VERSION "dbc-export 1 2026.26.6.5"

NS_ :

BS_:

BU_: ADSP APB APP APS APSB BB BMS CC CMP CMPD CP DAS DI DIF DIR DPB EPAS3P EPAS3S EPASTP EPASTS EPBL EPBR ESP EVSE FC GTW HCML HCMR HVP IBST ICR IDB LS OCS1P PARK PCS PCS2 PM PMF PMR PNCD PTC RADC RCM RCM2 RCM3 RCU SCCM SCM SCS SDCR TAS TCU TCU2 TPMS TRCM UI UIS UMC USM V2G VC VCBATT VCBATT0 VCBATT1 VCBATT2 VCCC VCFRONT VCFRONT1 VCFRONT2 VCLEFT VCRIGHT VCSEAT2L VCSEAT2R VCSEC VEH

BO_ 845 APSB_warningMatrix0: 8 APSB
 SG_ APSB_w001_DEPRECATED : 0|1@1+ (1,0) [0|1] "" Vector__XXX
 SG_ APSB_w002_ldwDisabled : 1|1@1+ (1,0) [0|1] "" Vector__XXX
 SG_ APSB_w003_isaDisabled : 2|1@1+ (1,0) [0|1] "" Vector__XXX
 SG_ APSB_w004_accDisabled : 3|1@1+ (1,0) [0|1] "" Vector__XXX
 SG_ APSB_w005_fcwCancelled : 4|1@1+ (1,0) [0|1] "" Vector__XXX
 SG_ APSB_w006_aebCancelled : 5|1@1+ (1,0) [0|1] "" Vector__XXX
 SG_ APSB_w007_ahlbDisabled : 6|1@1+ (1,0) [0|1] "" Vector__XXX
 SG_ APSB_w008_parkDisabled : 7|1@1+ (1,0) [0|1] "" Vector__XXX
 SG_ APSB_w009_aebFault : 8|1@1+ (1,0) [0|1] "" Vector__XXX
 SG_ APSB_w010_radcCalibIssue : 9|1@1+ (1,0) [0|1] "" Vector__XXX
 SG_ APSB_w011_scaEvent : 10|1@1+ (1,0) [0|1] "" Vector__XXX
 SG_ APSB_w012_Cam_BootFailure : 11|1@1+ (1,0) [0|1] "" Vector__XXX
 SG_ APSB_w013_Cam_Watchdog : 12|1@1+ (1,0) [0|1] "" Vector__XXX
 SG_ APSB_w014_swAssert : 13|1@1+ (1,0) [0|1] "" Vector__XXX
 SG_ APSB_w015_Camera_Failsafes : 14|1@1+ (1,0) [0|1] "" Vector__XXX
 SG_ APSB_w016_aeb_e_event : 15|1@1+ (1,0) [0|1] "" Vector__XXX
 SG_ APSB_w017_Cam_Msg_MIA : 16|1@1+ (1,0) [0|1] "" Vector__XXX
 SG_ APSB_w018_ECU_Power_Issue : 17|1@1+ (1,0) [0|1] "" Vector__XXX
 SG_ APSB_w019_ECU_Stack_Overflow : 18|1@1+ (1,0) [0|1] "" Vector__XXX
 SG_ APSB_w020_ECU_checkstopError : 19|1@1+ (1,0) [0|1] "" Vector__XXX
 SG_ APSB_w021_ECU_Temperature_Issue : 20|1@1+ (1,0) [0|1] "" Vector__XXX
 SG_ APSB_w022_ECU_EEPROM_Failure : 21|1@1+ (1,0) [0|1] "" Vector__XXX
 SG_ APSB_w023_ECU_Cam_Statemismatc : 22|1@1+ (1,0) [0|1] "" Vector__XXX
 SG_ APSB_w024_ECU_Watchdog_Reset : 23|1@1+ (1,0) [0|1] "" Vector__XXX
 SG_ APSB_w025_LC_Steering_Override : 24|1@1+ (1,0) [0|1] "" Vector__XXX
 SG_ APSB_w026_ECU_timingIssue : 25|1@1+ (1,0) [0|1] "" Vector__XXX
 SG_ APSB_w027_ECU_Reset_Fault : 26|1@1+ (1,0) [0|1] "" Vector__XXX
 SG_ APSB_w028_spi_rx_error : 27|1@1+ (1,0) [0|1] "" Vector__XXX
 SG_ APSB_w029_spi_tx_error : 28|1@1+ (1,0) [0|1] "" Vector__XXX
 SG_ APSB_w030_Heater_Issue : 29|1@1+ (1,0) [0|1] "" Vector__XXX
 SG_ APSB_w031_canRxError : 30|1@1+ (1,0) [0|1] "" Vector__XXX
 SG_ APSB_w032_canTxError : 31|1@1+ (1,0) [0|1] "" Vector__XXX
 SG_ APSB_w033_gtwMia : 32|1@1+ (1,0) [0|1] "" Vector__XXX
 SG_ APSB_w034_sccmMia : 33|1@1+ (1,0) [0|1] "" Vector__XXX
 SG_ APSB_w035_espMia : 34|1@1+ (1,0) [0|1] "" Vector__XXX
 SG_ APSB_w036_bdyMia : 35|1@1+ (1,0) [0|1] "" Vector__XXX
 SG_ APSB_w037_camTacIssue : 36|1@1+ (1,0) [0|1] "" Vector__XXX
 SG_ APSB_w038_camFailure : 37|1@1+ (1,0) [0|1] "" Vector__XXX
 SG_ APSB_w039_sdm_rcm_Mia : 38|1@1+ (1,0) [0|1] "" Vector__XXX
 SG_ APSB_w040_autopilotAngleSaturate : 39|1@1+ (1,0) [0|1] "" Vector__XXX
 SG_ APSB_w041_autopilotRateSaturated : 40|1@1+ (1,0) [0|1] "" Vector__XXX
 SG_ APSB_w042_autopilotAborting : 41|1@1+ (1,0) [0|1] "" Vector__XXX
 SG_ APSB_w043_camLongRunTime : 42|1@1+ (1,0) [0|1] "" Vector__XXX
 SG_ APSB_w044_appMobileyeFailure : 43|1@1+ (1,0) [0|1] "" Vector__XXX
 SG_ APSB_w045_radMia : 44|1@1+ (1,0) [0|1] "" Vector__XXX
 SG_ APSB_w046_eepromRecordAbsent : 45|1@1+ (1,0) [0|1] "" Vector__XXX
 SG_ APSB_w047_edrEvent : 46|1@1+ (1,0) [0|1] "" Vector__XXX
 SG_ APSB_w048_DAS_Features_Disabled : 47|1@1+ (1,0) [0|1] "" Vector__XXX
 SG_ APSB_w049_eyeqVersionMismatch : 48|1@1+ (1,0) [0|1] "" Vector__XXX
 SG_ APSB_w050_aeb_event : 49|1@1+ (1,0) [0|1] "" Vector__XXX
 SG_ APSB_w051_radcEcuIssue : 50|1@1+ (1,0) [0|1] "" Vector__XXX
 SG_ APSB_w052_radcSensorIssue : 51|1@1+ (1,0) [0|1] "" Vector__XXX
 SG_ APSB_w053_radcCommIssue : 52|1@1+ (1,0) [0|1] "" Vector__XXX
 SG_ APSB_w054_camAutofix : 53|1@1+ (1,0) [0|1] "" Vector__XXX
 SG_ APSB_w055_radcVersionMismatch : 54|1@1+ (1,0) [0|1] "" Vector__XXX
 SG_ APSB_w056_diMia : 55|1@1+ (1,0) [0|1] "" Vector__XXX
 SG_ APSB_w057_mcuMia : 56|1@1+ (1,0) [0|1] "" Vector__XXX
 SG_ APSB_w058_epbMia : 57|1@1+ (1,0) [0|1] "" Vector__XXX
 SG_ APSB_w059_parkMia : 58|1@1+ (1,0) [0|1] "" Vector__XXX
 SG_ APSB_w060_fcw_event : 59|1@1+ (1,0) [0|1] "" Vector__XXX
 SG_ APSB_w061_tasMia : 60|1@1+ (1,0) [0|1] "" Vector__XXX
 SG_ APSB_w062_radcAlignment : 61|1@1+ (1,0) [0|1] "" Vector__XXX
 SG_ APSB_w063_parkVersionMismatch : 62|1@1+ (1,0) [0|1] "" Vector__XXX
 SG_ APSB_w064_epasMia : 63|1@1+ (1,0) [0|1] "" Vector__XXX

BO_ 1143 APSB_warningMatrix1: 8 APSB
 SG_ APSB_w065_deserializerOvercurren : 0|1@1+ (1,0) [0|1] "" Vector__XXX
 SG_ APSB_w066_deserializerLockLost : 1|1@1+ (1,0) [0|1] "" Vector__XXX
 SG_ APSB_w067_steeringAlignment : 2|1@1+ (1,0) [0|1] "" Vector__XXX
 SG_ APSB_w068_vlInconsistency : 3|1@1+ (1,0) [0|1] "" Vector__XXX
 SG_ APSB_w069_apcSpaceMasked : 4|1@1+ (1,0) [0|1] "" Vector__XXX
 SG_ APSB_w070_apcIncompleteCal : 5|1@1+ (1,0) [0|1] "" Vector__XXX
 SG_ APSB_w071_selfparkStarted : 6|1@1+ (1,0) [0|1] "" Vector__XXX
 SG_ APSB_w072_selfparkComplete : 7|1@1+ (1,0) [0|1] "" Vector__XXX
 SG_ APSB_w073_issueEscalatedLDW : 8|1@1+ (1,0) [0|1] "" Vector__XXX
 SG_ APSB_w074_inPathStationaryObst : 9|1@1+ (1,0) [0|1] "" Vector__XXX
 SG_ APSB_w075_scMia : 10|1@1+ (1,0) [0|1] "" Vector__XXX
 SG_ APSB_w076_mobilEyeSetC : 11|1@1+ (1,0) [0|1] "" Vector__XXX
 SG_ APSB_w077_pmmActive : 12|1@1+ (1,0) [0|1] "" Vector__XXX
 SG_ APSB_w078_pmmActive2 : 13|1@1+ (1,0) [0|1] "" Vector__XXX
 SG_ APSB_w079_edrAvailable : 14|1@1+ (1,0) [0|1] "" Vector__XXX
 SG_ APSB_w080_accFailedActivation : 15|1@1+ (1,0) [0|1] "" Vector__XXX
 SG_ APSB_w081_pmmActiveBraking : 16|1@1+ (1,0) [0|1] "" Vector__XXX
 SG_ APSB_w082_inPathFSviolation : 17|1@1+ (1,0) [0|1] "" Vector__XXX
 SG_ APSB_w083_inPathRADObject : 18|1@1+ (1,0) [0|1] "" Vector__XXX
 SG_ APSB_w084_pmmIPSO : 19|1@1+ (1,0) [0|1] "" Vector__XXX
 SG_ APSB_w085_pmmSteering : 20|1@1+ (1,0) [0|1] "" Vector__XXX
 SG_ APSB_w086_robCollision : 21|1@1+ (1,0) [0|1] "" Vector__XXX
 SG_ APSB_w087_DEPRECATED : 22|1@1+ (1,0) [0|1] "" Vector__XXX
 SG_ APSB_w088_DEPRECATED : 23|1@1+ (1,0) [0|1] "" Vector__XXX
 SG_ APSB_w089_DEPRECATED : 24|1@1+ (1,0) [0|1] "" Vector__XXX
 SG_ APSB_w090_DEPRECATED : 25|1@1+ (1,0) [0|1] "" Vector__XXX
 SG_ APSB_w091_DEPRECATED : 26|1@1+ (1,0) [0|1] "" Vector__XXX
 SG_ APSB_w092_DEPRECATED : 27|1@1+ (1,0) [0|1] "" Vector__XXX
 SG_ APSB_w093_DEPRECATED : 28|1@1+ (1,0) [0|1] "" Vector__XXX
 SG_ APSB_w094_DEPRECATED : 29|1@1+ (1,0) [0|1] "" Vector__XXX
 SG_ APSB_w095_DEPRECATED : 30|1@1+ (1,0) [0|1] "" Vector__XXX
 SG_ APSB_w096_DEPRECATED : 31|1@1+ (1,0) [0|1] "" Vector__XXX
 SG_ APSB_w097_DEPRECATED : 32|1@1+ (1,0) [0|1] "" Vector__XXX
 SG_ APSB_w098_DEPRECATED : 33|1@1+ (1,0) [0|1] "" Vector__XXX
 SG_ APSB_w099_DEPRECATED : 34|1@1+ (1,0) [0|1] "" Vector__XXX
 SG_ APSB_w100_DEPRECATED : 35|1@1+ (1,0) [0|1] "" Vector__XXX
 SG_ APSB_w101_DEPRECATED : 36|1@1+ (1,0) [0|1] "" Vector__XXX
 SG_ APSB_w102_DEPRECATED : 37|1@1+ (1,0) [0|1] "" Vector__XXX
 SG_ APSB_w103_robExperimentalAEB : 38|1@1+ (1,0) [0|1] "" Vector__XXX
 SG_ APSB_w104_DEPRECATED : 39|1@1+ (1,0) [0|1] "" Vector__XXX
 SG_ APSB_w105_DEPRECATED : 40|1@1+ (1,0) [0|1] "" Vector__XXX
 SG_ APSB_w106_torsionBarOffset : 41|1@1+ (1,0) [0|1] "" Vector__XXX

BO_ 942 APSB_warningMatrix2: 8 APSB
 SG_ APSB_w129_ECU_Power_Issue : 0|1@1+ (1,0) [0|1] "" Vector__XXX
 SG_ APSB_w130_ECU_Thermal_Issue : 1|1@1+ (1,0) [0|1] "" Vector__XXX
 SG_ APSB_w131_trap_exception : 2|1@1+ (1,0) [0|1] "" Vector__XXX
 SG_ APSB_w132_appVersionMismatch : 3|1@1+ (1,0) [0|1] "" Vector__XXX
 SG_ APSB_w133_ETHSwitchError : 4|1@1+ (1,0) [0|1] "" Vector__XXX
 SG_ APSB_w134_appMia : 5|1@1+ (1,0) [0|1] "" Vector__XXX
 SG_ APSB_w135_appCritical : 6|1@1+ (1,0) [0|1] "" Vector__XXX
 SG_ APSB_w136_gpsDisabled : 7|1@1+ (1,0) [0|1] "" Vector__XXX
 SG_ APSB_w137_gpsFaultReset : 8|1@1+ (1,0) [0|1] "" Vector__XXX
 SG_ APSB_w138_gpsComIssue : 9|1@1+ (1,0) [0|1] "" Vector__XXX
 SG_ APSB_w139_udpBufferOverflow : 10|1@1+ (1,0) [0|1] "" Vector__XXX
 SG_ APSB_w140_vcfrontMiaVehicleBus : 11|1@1+ (1,0) [0|1] "" Vector__XXX
 SG_ APSB_w141_rcmMiaPartyBus : 12|1@1+ (1,0) [0|1] "" Vector__XXX
 SG_ APSB_w142_diMiaPartyBus : 13|1@1+ (1,0) [0|1] "" Vector__XXX
 SG_ APSB_w143_espMiaPartyBus : 14|1@1+ (1,0) [0|1] "" Vector__XXX
 SG_ APSB_w144_vcleftMiaPartyBus : 15|1@1+ (1,0) [0|1] "" Vector__XXX
 SG_ APSB_w145_vcrightMiaPartyBus : 16|1@1+ (1,0) [0|1] "" Vector__XXX
 SG_ APSB_w146_epas3pMiaPartyBus : 17|1@1+ (1,0) [0|1] "" Vector__XXX
 SG_ APSB_w147_vcleftMiaVehBus : 18|1@1+ (1,0) [0|1] "" Vector__XXX
 SG_ APSB_w148_vcrightMiaVehBus : 19|1@1+ (1,0) [0|1] "" Vector__XXX
 SG_ APSB_w149_epblMiaVehBus : 20|1@1+ (1,0) [0|1] "" Vector__XXX
 SG_ APSB_w150_sccmMiaVehBus : 21|1@1+ (1,0) [0|1] "" Vector__XXX
 SG_ APSB_w151_apRecovered : 22|1@1+ (1,0) [0|1] "" Vector__XXX
 SG_ APSB_w152_gpsFusionStatus : 23|1@1+ (1,0) [0|1] "" Vector__XXX
 SG_ APSB_w153_eacInhibit : 24|1@1+ (1,0) [0|1] "" Vector__XXX
 SG_ APSB_w155_ethLwipError : 26|1@1+ (1,0) [0|1] "" Vector__XXX
 SG_ APSB_w156_lwipAssert : 27|1@1+ (1,0) [0|1] "" Vector__XXX
 SG_ APSB_w157_autopilotReboot : 28|1@1+ (1,0) [0|1] "" Vector__XXX
 SG_ APSB_w158_apbMia : 29|1@1+ (1,0) [0|1] "" Vector__XXX
 SG_ APSB_w159_apbCritical : 30|1@1+ (1,0) [0|1] "" Vector__XXX
 SG_ APSB_w160_apbVersionMismatch : 31|1@1+ (1,0) [0|1] "" Vector__XXX
 SG_ APSB_w161_gpsAntennaDisconnected : 32|1@1+ (1,0) [0|1] "" Vector__XXX
 SG_ APSB_w162_TurboA_DisRegPgoodErr : 33|1@1+ (1,0) [0|1] "" Vector__XXX
 SG_ APSB_w163_TurboA_DisRegNFault : 34|1@1+ (1,0) [0|1] "" Vector__XXX
 SG_ APSB_w164_TurboA_12VFuseFault : 35|1@1+ (1,0) [0|1] "" Vector__XXX
 SG_ APSB_w165_TurboA_Temp_NOS : 36|1@1+ (1,0) [0|1] "" Vector__XXX
 SG_ APSB_w166_TurboA_SMSLockStepErr : 37|1@1+ (1,0) [0|1] "" Vector__XXX
 SG_ APSB_w167_TurboA_TMU_Throttle : 38|1@1+ (1,0) [0|1] "" Vector__XXX
 SG_ APSB_w168_TurboA_SMS_WDOG : 39|1@1+ (1,0) [0|1] "" Vector__XXX
 SG_ APSB_w169_TurboA_SCS_LKUP : 40|1@1+ (1,0) [0|1] "" Vector__XXX
 SG_ APSB_w170_TurboA_A72_watchdog : 41|1@1+ (1,0) [0|1] "" Vector__XXX
 SG_ APSB_w171_TurboA_SMS_taskUtilErr : 42|1@1+ (1,0) [0|1] "" Vector__XXX
 SG_ APSB_w172_apFeaturesUnavailable : 43|1@1+ (1,0) [0|1] "" Vector__XXX
 SG_ APSB_w178_TurboB_DisRegPgoodErr : 49|1@1+ (1,0) [0|1] "" Vector__XXX
 SG_ APSB_w179_TurboB_DisRegNFault : 50|1@1+ (1,0) [0|1] "" Vector__XXX
 SG_ APSB_w180_TurboB_12VFuseFault : 51|1@1+ (1,0) [0|1] "" Vector__XXX
 SG_ APSB_w181_TurboB_Temp_NOS : 52|1@1+ (1,0) [0|1] "" Vector__XXX
 SG_ APSB_w182_TurboB_SMSLockStepErr : 53|1@1+ (1,0) [0|1] "" Vector__XXX
 SG_ APSB_w183_TurboB_TMU_Throttle : 54|1@1+ (1,0) [0|1] "" Vector__XXX
 SG_ APSB_w184_TurboB_SMS_WDOG : 55|1@1+ (1,0) [0|1] "" Vector__XXX
 SG_ APSB_w185_TurboB_SCS_LKUP : 56|1@1+ (1,0) [0|1] "" Vector__XXX
 SG_ APSB_w186_TurboB_A72_watchdog : 57|1@1+ (1,0) [0|1] "" Vector__XXX
 SG_ APSB_w187_TurboB_SMS_taskUtilErr : 58|1@1+ (1,0) [0|1] "" Vector__XXX
 SG_ APSB_w188_otherTurboUartMIA : 59|1@1+ (1,0) [0|1] "" Vector__XXX
 SG_ APSB_w189_vcfrontMiaPartyBus : 60|1@1+ (1,0) [0|1] "" Vector__XXX
 SG_ APSB_w190_iboosterMia : 61|1@1+ (1,0) [0|1] "" Vector__XXX
 SG_ APSB_w191_timesyncError : 62|1@1+ (1,0) [0|1] "" Vector__XXX
 SG_ APSB_w192_CANFault : 63|1@1+ (1,0) [0|1] "" Vector__XXX

BO_ 976 APSB_warningMatrix3: 8 APSB
 SG_ APSB_w193_camWindshieldUnclean : 0|1@1+ (1,0) [0|1] "" Vector__XXX
 SG_ APSB_w194_accDriverResumeRqrd : 1|1@1+ (1,0) [0|1] "" Vector__XXX
 SG_ APSB_w195_scwUnavailable : 2|1@1+ (1,0) [0|1] "" Vector__XXX
 SG_ APSB_w196_stopSignWarning : 3|1@1+ (1,0) [0|1] "" Vector__XXX
 SG_ APSB_w197_redLightWarning : 4|1@1+ (1,0) [0|1] "" Vector__XXX
 SG_ APSB_w198_tsrUnavailable : 5|1@1+ (1,0) [0|1] "" Vector__XXX
 SG_ APSB_w199_apcAbort : 6|1@1+ (1,0) [0|1] "" Vector__XXX
 SG_ APSB_w200_lcSlowdown : 7|1@1+ (1,0) [0|1] "" Vector__XXX
 SG_ APSB_w201_lcAborting : 8|1@1+ (1,0) [0|1] "" Vector__XXX
 SG_ APSB_w202_scwNoisyEnvironment : 9|1@1+ (1,0) [0|1] "" Vector__XXX
 SG_ APSB_w203_apcActivation : 10|1@1+ (1,0) [0|1] "" Vector__XXX
 SG_ APSB_w204_apcFinalFront : 11|1@1+ (1,0) [0|1] "" Vector__XXX
 SG_ APSB_w205_apcFinalRear : 12|1@1+ (1,0) [0|1] "" Vector__XXX
 SG_ APSB_w206_autosteerNotEnabled : 13|1@1+ (1,0) [0|1] "" Vector__XXX
 SG_ APSB_w207_autosteerUnavailable : 14|1@1+ (1,0) [0|1] "" Vector__XXX
 SG_ APSB_w208_rackDetected : 15|1@1+ (1,0) [0|1] "" Vector__XXX
 SG_ APSB_w209_autoSummonRequest : 16|1@1+ (1,0) [0|1] "" Vector__XXX
 SG_ APSB_w210_camObstrcted : 17|1@1+ (1,0) [0|1] "" Vector__XXX
 SG_ APSB_w211_accNoSeatBelt : 18|1@1+ (1,0) [0|1] "" Vector__XXX
 SG_ APSB_w212_lcUnavailableStrikeOut : 19|1@1+ (1,0) [0|1] "" Vector__XXX
 SG_ APSB_w213_autosteerStruckOut : 20|1@1+ (1,0) [0|1] "" Vector__XXX
 SG_ APSB_w214_driverNotIntracting : 21|1@1+ (1,0) [0|1] "" Vector__XXX
 SG_ APSB_w215_contDriverNotIntractin : 22|1@1+ (1,0) [0|1] "" Vector__XXX
 SG_ APSB_w216_driverOverriding : 23|1@1+ (1,0) [0|1] "" Vector__XXX
 SG_ APSB_w217_lcUnavailableSpeeding : 24|1@1+ (1,0) [0|1] "" Vector__XXX
 SG_ APSB_w218_lcSpeedExceededLimit : 25|1@1+ (1,0) [0|1] "" Vector__XXX
 SG_ APSB_w219_lcTempUnavailableSpeed : 26|1@1+ (1,0) [0|1] "" Vector__XXX
 SG_ APSB_w220_lcTempUnavailableRoad : 27|1@1+ (1,0) [0|1] "" Vector__XXX
 SG_ APSB_w221_accRadarBlind : 28|1@1+ (1,0) [0|1] "" Vector__XXX
 SG_ APSB_w222_accCameraBlind : 29|1@1+ (1,0) [0|1] "" Vector__XXX
 SG_ APSB_w223_accObjectInPath : 30|1@1+ (1,0) [0|1] "" Vector__XXX
 SG_ APSB_w224_accCameraCalibration : 31|1@1+ (1,0) [0|1] "" Vector__XXX
 SG_ APSB_w225_lcDegradedVisSpeedLmt : 32|1@1+ (1,0) [0|1] "" Vector__XXX
 SG_ APSB_w226_lcCamCalNeededSpeedLmt : 33|1@1+ (1,0) [0|1] "" Vector__XXX
 SG_ APSB_w227_virtualWallBlocked : 34|1@1+ (1,0) [0|1] "" Vector__XXX
 SG_ APSB_w228_DEPRECATED : 35|1@1+ (1,0) [0|1] "" Vector__XXX
 SG_ APSB_w229_alcUltrasoundDamaged : 36|1@1+ (1,0) [0|1] "" Vector__XXX
 SG_ APSB_w230_alcUltrasoundBlocked : 37|1@1+ (1,0) [0|1] "" Vector__XXX
 SG_ APSB_w231_idfEvent : 38|1@1+ (1,0) [0|1] "" Vector__XXX
 SG_ APSB_w232_laneChangeRequested : 39|1@1+ (1,0) [0|1] "" Vector__XXX
 SG_ APSB_w235_a72LoopDetected : 42|1@1+ (1,0) [0|1] "" Vector__XXX
 SG_ APSB_w236_canSharedMemError : 43|1@1+ (1,0) [0|1] "" Vector__XXX
 SG_ APSB_w237_faultMgrEventDetected : 44|1@1+ (1,0) [0|1] "" Vector__XXX
 SG_ APSB_w238_resetReason : 45|1@1+ (1,0) [0|1] "" Vector__XXX
 SG_ APSB_w241_ddrInitFailures : 48|1@1+ (1,0) [0|1] "" Vector__XXX
 SG_ APSB_w242_tripMBISTFailure : 49|1@1+ (1,0) [0|1] "" Vector__XXX
 SG_ APSB_w243_tripHWErrorStatus : 50|1@1+ (1,0) [0|1] "" Vector__XXX
 SG_ APSB_w244_gpuHWFaultStatus : 51|1@1+ (1,0) [0|1] "" Vector__XXX
 SG_ APSB_w245_eloopRxFromUnexpectedS : 52|1@1+ (1,0) [0|1] "" Vector__XXX
 SG_ APSB_w246_ethloopSwitchPortLinkD : 53|1@1+ (1,0) [0|1] "" Vector__XXX
 SG_ APSB_w247_ethernetFrameError : 54|1@1+ (1,0) [0|1] "" Vector__XXX
 SG_ APSB_w248_ethloopSwitchPoorSqi : 55|1@1+ (1,0) [0|1] "" Vector__XXX
 SG_ APSB_w249_ufsFailures : 56|1@1+ (1,0) [0|1] "" Vector__XXX
 SG_ APSB_w250_ethloopSwitchMemUsageT : 57|1@1+ (1,0) [0|1] "" Vector__XXX
 SG_ APSB_w251_ethloopSwitchMemUsageT : 58|1@1+ (1,0) [0|1] "" Vector__XXX
 SG_ APSB_w252_ethSwitchPortLinkDown : 59|1@1+ (1,0) [0|1] "" Vector__XXX
 SG_ APSB_w253_powerStateTimeout : 60|1@1+ (1,0) [0|1] "" Vector__XXX
 SG_ APSB_w254_sleepStateTimeout : 61|1@1+ (1,0) [0|1] "" Vector__XXX
 SG_ APSB_w255_bootHealth : 62|1@1+ (1,0) [0|1] "" Vector__XXX

BO_ 1003 APSB_warningMatrix4: 8 APSB
 SG_ APSB_w257_assertFailure : 0|1@1+ (1,0) [0|1] "" Vector__XXX
 SG_ APSB_w258_qspiFlashSectorChecksu : 1|1@1+ (1,0) [0|1] "" Vector__XXX
 SG_ APSB_w259_qspiFailure : 2|1@1+ (1,0) [0|1] "" Vector__XXX
 SG_ APSB_w260_pgoodFailure : 3|1@1+ (1,0) [0|1] "" Vector__XXX
 SG_ APSB_w261_vrmFaultGrpA : 4|1@1+ (1,0) [0|1] "" Vector__XXX
 SG_ APSB_w262_vrmFaultGrpB : 5|1@1+ (1,0) [0|1] "" Vector__XXX
 SG_ APSB_w263_vrmFaultGrpC : 6|1@1+ (1,0) [0|1] "" Vector__XXX
 SG_ APSB_w264_ddrPhy0Failures : 7|1@1+ (1,0) [0|1] "" Vector__XXX
 SG_ APSB_w265_ddrPhy1Failures : 8|1@1+ (1,0) [0|1] "" Vector__XXX
 SG_ APSB_w266_ddrPhy2Failures : 9|1@1+ (1,0) [0|1] "" Vector__XXX
 SG_ APSB_w267_ddrPhy3Failures : 10|1@1+ (1,0) [0|1] "" Vector__XXX
 SG_ APSB_w268_ddrControllerFailures : 11|1@1+ (1,0) [0|1] "" Vector__XXX
 SG_ APSB_w269_ethSwitchRxPageCountTo : 12|1@1+ (1,0) [0|1] "" Vector__XXX
 SG_ APSB_w270_ethSwitchRxPageCountTo : 13|1@1+ (1,0) [0|1] "" Vector__XXX
 SG_ APSB_w271_ddrScheduler0EccErrors : 14|1@1+ (1,0) [0|1] "" Vector__XXX
 SG_ APSB_w272_ddrScheduler1EccErrors : 15|1@1+ (1,0) [0|1] "" Vector__XXX
 SG_ APSB_w273_ddrScheduler2EccErrors : 16|1@1+ (1,0) [0|1] "" Vector__XXX
 SG_ APSB_w274_ddrScheduler3EccErrors : 17|1@1+ (1,0) [0|1] "" Vector__XXX
 SG_ APSB_w275_ddrScheduler4EccErrors : 18|1@1+ (1,0) [0|1] "" Vector__XXX
 SG_ APSB_w276_ddrScheduler5EccErrors : 19|1@1+ (1,0) [0|1] "" Vector__XXX
 SG_ APSB_w277_ddrScheduler6EccErrors : 20|1@1+ (1,0) [0|1] "" Vector__XXX
 SG_ APSB_w278_ddrScheduler7EccErrors : 21|1@1+ (1,0) [0|1] "" Vector__XXX
 SG_ APSB_w279_ufsPartitionError : 22|1@1+ (1,0) [0|1] "" Vector__XXX
 SG_ APSB_w280_pepsMia : 23|1@1+ (1,0) [0|1] "" Vector__XXX
 SG_ APSB_w281_rsaMia : 24|1@1+ (1,0) [0|1] "" Vector__XXX
 SG_ APSB_w282_smmuError : 25|1@1+ (1,0) [0|1] "" Vector__XXX
 SG_ APSB_w283_psfaMia : 26|1@1+ (1,0) [0|1] "" Vector__XXX
 SG_ APSB_w284_cam12VBuckBoostAPwrIss : 27|1@1+ (1,0) [0|1] "" Vector__XXX
 SG_ APSB_w285_cam12VBuckBoostBPwrIss : 28|1@1+ (1,0) [0|1] "" Vector__XXX
 SG_ APSB_w286_cam12VEFuseAPrimaryIss : 29|1@1+ (1,0) [0|1] "" Vector__XXX
 SG_ APSB_w287_cam12VEFuseASecondaryI : 30|1@1+ (1,0) [0|1] "" Vector__XXX
 SG_ APSB_w288_brakeboosterMia : 31|1@1+ (1,0) [0|1] "" Vector__XXX
 SG_ APSB_w289_turboTemperatureWarnin : 32|1@1+ (1,0) [0|1] "" Vector__XXX
 SG_ APSB_w290_cam12VBuckBoostBPwrRin : 33|1@1+ (1,0) [0|1] "" Vector__XXX
 SG_ APSB_w291_eplannerError : 34|1@1+ (1,0) [0|1] "" Vector__XXX
 SG_ APSB_w292_CH_busOff : 35|1@1+ (1,0) [0|1] "" Vector__XXX
 SG_ APSB_w293_PARTY_busOff : 36|1@1+ (1,0) [0|1] "" Vector__XXX
 SG_ APSB_w294_VEH_busOff : 37|1@1+ (1,0) [0|1] "" Vector__XXX
 SG_ APSB_w295_PT_busOff : 38|1@1+ (1,0) [0|1] "" Vector__XXX
 SG_ APSB_w296_wdogMonTaskDeadlineMis : 39|1@1+ (1,0) [0|1] "" Vector__XXX
 SG_ APSB_w297_earlyWDogAlert : 40|1@1+ (1,0) [0|1] "" Vector__XXX
 SG_ APSB_w298_cpuToApCanSharedMemErr : 41|1@1+ (1,0) [0|1] "" Vector__XXX
 SG_ APSB_w299_apToCpuCanSharedMemErr : 42|1@1+ (1,0) [0|1] "" Vector__XXX
 SG_ APSB_w300_sharedMemoryAccessErro : 43|1@1+ (1,0) [0|1] "" Vector__XXX
 SG_ APSB_w301_nocTimeoutDetected : 44|1@1+ (1,0) [0|1] "" Vector__XXX
 SG_ APSB_w302_canAPShmFifoFull : 45|1@1+ (1,0) [0|1] "" Vector__XXX
 SG_ APSB_w303_canAPShmFifoEmpty : 46|1@1+ (1,0) [0|1] "" Vector__XXX
 SG_ APSB_w304_dataAbort : 47|1@1+ (1,0) [0|1] "" Vector__XXX
 SG_ APSB_w305_gpsPgoodFailure : 48|1@1+ (1,0) [0|1] "" Vector__XXX
 SG_ APSB_w306_ethPgoodFailure : 49|1@1+ (1,0) [0|1] "" Vector__XXX
 SG_ APSB_w307_eccEventDetected : 50|1@1+ (1,0) [0|1] "" Vector__XXX
 SG_ APSB_w308_pmicErrorDetected : 51|1@1+ (1,0) [0|1] "" Vector__XXX
 SG_ APSB_w309_ethBridgeDown : 52|1@1+ (1,0) [0|1] "" Vector__XXX
 SG_ APSB_w310_wakeBootMetrics : 53|1@1+ (1,0) [0|1] "" Vector__XXX
 SG_ APSB_w311_apbdgDasMia : 54|1@1+ (1,0) [0|1] "" Vector__XXX
 SG_ APSB_w312_apbdgApMia : 55|1@1+ (1,0) [0|1] "" Vector__XXX
 SG_ APSB_w313_BDY_busOff : 56|1@1+ (1,0) [0|1] "" Vector__XXX
 SG_ APSB_w315_epas3pMiaBdyBus : 58|1@1+ (1,0) [0|1] "" Vector__XXX
 SG_ APSB_w316_apBootHealth : 59|1@1+ (1,0) [0|1] "" Vector__XXX
 SG_ APSB_w317_uiMia : 60|1@1+ (1,0) [0|1] "" Vector__XXX
 SG_ APSB_w318_ethernetNetworkBufferH : 61|1@1+ (1,0) [0|1] "" Vector__XXX
 SG_ APSB_w319_vehDasImposterDetected : 62|1@1+ (1,0) [0|1] "" Vector__XXX
 SG_ APSB_w320_eplannerPreconditionsM : 63|1@1+ (1,0) [0|1] "" Vector__XXX

BO_ 1481 APS_alertLog: 8 APS
 SG_ APS_alertID M : 0|14@1+ (1,0) [0|16383] "" Vector__XXX
 SG_ APS_alertSource : 14|1@1+ (1,0) [0|1] "" Vector__XXX
 SG_ APS_alertState : 15|1@1+ (1,0) [0|1] "" Vector__XXX
 SG_ APS_sw010_a04calibNotDone m10 : 16|1@1+ (1,0) [0|1] "" Vector__XXX
 SG_ APS_sw010_a05calibReqd m10 : 17|1@1+ (1,0) [0|1] "" Vector__XXX
 SG_ APS_sw010_a06calibNotOK m10 : 18|1@1+ (1,0) [0|1] "" Vector__XXX
 SG_ APS_sw010_a08PlantMode m10 : 19|1@1+ (1,0) [0|1] "" Vector__XXX
 SG_ APS_sw010_HorizontalMisalignment m10 : 20|16@1+ (0.00137332,-45) [-45|45.0005262] "" Vector__XXX
 SG_ APS_sw010_VerticalMisalignment m10 : 36|10@1+ (0.087977,-45) [-45|45.000471] "" Vector__XXX
 SG_ APS_sw010_unusedBits m10 : 46|2@1+ (1,0) [0|3] "" Vector__XXX
 SG_ APS_sw010_VmaPlausibility m10 : 48|16@1+ (1.52587890625e-05,0) [0|0.999984741211] "" Vector__XXX
 SG_ APS_sw019_taskId m19 : 16|8@1+ (1,0) [0|255] "" Vector__XXX
 SG_ APS_sw019_numFreeBytes m19 : 24|8@1+ (1,-191) [-191|64] "" Vector__XXX
 SG_ APS_sw019_timeStamp m19 : 32|32@1+ (1,0) [0|4294967295] "" Vector__XXX
 SG_ APS_sw020_unusedW0 m20 : 16|16@1+ (1,0) [0|65535] "" Vector__XXX
 SG_ APS_sw020_unusedW1 m20 : 32|16@1+ (1,0) [0|65535] "" Vector__XXX
 SG_ APS_sw020_unusedW2 m20 : 48|16@1+ (1,0) [0|65535] "" Vector__XXX
 SG_ APS_sw021_tempSensorId m21 : 16|8@1+ (1,0) [0|255] "" Vector__XXX
 SG_ APS_sw021_minThreshold m21 : 24|8@1- (1,0) [-128|127] "" Vector__XXX
 SG_ APS_sw021_maxThreshold m21 : 32|8@1- (1,0) [-128|127] "" Vector__XXX
 SG_ APS_sw021_currentTemperature m21 : 40|8@1- (1,0) [-128|127] "" Vector__XXX
 SG_ APS_sw021_unusedWord m21 : 48|16@1+ (1,0) [0|65535] "" Vector__XXX
 SG_ APS_sw024_Task_ID m24 : 16|4@1+ (1,0) [0|15] "" Vector__XXX
 SG_ APS_sw024_numVirtualLaneVeh m24 : 20|4@1+ (1,0) [0|15] "" Vector__XXX
 SG_ APS_sw024_currentVehicleApp m24 : 24|8@1+ (1,0) [0|255] "" Vector__XXX
 SG_ APS_sw024_taskProgramCounter m24 : 32|32@1+ (1,0) [0|4294967295] "" Vector__XXX
 SG_ APS_sw027_JTAG_Reset m27 : 16|1@1+ (1,0) [0|1] "" Vector__XXX
 SG_ APS_sw027_Core_Reset m27 : 17|1@1+ (1,0) [0|1] "" Vector__XXX
 SG_ APS_sw027_Unused_Bit_0 m27 : 18|1@1+ (1,0) [0|1] "" Vector__XXX
 SG_ APS_sw027_CPU_Checkstop_Error m27 : 19|1@1+ (1,0) [0|1] "" Vector__XXX
 SG_ APS_sw027_PLL_0_Failure m27 : 20|1@1+ (1,0) [0|1] "" Vector__XXX
 SG_ APS_sw027_Clock_Monitor_0_Low m27 : 21|1@1+ (1,0) [0|1] "" Vector__XXX
 SG_ APS_sw027_Clock_Monitor_0_Off m27 : 22|1@1+ (1,0) [0|1] "" Vector__XXX
 SG_ APS_sw027_LVD_4v5 m27 : 23|1@1+ (1,0) [0|1] "" Vector__XXX
 SG_ APS_sw027_Flash_Fatal_Error m27 : 24|1@1+ (1,0) [0|1] "" Vector__XXX
 SG_ APS_sw027_PLL_1_Failure m27 : 25|1@1+ (1,0) [0|1] "" Vector__XXX
 SG_ APS_sw027_Unused_Bit_1 m27 : 26|1@1+ (1,0) [0|1] "" Vector__XXX
 SG_ APS_sw027_f_PLL_1_Off m27 : 27|1@1+ (1,0) [0|1] "" Vector__XXX
 SG_ APS_sw027_Unused_Nibble m27 : 28|4@1+ (1,0) [0|15] "" Vector__XXX
 SG_ APS_sw027_LVD_1v2 m27 : 32|1@1+ (1,0) [0|1] "" Vector__XXX
 SG_ APS_sw027_Unused_Bit_2 m27 : 33|1@1+ (1,0) [0|1] "" Vector__XXX
 SG_ APS_sw027_Watchdog m27 : 34|1@1+ (1,0) [0|1] "" Vector__XXX
 SG_ APS_sw027_Unused_Bit_3 m27 : 35|1@1+ (1,0) [0|1] "" Vector__XXX
 SG_ APS_sw027_LVD_2v7_VREG m27 : 36|1@1+ (1,0) [0|1] "" Vector__XXX
 SG_ APS_sw027_LVD_2v7_Flash m27 : 37|1@1+ (1,0) [0|1] "" Vector__XXX
 SG_ APS_sw027_LVD_2v7_IO m27 : 38|1@1+ (1,0) [0|1] "" Vector__XXX
 SG_ APS_sw027_Unused_Bit_4 m27 : 39|1@1+ (1,0) [0|1] "" Vector__XXX
 SG_ APS_sw027_Unused_Byte m27 : 40|8@1+ (1,0) [0|255] "" Vector__XXX
 SG_ APS_sw027_ESR0 m27 : 48|1@1+ (1,0) [0|1] "" Vector__XXX
 SG_ APS_sw027_ESR1 m27 : 49|1@1+ (1,0) [0|1] "" Vector__XXX
 SG_ APS_sw027_SW m27 : 50|1@1+ (1,0) [0|1] "" Vector__XXX
 SG_ APS_sw027_STM0 m27 : 51|1@1+ (1,0) [0|1] "" Vector__XXX
 SG_ APS_sw027_STM1 m27 : 52|1@1+ (1,0) [0|1] "" Vector__XXX
 SG_ APS_sw027_STM2 m27 : 53|1@1+ (1,0) [0|1] "" Vector__XXX
 SG_ APS_sw027_CBS_SYSTEM m27 : 54|1@1+ (1,0) [0|1] "" Vector__XXX
 SG_ APS_sw027_CBS_DEBUG m27 : 55|1@1+ (1,0) [0|1] "" Vector__XXX
 SG_ APS_sw027_CBS_APP m27 : 56|1@1+ (1,0) [0|1] "" Vector__XXX
 SG_ APS_sw027_EVR13 m27 : 57|1@1+ (1,0) [0|1] "" Vector__XXX
 SG_ APS_sw027_EVR33 m27 : 58|1@1+ (1,0) [0|1] "" Vector__XXX
 SG_ APS_sw027_SWD m27 : 59|1@1+ (1,0) [0|1] "" Vector__XXX
 SG_ APS_sw027_STDBY_WDG m27 : 60|1@1+ (1,0) [0|1] "" Vector__XXX
 SG_ APS_sw027_PORST m27 : 61|1@1+ (1,0) [0|1] "" Vector__XXX
 SG_ APS_sw027_Unused_word m27 : 62|2@1+ (1,0) [0|3] "" Vector__XXX
 SG_ APS_sw030_heaterState m30 : 16|8@1+ (1,0) [0|255] "" Vector__XXX
 SG_ APS_sw030_unusedByte m30 : 24|8@1+ (1,0) [0|255] "" Vector__XXX
 SG_ APS_sw030_unusedW0 m30 : 32|16@1+ (1,0) [0|65535] "" Vector__XXX
 SG_ APS_sw030_unusedW1 m30 : 48|16@1+ (1,0) [0|65535] "" Vector__XXX
 SG_ APS_sw033_carConfig m33 : 16|1@1+ (1,0) [0|1] "" Vector__XXX
 SG_ APS_sw033_chNm m33 : 17|1@1+ (1,0) [0|1] "" Vector__XXX
 SG_ APS_sw033_vin m33 : 18|1@1+ (1,0) [0|1] "" Vector__XXX
 SG_ APS_sw033_carState m33 : 19|1@1+ (1,0) [0|1] "" Vector__XXX
 SG_ APS_sw034_sccmMia m34 : 16|8@1+ (1,0) [0|255] "" Vector__XXX
 SG_ APS_sw034_unusedByte m34 : 24|8@1+ (1,0) [0|255] "" Vector__XXX
 SG_ APS_sw034_unusedW0 m34 : 32|16@1+ (1,0) [0|65535] "" Vector__XXX
 SG_ APS_sw034_unusedW1 m34 : 48|16@1+ (1,0) [0|65535] "" Vector__XXX
 SG_ APS_sw035_wheelSpeeds m35 : 16|1@1+ (1,0) [0|1] "" Vector__XXX
 SG_ APS_sw035_status m35 : 17|1@1+ (1,0) [0|1] "" Vector__XXX
 SG_ APS_sw035_wheelRotation m35 : 18|1@1+ (1,0) [0|1] "" Vector__XXX
 SG_ APS_sw035_redundantBrakingStatus m35 : 19|1@1+ (1,0) [0|1] "" Vector__XXX
 SG_ APS_sw036_bdyMia m36 : 16|8@1+ (1,0) [0|255] "" Vector__XXX
 SG_ APS_sw036_unusedByte m36 : 24|8@1+ (1,0) [0|255] "" Vector__XXX
 SG_ APS_sw036_unusedW0 m36 : 32|16@1+ (1,0) [0|65535] "" Vector__XXX
 SG_ APS_sw036_unusedW1 m36 : 48|16@1+ (1,0) [0|65535] "" Vector__XXX
 SG_ APS_sw039_sdm_rcm_Mia m39 : 16|8@1+ (1,0) [0|255] "" Vector__XXX
 SG_ APS_sw039_unusedByte m39 : 24|8@1+ (1,0) [0|255] "" Vector__XXX
 SG_ APS_sw039_unusedW0 m39 : 32|16@1+ (1,0) [0|65535] "" Vector__XXX
 SG_ APS_sw039_unusedW1 m39 : 48|16@1+ (1,0) [0|65535] "" Vector__XXX
 SG_ APS_sw045_radMia m45 : 16|8@1+ (1,0) [0|255] "" Vector__XXX
 SG_ APS_sw045_unusedByte m45 : 24|8@1+ (1,0) [0|255] "" Vector__XXX
 SG_ APS_sw045_unusedW0 m45 : 32|16@1+ (1,0) [0|65535] "" Vector__XXX
 SG_ APS_sw045_unusedW1 m45 : 48|16@1+ (1,0) [0|65535] "" Vector__XXX
 SG_ APS_sw048_swAssert m48 : 16|1@1+ (1,0) [0|1] "" Vector__XXX
 SG_ APS_sw048_thermalIssue m48 : 17|1@1+ (1,0) [0|1] "" Vector__XXX
 SG_ APS_sw048_powerIssue m48 : 18|1@1+ (1,0) [0|1] "" Vector__XXX
 SG_ APS_sw048_stackOverflow m48 : 19|1@1+ (1,0) [0|1] "" Vector__XXX
 SG_ APS_sw048_checkStop m48 : 20|1@1+ (1,0) [0|1] "" Vector__XXX
 SG_ APS_sw048_ecuWatchdog m48 : 21|1@1+ (1,0) [0|1] "" Vector__XXX
 SG_ APS_sw048_ecuReset m48 : 22|1@1+ (1,0) [0|1] "" Vector__XXX
 SG_ APS_sw048_radcVersionMismatch m48 : 23|1@1+ (1,0) [0|1] "" Vector__XXX
 SG_ APS_sw048_radcCalibration m48 : 24|1@1+ (1,0) [0|1] "" Vector__XXX
 SG_ APS_sw048_radcMia m48 : 25|1@1+ (1,0) [0|1] "" Vector__XXX
 SG_ APS_sw048_eyeQVersionMismatch m48 : 26|1@1+ (1,0) [0|1] "" Vector__XXX
 SG_ APS_sw048_camIssue m48 : 27|1@1+ (1,0) [0|1] "" Vector__XXX
 SG_ APS_sw048_parkerIssue m48 : 28|1@1+ (1,0) [0|1] "" Vector__XXX
 SG_ APS_sw048_prolongedUiMia m48 : 29|1@1+ (1,0) [0|1] "" Vector__XXX
 SG_ APS_sw048_uiMiaAtBootup m48 : 30|1@1+ (1,0) [0|1] "" Vector__XXX
 SG_ APS_sw051_a01ecuInternalPerf m51 : 16|1@1+ (1,0) [0|1] "" Vector__XXX
 SG_ APS_sw051_a02flashPerformance m51 : 17|1@1+ (1,0) [0|1] "" Vector__XXX
 SG_ APS_sw051_a03vBatHigh m51 : 18|1@1+ (1,0) [0|1] "" Vector__XXX
 SG_ APS_sw051_a09configMismatch m51 : 19|1@1+ (1,0) [0|1] "" Vector__XXX
 SG_ APS_sw051_a52radomeHtrInop m51 : 20|1@1+ (1,0) [0|1] "" Vector__XXX
 SG_ APS_sw051_unused m51 : 21|3@1+ (1,0) [0|7] "" Vector__XXX
 SG_ APS_sw051_SCUTemperature m51 : 24|8@1- (1,0) [-128|127] "" Vector__XXX
 SG_ APS_sw051_HWFail m51 : 32|1@1+ (1,0) [0|1] "" Vector__XXX
 SG_ APS_sw051_SGUFail m51 : 33|1@1+ (1,0) [0|1] "" Vector__XXX
 SG_ APS_sw051_unusedBits m51 : 34|6@1+ (1,0) [0|63] "" Vector__XXX
 SG_ APS_sw051_unusedB0 m51 : 40|8@1+ (1,0) [0|255] "" Vector__XXX
 SG_ APS_sw051_unusedW1 m51 : 48|16@1+ (1,0) [0|65535] "" Vector__XXX
 SG_ APS_sw052_a07sensorBlinded m52 : 16|1@1+ (1,0) [0|1] "" Vector__XXX
 SG_ APS_sw052_sensorDirty m52 : 17|1@1+ (1,0) [0|1] "" Vector__XXX
 SG_ APS_sw052_HWFail m52 : 18|1@1+ (1,0) [0|1] "" Vector__XXX
 SG_ APS_sw052_overTemperature m52 : 19|1@1+ (1,0) [0|1] "" Vector__XXX
 SG_ APS_sw052_underTemperature m52 : 20|1@1+ (1,0) [0|1] "" Vector__XXX
 SG_ APS_sw052_chirpError m52 : 21|1@1+ (1,0) [0|1] "" Vector__XXX
 SG_ APS_sw052_rspError m52 : 22|1@1+ (1,0) [0|1] "" Vector__XXX
 SG_ APS_sw052_sensorBlocked m52 : 23|1@1+ (1,0) [0|1] "" Vector__XXX
 SG_ APS_sw053_a10canBusOff m53 : 16|1@1+ (1,0) [0|1] "" Vector__XXX
 SG_ APS_sw053_a11bdyMIA m53 : 17|1@1+ (1,0) [0|1] "" Vector__XXX
 SG_ APS_sw053_a12espMIA m53 : 18|1@1+ (1,0) [0|1] "" Vector__XXX
 SG_ APS_sw053_a13gtwMIA m53 : 19|1@1+ (1,0) [0|1] "" Vector__XXX
 SG_ APS_sw053_a14sccmMIA m53 : 20|1@1+ (1,0) [0|1] "" Vector__XXX
 SG_ APS_sw053_a15adasMIA m53 : 21|1@1+ (1,0) [0|1] "" Vector__XXX
 SG_ APS_sw053_a16bdyInvalidCount m53 : 22|1@1+ (1,0) [0|1] "" Vector__XXX
 SG_ APS_sw053_a17adasInvalidCount m53 : 23|1@1+ (1,0) [0|1] "" Vector__XXX
 SG_ APS_sw053_a18espInvalidCount m53 : 24|1@1+ (1,0) [0|1] "" Vector__XXX
 SG_ APS_sw053_a19sccmInvalidCount m53 : 25|1@1+ (1,0) [0|1] "" Vector__XXX
 SG_ APS_sw053_a20bdyInvalidChkSm m53 : 26|1@1+ (1,0) [0|1] "" Vector__XXX
 SG_ APS_sw053_a21espInvalidChkSm m53 : 27|1@1+ (1,0) [0|1] "" Vector__XXX
 SG_ APS_sw053_a22sccmInvalidChkSm m53 : 28|1@1+ (1,0) [0|1] "" Vector__XXX
 SG_ APS_sw053_a23sccmInvalidChkSm m53 : 29|1@1+ (1,0) [0|1] "" Vector__XXX
 SG_ APS_sw053_a24absValidity m53 : 30|1@1+ (1,0) [0|1] "" Vector__XXX
 SG_ APS_sw053_a25ambTValidity m53 : 31|1@1+ (1,0) [0|1] "" Vector__XXX
 SG_ APS_sw053_a26brakeValidity m53 : 32|1@1+ (1,0) [0|1] "" Vector__XXX
 SG_ APS_sw053_a27CntryCdValidity m53 : 33|1@1+ (1,0) [0|1] "" Vector__XXX
 SG_ APS_sw053_a28espValidity m53 : 34|1@1+ (1,0) [0|1] "" Vector__XXX
 SG_ APS_sw053_a29longAccOffValidity m53 : 35|1@1+ (1,0) [0|1] "" Vector__XXX
 SG_ APS_sw053_a30longAccValidity m53 : 36|1@1+ (1,0) [0|1] "" Vector__XXX
 SG_ APS_sw053_a31odoValidity m53 : 37|1@1+ (1,0) [0|1] "" Vector__XXX
 SG_ APS_sw053_a32gearValidity m53 : 38|1@1+ (1,0) [0|1] "" Vector__XXX
 SG_ APS_sw053_a33steerAngValidity m53 : 39|1@1+ (1,0) [0|1] "" Vector__XXX
 SG_ APS_sw053_a34steerAngSpdValidity m53 : 40|1@1+ (1,0) [0|1] "" Vector__XXX
 SG_ APS_sw053_a35indctrValidity m53 : 41|1@1+ (1,0) [0|1] "" Vector__XXX
 SG_ APS_sw053_a36vehStndStllValidty m53 : 42|1@1+ (1,0) [0|1] "" Vector__XXX
 SG_ APS_sw053_a37vinValidity m53 : 43|1@1+ (1,0) [0|1] "" Vector__XXX
 SG_ APS_sw053_a38whlRotValidity m53 : 44|1@1+ (1,0) [0|1] "" Vector__XXX
 SG_ APS_sw053_a39whlSpdValidity m53 : 45|1@1+ (1,0) [0|1] "" Vector__XXX
 SG_ APS_sw053_a40whlStndStllValidty m53 : 46|1@1+ (1,0) [0|1] "" Vector__XXX
 SG_ APS_sw053_a41wiperValidity m53 : 47|1@1+ (1,0) [0|1] "" Vector__XXX
 SG_ APS_sw053_a42xwdValidity m53 : 48|1@1+ (1,0) [0|1] "" Vector__XXX
 SG_ APS_sw053_a43yawOffValidity m53 : 49|1@1+ (1,0) [0|1] "" Vector__XXX
 SG_ APS_sw053_a44yawValidity m53 : 50|1@1+ (1,0) [0|1] "" Vector__XXX
 SG_ APS_sw053_a48steerAngOffSanity m53 : 51|1@1+ (1,0) [0|1] "" Vector__XXX
 SG_ APS_sw053_a49tireSizeSanity m53 : 52|1@1+ (1,0) [0|1] "" Vector__XXX
 SG_ APS_sw053_a50velocitySanity m53 : 53|1@1+ (1,0) [0|1] "" Vector__XXX
 SG_ APS_sw053_a51yawSanity m53 : 54|1@1+ (1,0) [0|1] "" Vector__XXX
 SG_ APS_sw053_a53espmodValidity m53 : 55|1@1+ (1,0) [0|1] "" Vector__XXX
 SG_ APS_sw053_a54gtwmodValidity m53 : 56|1@1+ (1,0) [0|1] "" Vector__XXX
 SG_ APS_sw053_a55stwmodValidity m53 : 57|1@1+ (1,0) [0|1] "" Vector__XXX
 SG_ APS_sw053_a56bcmodValidity m53 : 58|1@1+ (1,0) [0|1] "" Vector__XXX
 SG_ APS_sw053_a57dimodValidity m53 : 59|1@1+ (1,0) [0|1] "" Vector__XXX
 SG_ APS_sw053_a59drmiInvalidChkSm m53 : 60|1@1+ (1,0) [0|1] "" Vector__XXX
 SG_ APS_sw053_a60drmiInvalidCount m53 : 61|1@1+ (1,0) [0|1] "" Vector__XXX
 SG_ APS_sw053_a61radPositionMismatch m53 : 62|1@1+ (1,0) [0|1] "" Vector__XXX
 SG_ APS_sw053_a62strRackMismatch m53 : 63|1@1+ (1,0) [0|1] "" Vector__XXX
 SG_ APS_sw055_detectedRadcVersion m55 : 16|32@1+ (1,0) [0|4294967295] "" Vector__XXX
 SG_ APS_sw055_expectedCrcLsw m55 : 48|16@1+ (1,0) [0|65535] "" Vector__XXX
 SG_ APS_sw056_diMia m56 : 16|8@1+ (1,0) [0|255] "" Vector__XXX
 SG_ APS_sw056_unusedByte m56 : 24|8@1+ (1,0) [0|255] "" Vector__XXX
 SG_ APS_sw056_unusedW0 m56 : 32|16@1+ (1,0) [0|65535] "" Vector__XXX
 SG_ APS_sw056_unusedW1 m56 : 48|16@1+ (1,0) [0|65535] "" Vector__XXX
 SG_ APS_sw058_epbMia m58 : 16|8@1+ (1,0) [0|255] "" Vector__XXX
 SG_ APS_sw058_unusedByte m58 : 24|8@1+ (1,0) [0|255] "" Vector__XXX
 SG_ APS_sw058_unusedW0 m58 : 32|16@1+ (1,0) [0|65535] "" Vector__XXX
 SG_ APS_sw058_unusedW1 m58 : 48|16@1+ (1,0) [0|65535] "" Vector__XXX
 SG_ APS_sw059_sdiFront m59 : 16|1@1+ (1,0) [0|1] "" Vector__XXX
 SG_ APS_sw059_sdiRear m59 : 17|1@1+ (1,0) [0|1] "" Vector__XXX
 SG_ APS_sw059_status m59 : 18|1@1+ (1,0) [0|1] "" Vector__XXX
 SG_ APS_sw059_sensorStatusFront m59 : 19|1@1+ (1,0) [0|1] "" Vector__XXX
 SG_ APS_sw059_pasFrontMiddle m59 : 20|1@1+ (1,0) [0|1] "" Vector__XXX
 SG_ APS_sw059_sensorStatusRear m59 : 21|1@1+ (1,0) [0|1] "" Vector__XXX
 SG_ APS_sw059_pasRearMiddle m59 : 22|1@1+ (1,0) [0|1] "" Vector__XXX
 SG_ APS_sw059_pscStatus m59 : 23|1@1+ (1,0) [0|1] "" Vector__XXX
 SG_ APS_sw059_pscVehSlot m59 : 24|1@1+ (1,0) [0|1] "" Vector__XXX
 SG_ APS_sw059_status2 m59 : 25|1@1+ (1,0) [0|1] "" Vector__XXX
 SG_ APS_sw059_oloDict m59 : 26|1@1+ (1,0) [0|1] "" Vector__XXX
 SG_ APS_sw059_oocStatus m59 : 27|1@1+ (1,0) [0|1] "" Vector__XXX
 SG_ APS_sw061_states m61 : 16|1@1+ (1,0) [0|1] "" Vector__XXX
 SG_ APS_sw063_expectedMajorVer m63 : 16|8@1+ (1,0) [0|255] "" Vector__XXX
 SG_ APS_sw063_detectedMajorVer m63 : 24|8@1+ (1,0) [0|255] "" Vector__XXX
 SG_ APS_sw063_expectedMinorVer m63 : 32|8@1+ (1,0) [0|255] "" Vector__XXX
 SG_ APS_sw063_detectedMinorVer m63 : 40|8@1+ (1,0) [0|255] "" Vector__XXX
 SG_ APS_sw063_expectedSubMinorVer m63 : 48|8@1+ (1,0) [0|255] "" Vector__XXX
 SG_ APS_sw063_detectedSubMinorVer m63 : 56|8@1+ (1,0) [0|255] "" Vector__XXX
 SG_ APS_sw064_sysStatus m64 : 16|1@1+ (1,0) [0|1] "" Vector__XXX
 SG_ APS_sw064_status m64 : 17|1@1+ (1,0) [0|1] "" Vector__XXX
 SG_ APS_sw070_currTireFitment m70 : 16|3@1+ (1,0) [0|7] "" Vector__XXX
 SG_ APS_sw070_lastTireFitment m70 : 19|3@1+ (1,0) [0|7] "" Vector__XXX
 SG_ APS_sw070_diGear m70 : 24|3@1+ (1,0) [0|7] "" Vector__XXX
 SG_ APS_sw070_driveRail m70 : 27|1@1+ (1,0) [0|1] "" Vector__XXX
 SG_ APS_sw070_accRail m70 : 28|1@1+ (1,0) [0|1] "" Vector__XXX
 SG_ APS_sw070_temperature m70 : 32|8@1+ (0.5,-40) [-40|87.5] "" Vector__XXX
 SG_ APS_sw070_currentSpeed m70 : 40|12@1+ (0.1,-204.7) [-204.7|204.8] "" Vector__XXX
 SG_ APS_sw071_selfParkType m71 : 16|4@1+ (1,0) [0|15] "" Vector__XXX
 SG_ APS_sw071_endPosX m71 : 20|10@1+ (0.05,-25.6) [-25.6|25.55] "" Vector__XXX
 SG_ APS_sw071_endPosY m71 : 30|10@1+ (0.05,-25.6) [-25.6|25.55] "" Vector__XXX
 SG_ APS_sw071_roadClass m71 : 40|3@1+ (1,0) [0|7] "" Vector__XXX
 SG_ APS_sw071_driverPresent m71 : 43|1@1+ (1,0) [0|1] "" Vector__XXX
 SG_ APS_sw071_airSuspension m71 : 44|3@1+ (1,0) [0|7] "" Vector__XXX
 SG_ APS_sw071_temperature m71 : 48|8@1+ (0.5,-40) [-40|87.5] "" Vector__XXX
 SG_ APS_sw071_activationType m71 : 56|2@1+ (1,0) [0|3] "" Vector__XXX
 SG_ APS_sw072_vehicleX m72 : 16|10@1+ (0.05,-25.6) [-25.6|25.55] "" Vector__XXX
 SG_ APS_sw072_vehicleY m72 : 26|10@1+ (0.05,-25.6) [-25.6|25.55] "" Vector__XXX
 SG_ APS_sw072_vehicleHeading m72 : 36|10@1+ (0.005,-2.56) [-2.56|2.555] "" Vector__XXX
 SG_ APS_sw072_endDistance m72 : 48|8@1+ (1,0) [0|255] "" Vector__XXX
 SG_ APS_sw072_guidanceComplete m72 : 56|1@1+ (1,0) [0|1] "" Vector__XXX
 SG_ APS_sw072_guidanceRunaway m72 : 57|1@1+ (1,0) [0|1] "" Vector__XXX
 SG_ APS_sw072_guidanceTimer m72 : 58|1@1+ (1,0) [0|1] "" Vector__XXX
 SG_ APS_sw072_handlePress m72 : 59|1@1+ (1,0) [0|1] "" Vector__XXX
 SG_ APS_sw072_keyfobPress m72 : 60|1@1+ (1,0) [0|1] "" Vector__XXX
 SG_ APS_sw072_garageOpened m72 : 61|1@1+ (1,0) [0|1] "" Vector__XXX
 SG_ APS_sw072_userTimeout m72 : 62|1@1+ (1,0) [0|1] "" Vector__XXX
 SG_ APS_sw075_scMia m75 : 16|8@1+ (1,0) [0|255] "" Vector__XXX
 SG_ APS_sw075_unusedByte m75 : 24|8@1+ (1,0) [0|255] "" Vector__XXX
 SG_ APS_sw075_unusedW0 m75 : 32|16@1+ (1,0) [0|65535] "" Vector__XXX
 SG_ APS_sw075_unusedW1 m75 : 48|16@1+ (1,0) [0|65535] "" Vector__XXX
 SG_ APS_sw077_oocDistance m77 : 16|9@1+ (1,0) [0|511] "" Vector__XXX
 SG_ APS_sw077_oocConfidence m77 : 25|7@1+ (1,0) [0|127] "" Vector__XXX
 SG_ APS_sw077_oocCollisionSide m77 : 32|3@1+ (1,0) [0|7] "" Vector__XXX
 SG_ APS_sw077_oocHeight m77 : 35|2@1+ (1,0) [0|3] "" Vector__XXX
 SG_ APS_sw077_vehicleSpeed m77 : 37|10@1+ (0.05,-25) [-25|26.15] "" Vector__XXX
 SG_ APS_sw077_oocUntrackedTime m77 : 48|6@1+ (0.1,0) [0|6.3] "" Vector__XXX
 SG_ APS_sw077_oocOffCourseDist_cm m77 : 54|10@1- (1,0) [-512|511] "" Vector__XXX
 SG_ APS_sw081_radarDistance m81 : 16|8@1+ (0.0625,0) [0|15.9375] "" Vector__XXX
 SG_ APS_sw081_radarTTC m81 : 24|8@1+ (0.02,0) [0|5.1] "" Vector__XXX
 SG_ APS_sw081_cameraDistance m81 : 32|8@1+ (0.0625,0) [0|15.9375] "" Vector__XXX
 SG_ APS_sw081_cameraTTC m81 : 40|8@1+ (0.02,0) [0|5.1] "" Vector__XXX
 SG_ APS_sw081_pedalPosition m81 : 48|7@1+ (1,0) [0|127] "" Vector__XXX
 SG_ APS_sw129_currentVoltage m129 : 16|14@1+ (1,0) [0|16383] "" Vector__XXX
 SG_ APS_sw129_maxThreshold m129 : 30|13@1+ (1,50) [50|8241] "" Vector__XXX
 SG_ APS_sw129_minThreshold m129 : 43|13@1+ (1,0) [0|8191] "" Vector__XXX
 SG_ APS_sw129_powerSequnceError m129 : 56|1@1+ (1,0) [0|1] "" Vector__XXX
 SG_ APS_sw129_railControl m129 : 57|1@1+ (1,0) [0|1] "" Vector__XXX
 SG_ APS_sw129_railID m129 : 58|6@1+ (1,0) [0|63] "" Vector__XXX
 SG_ APS_sw130_currentTemperature m130 : 16|8@1- (1,0) [-128|127] "" Vector__XXX
 SG_ APS_sw130_maxThreshold m130 : 24|8@1- (1,0) [-128|127] "" Vector__XXX
 SG_ APS_sw130_minThreshold m130 : 32|8@1- (1,0) [-128|127] "" Vector__XXX
 SG_ APS_sw130_tempSensorId m130 : 40|6@1+ (1,0) [0|63] "" Vector__XXX
 SG_ APS_sw130_shouldForceApPowerOn m130 : 46|1@1+ (1,0) [0|1] "" Vector__XXX
 SG_ APS_sw130_shouldBlockOkToPowerAp m130 : 47|1@1+ (1,0) [0|1] "" Vector__XXX
 SG_ APS_sw132_mismatchType m132 : 16|1@1+ (1,0) [0|1] "" Vector__XXX
 SG_ APS_sw132_actualHash m132 : 24|24@1+ (1,0) [0|16777215] "" Vector__XXX
 SG_ APS_sw132_expectedHash m132 : 48|16@1+ (1,0) [0|65535] "" Vector__XXX
 SG_ APS_sw133_failedInitStep m133 : 16|8@1+ (1,0) [0|255] "" Vector__XXX
 SG_ APS_sw133_switchInReset m133 : 24|1@1+ (1,0) [0|1] "" Vector__XXX
 SG_ APS_sw133_phyIsNotRMIIMode m133 : 25|1@1+ (1,0) [0|1] "" Vector__XXX
 SG_ APS_sw133_phyInterruptStorm m133 : 26|1@1+ (1,0) [0|1] "" Vector__XXX
 SG_ APS_sw133_switchEthernetInterLin m133 : 27|1@1+ (1,0) [0|1] "" Vector__XXX
 SG_ APS_sw133_ethSwitchReadFwVerFail m133 : 28|1@1+ (1,0) [0|1] "" Vector__XXX
 SG_ APS_sw133_ethSwitchFailedToBoot m133 : 29|1@1+ (1,0) [0|1] "" Vector__XXX
 SG_ APS_sw133_ethSwitchTimedoutUpdat m133 : 30|1@1+ (1,0) [0|1] "" Vector__XXX
 SG_ APS_sw133_ethSwitchMcuLinkFailov m133 : 31|1@1+ (1,0) [0|1] "" Vector__XXX
 SG_ APS_sw133_ethSwitchMcuLinkDuplic m133 : 32|1@1+ (1,0) [0|1] "" Vector__XXX
 SG_ APS_sw133_ethSwitchMcuLinkDiscon m133 : 33|1@1+ (1,0) [0|1] "" Vector__XXX
 SG_ APS_sw133_unused m133 : 34|30@1+ (1,0) [0|1073741823] "" Vector__XXX
 SG_ APS_sw134_appCamCalibStatus m134 : 16|1@1+ (1,0) [0|1] "" Vector__XXX
 SG_ APS_sw134_appCameraLux m134 : 17|1@1+ (1,0) [0|1] "" Vector__XXX
 SG_ APS_sw134_appInfo m134 : 18|1@1+ (1,0) [0|1] "" Vector__XXX
 SG_ APS_sw134_appStatus m134 : 19|1@1+ (1,0) [0|1] "" Vector__XXX
 SG_ APS_sw134_dasAutonomyControlPart m134 : 20|1@1+ (1,0) [0|1] "" Vector__XXX
 SG_ APS_sw134_dasAutonomyControlVeh m134 : 21|1@1+ (1,0) [0|1] "" Vector__XXX
 SG_ APS_sw134_dasBodyControlsVEH m134 : 22|1@1+ (1,0) [0|1] "" Vector__XXX
 SG_ APS_sw134_dasControl m134 : 23|1@1+ (1,0) [0|1] "" Vector__XXX
 SG_ APS_sw134_dasControlPty m134 : 24|1@1+ (1,0) [0|1] "" Vector__XXX
 SG_ APS_sw134_dasIntSafetyFrontPty m134 : 25|1@1+ (1,0) [0|1] "" Vector__XXX
 SG_ APS_sw134_dasLanes m134 : 26|1@1+ (1,0) [0|1] "" Vector__XXX
 SG_ APS_sw134_dasObject m134 : 27|1@1+ (1,0) [0|1] "" Vector__XXX
 SG_ APS_sw134_dasPscControl m134 : 28|1@1+ (1,0) [0|1] "" Vector__XXX
 SG_ APS_sw134_dasStatus m134 : 29|1@1+ (1,0) [0|1] "" Vector__XXX
 SG_ APS_sw134_dasStatus2 m134 : 30|1@1+ (1,0) [0|1] "" Vector__XXX
 SG_ APS_sw134_dasSteeringControl m134 : 31|1@1+ (1,0) [0|1] "" Vector__XXX
 SG_ APS_sw134_dasVisualDebug m134 : 32|1@1+ (1,0) [0|1] "" Vector__XXX
 SG_ APS_sw134_dasSteeringControlPty m134 : 33|1@1+ (1,0) [0|1] "" Vector__XXX
 SG_ APS_sw134_dasChNm m134 : 34|1@1+ (1,0) [0|1] "" Vector__XXX
 SG_ APS_sw134_appSummon m134 : 35|1@1+ (1,0) [0|1] "" Vector__XXX
 SG_ APS_sw134_appEnvironment m134 : 36|1@1+ (1,0) [0|1] "" Vector__XXX
 SG_ APS_sw134_dasStatusPty m134 : 37|1@1+ (1,0) [0|1] "" Vector__XXX
 SG_ APS_sw134_dasStatus2Pty m134 : 38|1@1+ (1,0) [0|1] "" Vector__XXX
 SG_ APS_sw134_dasMatrixHighBeamRqVEH m134 : 39|1@1+ (1,0) [0|1] "" Vector__XXX
 SG_ APS_sw134_dasMatrixBendAngleRqPt m134 : 40|1@1+ (1,0) [0|1] "" Vector__XXX
 SG_ APS_sw134_dasBodyControls2VEH m134 : 41|1@1+ (1,0) [0|1] "" Vector__XXX
 SG_ APS_sw134_dasRedundantBrakingCon m134 : 42|1@1+ (1,0) [0|1] "" Vector__XXX
 SG_ APS_sw134_dasRedundantBraki_0001 m134 : 43|1@1+ (1,0) [0|1] "" Vector__XXX
 SG_ APS_sw134_timeSinceLastMsg m134 : 48|16@1+ (1,0) [0|65535] "" Vector__XXX
 SG_ APS_sw135_appCriticalReason m135 : 16|4@1+ (1,0) [0|15] "" Vector__XXX
 SG_ APS_sw135_appTimesyncStatus m135 : 24|32@1+ (1,0) [0|4294967295] "" Vector__XXX
 SG_ APS_sw136_gpsCommIrrecoverable m136 : 16|1@1+ (1,0) [0|1] "" Vector__XXX
 SG_ APS_sw136_fusionIrrecoverable m136 : 17|1@1+ (1,0) [0|1] "" Vector__XXX
 SG_ APS_sw136_antennaUnplugged m136 : 18|1@1+ (1,0) [0|1] "" Vector__XXX
 SG_ APS_sw136_badgpsfix m136 : 19|1@1+ (1,0) [0|1] "" Vector__XXX
 SG_ APS_sw137_gpsCommMissing m137 : 16|1@1+ (1,0) [0|1] "" Vector__XXX
 SG_ APS_sw137_gpsJunkData m137 : 17|1@1+ (1,0) [0|1] "" Vector__XXX
 SG_ APS_sw137_gpsNMEAmissing m137 : 18|1@1+ (1,0) [0|1] "" Vector__XXX
 SG_ APS_sw137_gpsUBXmissing m137 : 19|1@1+ (1,0) [0|1] "" Vector__XXX
 SG_ APS_sw137_fusionModeDisabled m137 : 20|1@1+ (1,0) [0|1] "" Vector__XXX
 SG_ APS_sw137_gpsCfgFail m137 : 21|1@1+ (1,0) [0|1] "" Vector__XXX
 SG_ APS_sw137_esfStatusMsgMIA m137 : 22|1@1+ (1,0) [0|1] "" Vector__XXX
 SG_ APS_sw137_wheelTickCfgMissmatch m137 : 23|1@1+ (1,0) [0|1] "" Vector__XXX
 SG_ APS_sw137_exitTransportMode m137 : 24|1@1+ (1,0) [0|1] "" Vector__XXX
 SG_ APS_sw137_satRejectionTimeout m137 : 25|1@1+ (1,0) [0|1] "" Vector__XXX
 SG_ APS_sw137_gpsPPSMissing m137 : 26|1@1+ (1,0) [0|1] "" Vector__XXX
 SG_ APS_sw138_cfgBufNull m138 : 16|1@1+ (1,0) [0|1] "" Vector__XXX
 SG_ APS_sw138_invalidID m138 : 17|1@1+ (1,0) [0|1] "" Vector__XXX
 SG_ APS_sw138_gpsBufferOverflow m138 : 18|1@1+ (1,0) [0|1] "" Vector__XXX
 SG_ APS_sw138_navx5CfgFailed m138 : 19|1@1+ (1,0) [0|1] "" Vector__XXX
 SG_ APS_sw138_mcuNMEAmsgUDPinvalid m138 : 20|1@1+ (1,0) [0|1] "" Vector__XXX
 SG_ APS_sw138_mcuDbgMsgInvalid m138 : 21|1@1+ (1,0) [0|1] "" Vector__XXX
 SG_ APS_sw138_mcuDbgMsgTooBig m138 : 22|1@1+ (1,0) [0|1] "" Vector__XXX
 SG_ APS_sw138_mcuFwdNMEAfail m138 : 23|1@1+ (1,0) [0|1] "" Vector__XXX
 SG_ APS_sw138_NMEAinvalidChecksum m138 : 24|1@1+ (1,0) [0|1] "" Vector__XXX
 SG_ APS_sw138_unexpectedNMEAmsg m138 : 25|1@1+ (1,0) [0|1] "" Vector__XXX
 SG_ APS_sw138_UARTbusFull m138 : 26|1@1+ (1,0) [0|1] "" Vector__XXX
 SG_ APS_sw138_UARTframeError m138 : 27|1@1+ (1,0) [0|1] "" Vector__XXX
 SG_ APS_sw138_UBXrxFrameTooBig m138 : 28|1@1+ (1,0) [0|1] "" Vector__XXX
 SG_ APS_sw138_emptyValidNMEA m138 : 29|1@1+ (1,0) [0|1] "" Vector__XXX
 SG_ APS_sw138_invalidAsciiNMEA m138 : 30|1@1+ (1,0) [0|1] "" Vector__XXX
 SG_ APS_sw138_wheeltickUARTfault m138 : 31|1@1+ (1,0) [0|1] "" Vector__XXX
 SG_ APS_sw138_baudrateMismatch m138 : 32|1@1+ (1,0) [0|1] "" Vector__XXX
 SG_ APS_sw138_wheelTickInvalidSrc m138 : 33|1@1+ (1,0) [0|1] "" Vector__XXX
 SG_ APS_sw138_UARTparityError m138 : 34|1@1+ (1,0) [0|1] "" Vector__XXX
 SG_ APS_sw138_UARTrxFifoOverflow m138 : 35|1@1+ (1,0) [0|1] "" Vector__XXX
 SG_ APS_sw138_UARTrxFifoUnderflow m138 : 36|1@1+ (1,0) [0|1] "" Vector__XXX
 SG_ APS_sw138_UARTtxFifoOverflow m138 : 37|1@1+ (1,0) [0|1] "" Vector__XXX
 SG_ APS_sw138_esfWtMsgTimeout m138 : 38|1@1+ (1,0) [0|1] "" Vector__XXX
 SG_ APS_sw138_PFLASHReadError m138 : 39|1@1+ (1,0) [0|1] "" Vector__XXX
 SG_ APS_sw138_PFLASHWriteError m138 : 40|1@1+ (1,0) [0|1] "" Vector__XXX
 SG_ APS_sw138_gpsCfgNack m138 : 41|1@1+ (1,0) [0|1] "" Vector__XXX
 SG_ APS_sw138_gpsCfgIdFail m138 : 42|6@1+ (1,0) [0|63] "" Vector__XXX
 SG_ APS_sw138_gpsSetCfgNoAck m138 : 48|1@1+ (1,0) [0|1] "" Vector__XXX
 SG_ APS_sw138_gpsReadCfgNoResponse m138 : 49|1@1+ (1,0) [0|1] "" Vector__XXX
 SG_ APS_sw138_ubxErrorReported m138 : 50|1@1+ (1,0) [0|1] "" Vector__XXX
 SG_ APS_sw140_lvPowerState m140 : 16|1@1+ (1,0) [0|1] "" Vector__XXX
 SG_ APS_sw140_vehicleStatus m140 : 17|1@1+ (1,0) [0|1] "" Vector__XXX
 SG_ APS_sw140_status m140 : 18|1@1+ (1,0) [0|1] "" Vector__XXX
 SG_ APS_sw140_lighting m140 : 19|1@1+ (1,0) [0|1] "" Vector__XXX
 SG_ APS_sw140_sensors m140 : 20|1@1+ (1,0) [0|1] "" Vector__XXX
 SG_ APS_sw140_coolant m140 : 21|1@1+ (1,0) [0|1] "" Vector__XXX
 SG_ APS_sw140_okToUseHighPower m140 : 22|1@1+ (1,0) [0|1] "" Vector__XXX
 SG_ APS_sw141_inertial1 m141 : 16|1@1+ (1,0) [0|1] "" Vector__XXX
 SG_ APS_sw141_inertial2 m141 : 17|1@1+ (1,0) [0|1] "" Vector__XXX
 SG_ APS_sw142_speed m142 : 16|1@1+ (1,0) [0|1] "" Vector__XXX
 SG_ APS_sw142_locStatus m142 : 17|1@1+ (1,0) [0|1] "" Vector__XXX
 SG_ APS_sw142_locStatus2 m142 : 18|1@1+ (1,0) [0|1] "" Vector__XXX
 SG_ APS_sw142_systemStatus m142 : 19|1@1+ (1,0) [0|1] "" Vector__XXX
 SG_ APS_sw142_chassisControl m142 : 20|1@1+ (1,0) [0|1] "" Vector__XXX
 SG_ APS_sw142_epbStatus m142 : 21|1@1+ (1,0) [0|1] "" Vector__XXX
 SG_ APS_sw142_brakeSystem m142 : 22|1@1+ (1,0) [0|1] "" Vector__XXX
 SG_ APS_sw143_status m143 : 16|1@1+ (1,0) [0|1] "" Vector__XXX
 SG_ APS_sw143_wheelRotation m143 : 17|1@1+ (1,0) [0|1] "" Vector__XXX
 SG_ APS_sw143_wheelSpeeds m143 : 18|1@1+ (1,0) [0|1] "" Vector__XXX
 SG_ APS_sw143_redundantBrakingStatus m143 : 19|1@1+ (1,0) [0|1] "" Vector__XXX
 SG_ APS_sw144_restraintStatus m144 : 16|1@1+ (1,0) [0|1] "" Vector__XXX
 SG_ APS_sw145_restraintStatus m145 : 16|1@1+ (1,0) [0|1] "" Vector__XXX
 SG_ APS_sw146_sysStatus m146 : 16|1@1+ (1,0) [0|1] "" Vector__XXX
 SG_ APS_sw146_status m146 : 17|1@1+ (1,0) [0|1] "" Vector__XXX
 SG_ APS_sw147_doorStatus m147 : 16|1@1+ (1,0) [0|1] "" Vector__XXX
 SG_ APS_sw147_switchStatus m147 : 17|1@1+ (1,0) [0|1] "" Vector__XXX
 SG_ APS_sw148_doorStatus m148 : 16|1@1+ (1,0) [0|1] "" Vector__XXX
 SG_ APS_sw148_hvacStatus m148 : 17|1@1+ (1,0) [0|1] "" Vector__XXX
 SG_ APS_sw149_status m149 : 16|1@1+ (1,0) [0|1] "" Vector__XXX
 SG_ APS_sw150_steeringAngleSensor m150 : 16|1@1+ (1,0) [0|1] "" Vector__XXX
 SG_ APS_sw150_rightStalk m150 : 17|1@1+ (1,0) [0|1] "" Vector__XXX
 SG_ APS_sw150_leftStalk m150 : 18|1@1+ (1,0) [0|1] "" Vector__XXX
 SG_ APS_sw153_eacInhibitReason m153 : 16|4@1+ (1,0) [0|15] "" Vector__XXX
 SG_ APS_sw153_eacInternalState m153 : 20|3@1+ (1,0) [0|7] "" Vector__XXX
 SG_ APS_sw155_InUnicastError m155 : 16|1@1+ (1,0) [0|1] "" Vector__XXX
 SG_ APS_sw155_UDPRecvError m155 : 17|1@1+ (1,0) [0|1] "" Vector__XXX
 SG_ APS_sw155_UDPMiscError m155 : 18|1@1+ (1,0) [0|1] "" Vector__XXX
 SG_ APS_sw155_UDPRTEError m155 : 19|1@1+ (1,0) [0|1] "" Vector__XXX
 SG_ APS_sw155_UDPCheckError m155 : 20|1@1+ (1,0) [0|1] "" Vector__XXX
 SG_ APS_sw155_UDPDropError m155 : 21|1@1+ (1,0) [0|1] "" Vector__XXX
 SG_ APS_sw155_UDPMemError m155 : 22|1@1+ (1,0) [0|1] "" Vector__XXX
 SG_ APS_sw155_UDPProtoError m155 : 23|1@1+ (1,0) [0|1] "" Vector__XXX
 SG_ APS_sw155_IPRecvError m155 : 24|1@1+ (1,0) [0|1] "" Vector__XXX
 SG_ APS_sw155_IPMiscError m155 : 25|1@1+ (1,0) [0|1] "" Vector__XXX
 SG_ APS_sw155_IPRTEError m155 : 26|1@1+ (1,0) [0|1] "" Vector__XXX
 SG_ APS_sw155_IPCheckError m155 : 27|1@1+ (1,0) [0|1] "" Vector__XXX
 SG_ APS_sw155_IPMemError m155 : 28|1@1+ (1,0) [0|1] "" Vector__XXX
 SG_ APS_sw155_IPDropError m155 : 29|1@1+ (1,0) [0|1] "" Vector__XXX
 SG_ APS_sw155_IPProtoError m155 : 30|1@1+ (1,0) [0|1] "" Vector__XXX
 SG_ APS_sw158_apbInfo m158 : 16|1@1+ (1,0) [0|1] "" Vector__XXX
 SG_ APS_sw158_apbStatus m158 : 17|1@1+ (1,0) [0|1] "" Vector__XXX
 SG_ APS_sw158_dasAutonomyControlPart m158 : 18|1@1+ (1,0) [0|1] "" Vector__XXX
 SG_ APS_sw158_dasAutonomyControlVeh m158 : 19|1@1+ (1,0) [0|1] "" Vector__XXX
 SG_ APS_sw158_dasBodyControlsVEH m158 : 20|1@1+ (1,0) [0|1] "" Vector__XXX
 SG_ APS_sw158_dasControl m158 : 21|1@1+ (1,0) [0|1] "" Vector__XXX
 SG_ APS_sw158_dasControlPty m158 : 22|1@1+ (1,0) [0|1] "" Vector__XXX
 SG_ APS_sw158_dasIntSafetyFrontPty m158 : 23|1@1+ (1,0) [0|1] "" Vector__XXX
 SG_ APS_sw158_dasLanes m158 : 24|1@1+ (1,0) [0|1] "" Vector__XXX
 SG_ APS_sw158_dasObject m158 : 25|1@1+ (1,0) [0|1] "" Vector__XXX
 SG_ APS_sw158_dasPscControl m158 : 26|1@1+ (1,0) [0|1] "" Vector__XXX
 SG_ APS_sw158_dasStatus m158 : 27|1@1+ (1,0) [0|1] "" Vector__XXX
 SG_ APS_sw158_dasStatus2 m158 : 28|1@1+ (1,0) [0|1] "" Vector__XXX
 SG_ APS_sw158_dasSteeringControl m158 : 29|1@1+ (1,0) [0|1] "" Vector__XXX
 SG_ APS_sw158_dasVisualDebug m158 : 30|1@1+ (1,0) [0|1] "" Vector__XXX
 SG_ APS_sw158_dasSteeringControlPty m158 : 31|1@1+ (1,0) [0|1] "" Vector__XXX
 SG_ APS_sw158_dasChNm m158 : 32|1@1+ (1,0) [0|1] "" Vector__XXX
 SG_ APS_sw158_dasStatusPty m158 : 33|1@1+ (1,0) [0|1] "" Vector__XXX
 SG_ APS_sw158_dasStatus2Pty m158 : 34|1@1+ (1,0) [0|1] "" Vector__XXX
 SG_ APS_sw158_dasMatrixHighBeamRqVEH m158 : 35|1@1+ (1,0) [0|1] "" Vector__XXX
 SG_ APS_sw158_dasMatrixBendAngleRqPt m158 : 36|1@1+ (1,0) [0|1] "" Vector__XXX
 SG_ APS_sw158_dasBodyControls2VEH m158 : 37|1@1+ (1,0) [0|1] "" Vector__XXX
 SG_ APS_sw158_dasRedundantBrakingCon m158 : 38|1@1+ (1,0) [0|1] "" Vector__XXX
 SG_ APS_sw158_dasRedundantBraki_0001 m158 : 39|1@1+ (1,0) [0|1] "" Vector__XXX
 SG_ APS_sw158_timeSinceLastMsg m158 : 40|24@1+ (1,0) [0|16777215] "" Vector__XXX
 SG_ APS_sw159_apbCriticalReason m159 : 16|4@1+ (1,0) [0|15] "" Vector__XXX
 SG_ APS_sw159_apbTimesyncStatus m159 : 24|32@1+ (1,0) [0|4294967295] "" Vector__XXX
 SG_ APS_sw160_mismatchType m160 : 16|1@1+ (1,0) [0|1] "" Vector__XXX
 SG_ APS_sw160_actualHash m160 : 24|24@1+ (1,0) [0|16777215] "" Vector__XXX
 SG_ APS_sw160_expectedHash m160 : 48|16@1+ (1,0) [0|65535] "" Vector__XXX
 SG_ APS_sw161_antennaDisconnected m161 : 16|1@1+ (1,0) [0|1] "" Vector__XXX
 SG_ APS_sw172_prolongedUiMia m172 : 16|1@1+ (1,0) [0|1] "" Vector__XXX
 SG_ APS_sw172_uiMiaAtBootup m172 : 17|1@1+ (1,0) [0|1] "" Vector__XXX
 SG_ APS_sw188_otherTurbo m188 : 16|2@1+ (1,0) [0|3] "" Vector__XXX
 SG_ APS_sw188_arbUartMiaState m188 : 18|1@1+ (1,0) [0|1] "" Vector__XXX
 SG_ APS_sw188_powerUartMiaState m188 : 19|1@1+ (1,0) [0|1] "" Vector__XXX
 SG_ APS_sw188_faultsUartMiaState m188 : 20|1@1+ (1,0) [0|1] "" Vector__XXX
 SG_ APS_sw188_sleepUartMiaState m188 : 21|1@1+ (1,0) [0|1] "" Vector__XXX
 SG_ APS_sw188_resetUartMiaState m188 : 22|1@1+ (1,0) [0|1] "" Vector__XXX
 SG_ APS_sw188_statMonUartMiaState m188 : 23|1@1+ (1,0) [0|1] "" Vector__XXX
 SG_ APS_sw188_wdogStateUartMiaState m188 : 24|1@1+ (1,0) [0|1] "" Vector__XXX
 SG_ APS_sw188_critReasUartMiaState m188 : 25|1@1+ (1,0) [0|1] "" Vector__XXX
 SG_ APS_sw189_AP_vehicleState10Hz m189 : 16|1@1+ (1,0) [0|1] "" Vector__XXX
 SG_ APS_sw189_AP_vehicleState1Hz m189 : 17|1@1+ (1,0) [0|1] "" Vector__XXX
 SG_ APS_sw190_IBST_status m190 : 16|1@1+ (1,0) [0|1] "" Vector__XXX
 SG_ APS_sw192_CANbus m192 : 16|3@1+ (1,0) [0|7] "" Vector__XXX
 SG_ APS_sw192_SWTxQueueFull m192 : 19|1@1+ (1,0) [0|1] "" Vector__XXX
 SG_ APS_sw192_Busoff m192 : 20|1@1+ (1,0) [0|1] "" Vector__XXX
 SG_ APS_sw192_UncorrectedBitError m192 : 21|1@1+ (1,0) [0|1] "" Vector__XXX
 SG_ APS_sw192_CorrectedBitError m192 : 22|1@1+ (1,0) [0|1] "" Vector__XXX
 SG_ APS_sw192_ErrorPassive m192 : 23|1@1+ (1,0) [0|1] "" Vector__XXX
 SG_ APS_sw192_RamAccessFailed m192 : 24|1@1+ (1,0) [0|1] "" Vector__XXX
 SG_ APS_sw192_RxMsgLost m192 : 25|1@1+ (1,0) [0|1] "" Vector__XXX
 SG_ APS_sw192_msgIo m192 : 26|2@1+ (1,0) [0|3] "" Vector__XXX
 SG_ APS_sw192_queueFailure m192 : 28|2@1+ (1,0) [0|3] "" Vector__XXX
 SG_ APS_sw192_msgId m192 : 32|11@1+ (1,0) [0|2047] "" Vector__XXX
 SG_ APS_sw199_abortCodeDas m199 : 16|6@1+ (1,0) [0|63] "" Vector__XXX
 SG_ APS_sw199_abortCodePARK m199 : 22|5@1+ (1,0) [0|31] "" Vector__XXX
 SG_ APS_sw199_currentSTW m199 : 27|14@1+ (0.1,-819.2) [-819.2|819.1] "" Vector__XXX
 SG_ APS_sw199_currentSpeed m199 : 41|8@1+ (0.1,-12.2) [-12.2|13.3] "" Vector__XXX
 SG_ APS_sw199_internalState m199 : 49|4@1+ (1,0) [0|15] "" Vector__XXX
 SG_ APS_sw199_maxSpeed m199 : 53|7@1+ (0.2,-12.2) [-12.2|13.2] "" Vector__XXX
 SG_ APS_sw199_numShifts m199 : 60|4@1+ (1,0) [0|15] "" Vector__XXX
 SG_ APS_sw203_controlType m203 : 16|4@1+ (1,0) [0|15] "" Vector__XXX
 SG_ APS_sw203_curbType m203 : 20|2@1+ (1,0) [0|3] "" Vector__XXX
 SG_ APS_sw203_roadClass m203 : 22|3@1+ (1,0) [0|7] "" Vector__XXX
 SG_ APS_sw203_slotSizeX m203 : 25|8@1+ (4,0) [0|1020] "" Vector__XXX
 SG_ APS_sw203_slotSizeY m203 : 33|8@1+ (4,0) [0|1020] "" Vector__XXX
 SG_ APS_sw203_startDistance m203 : 41|11@1+ (1,0) [0|2047] "" Vector__XXX
 SG_ APS_sw203_vehicleSkew m203 : 52|12@1+ (0.002,0) [0|8.19] "" Vector__XXX
 SG_ APS_sw204_frLeft m204 : 16|8@1+ (1,0) [0|255] "" Vector__XXX
 SG_ APS_sw204_frLeftMiddle m204 : 24|8@1+ (1,0) [0|255] "" Vector__XXX
 SG_ APS_sw204_frMiddle m204 : 32|8@1+ (1,0) [0|255] "" Vector__XXX
 SG_ APS_sw204_frRight m204 : 40|8@1+ (1,0) [0|255] "" Vector__XXX
 SG_ APS_sw204_frRightMiddle m204 : 48|8@1+ (1,0) [0|255] "" Vector__XXX
 SG_ APS_sw204_maxSpeed m204 : 56|8@1+ (0.1,-12.2) [-12.2|13.3] "" Vector__XXX
 SG_ APS_sw205_oocDistance m205 : 16|8@1+ (1,0) [0|255] "" Vector__XXX
 SG_ APS_sw205_rrLeft m205 : 24|8@1+ (1,0) [0|255] "" Vector__XXX
 SG_ APS_sw205_rrLeftMiddle m205 : 32|8@1+ (1,0) [0|255] "" Vector__XXX
 SG_ APS_sw205_rrMiddle m205 : 40|8@1+ (1,0) [0|255] "" Vector__XXX
 SG_ APS_sw205_rrRight m205 : 48|8@1+ (1,0) [0|255] "" Vector__XXX
 SG_ APS_sw205_rrRightMiddle m205 : 56|8@1+ (1,0) [0|255] "" Vector__XXX
 SG_ APS_sw235_resetOrigin m235 : 16|2@1+ (1,0) [0|3] "" Vector__XXX
 SG_ APS_sw235_generalUnrecoverable m235 : 18|1@1+ (1,0) [0|1] "" Vector__XXX
 SG_ APS_sw235_pgoodUnrecoverable m235 : 19|1@1+ (1,0) [0|1] "" Vector__XXX
 SG_ APS_sw235_faultUnrecoverable m235 : 20|1@1+ (1,0) [0|1] "" Vector__XXX
 SG_ APS_sw235_12VFuseUnrecoverable m235 : 21|1@1+ (1,0) [0|1] "" Vector__XXX
 SG_ APS_sw235_pgoodLevelUnrcvrble m235 : 22|1@1+ (1,0) [0|1] "" Vector__XXX
 SG_ APS_sw235_faultLevelUnrcvrble m235 : 23|1@1+ (1,0) [0|1] "" Vector__XXX
 SG_ APS_sw235_12VFuseLvlUnrcvrble m235 : 24|1@1+ (1,0) [0|1] "" Vector__XXX
 SG_ APS_sw235_localSoftwareFault m235 : 25|1@1+ (1,0) [0|1] "" Vector__XXX
 SG_ APS_sw235_unrecoverableFailReset m235 : 26|1@1+ (1,0) [0|1] "" Vector__XXX
 SG_ APS_sw235_generalGic m235 : 27|1@1+ (1,0) [0|1] "" Vector__XXX
 SG_ APS_sw235_a72WdtTimeout m235 : 28|1@1+ (1,0) [0|1] "" Vector__XXX
 SG_ APS_sw235_generalScs m235 : 29|1@1+ (1,0) [0|1] "" Vector__XXX
 SG_ APS_sw235_generalUnexpected m235 : 30|1@1+ (1,0) [0|1] "" Vector__XXX
 SG_ APS_sw235_canUncorrectedBitError m235 : 31|1@1+ (1,0) [0|1] "" Vector__XXX
 SG_ APS_sw235_canExitBusoffFailed m235 : 32|1@1+ (1,0) [0|1] "" Vector__XXX
 SG_ APS_sw235_txEnFdbckNotExpected m235 : 33|1@1+ (1,0) [0|1] "" Vector__XXX
 SG_ APS_sw235_nocSmsFailed m235 : 34|1@1+ (1,0) [0|1] "" Vector__XXX
 SG_ APS_sw235_nocCamFailed m235 : 35|1@1+ (1,0) [0|1] "" Vector__XXX
 SG_ APS_sw235_nocCoreFailed m235 : 36|1@1+ (1,0) [0|1] "" Vector__XXX
 SG_ APS_sw235_nocScsFailed m235 : 37|1@1+ (1,0) [0|1] "" Vector__XXX
 SG_ APS_sw235_model3UiReset m235 : 38|1@1+ (1,0) [0|1] "" Vector__XXX
 SG_ APS_sw235_modelsUiReset m235 : 39|1@1+ (1,0) [0|1] "" Vector__XXX
 SG_ APS_sw235_pmicApOnPrpUnrcvrble m235 : 40|1@1+ (1,0) [0|1] "" Vector__XXX
 SG_ APS_sw235_apOnReadyTimeout m235 : 41|1@1+ (1,0) [0|1] "" Vector__XXX
 SG_ APS_sw235_pmicApOnWaitUnrcvrble m235 : 42|1@1+ (1,0) [0|1] "" Vector__XXX
 SG_ APS_sw235_apBootingTimeout m235 : 43|1@1+ (1,0) [0|1] "" Vector__XXX
 SG_ APS_sw235_pmicApOffWaitUnrcvrble m235 : 44|1@1+ (1,0) [0|1] "" Vector__XXX
 SG_ APS_sw235_resetBeingSent m235 : 45|1@1+ (1,0) [0|1] "" Vector__XXX
 SG_ APS_sw235_udsResetBeingSent m235 : 46|1@1+ (1,0) [0|1] "" Vector__XXX
 SG_ APS_sw235_smsWdtTimeout m235 : 47|1@1+ (1,0) [0|1] "" Vector__XXX
 SG_ APS_sw235_smsCanApHealthTimeout m235 : 48|1@1+ (1,0) [0|1] "" Vector__XXX
 SG_ APS_sw235_smsTaskWdtTimeout m235 : 49|1@1+ (1,0) [0|1] "" Vector__XXX
 SG_ APS_sw237_faultSource m237 : 16|7@1+ (1,0) [0|127] "" Vector__XXX
 SG_ APS_sw237_peerSoCFaulted m237 : 23|1@1+ (1,0) [0|1] "" Vector__XXX
 SG_ APS_sw241_unknownVendorOnResume m241 : 16|1@1+ (1,0) [0|1] "" Vector__XXX
 SG_ APS_sw241_unknownVendorOnNonResu m241 : 17|1@1+ (1,0) [0|1] "" Vector__XXX
 SG_ APS_sw241_phyReinitFailedOnResum m241 : 18|1@1+ (1,0) [0|1] "" Vector__XXX
 SG_ APS_sw241_phyReinitFailedOnNonRe m241 : 19|1@1+ (1,0) [0|1] "" Vector__XXX
 SG_ APS_sw241_illTestFailed m241 : 20|1@1+ (1,0) [0|1] "" Vector__XXX
 SG_ APS_sw241_memTestFailed m241 : 21|1@1+ (1,0) [0|1] "" Vector__XXX
 SG_ APS_sw241_dfiInitCompleteTimeout m241 : 22|1@1+ (1,0) [0|1] "" Vector__XXX
 SG_ APS_sw241_phy0TimeoutWaitingForI m241 : 23|1@1+ (1,0) [0|1] "" Vector__XXX
 SG_ APS_sw241_phy0Ch0ReadGateOffsetB m241 : 24|1@1+ (1,0) [0|1] "" Vector__XXX
 SG_ APS_sw241_phy0Ch1ReadGateOffsetB m241 : 25|1@1+ (1,0) [0|1] "" Vector__XXX
 SG_ APS_sw241_phy0RdlvlReinitTrainin m241 : 26|1@1+ (1,0) [0|1] "" Vector__XXX
 SG_ APS_sw241_phy0RdlvlReinitFailed m241 : 27|1@1+ (1,0) [0|1] "" Vector__XXX
 SG_ APS_sw241_phy0WdqlvlReinitTraini m241 : 28|1@1+ (1,0) [0|1] "" Vector__XXX
 SG_ APS_sw241_phy0WdqlvlPhaseMarginO m241 : 29|1@1+ (1,0) [0|1] "" Vector__XXX
 SG_ APS_sw241_phy0WdqlvlReinitFailed m241 : 30|1@1+ (1,0) [0|1] "" Vector__XXX
 SG_ APS_sw241_phy1TimeoutWaitingForI m241 : 31|1@1+ (1,0) [0|1] "" Vector__XXX
 SG_ APS_sw241_phy1Ch0ReadGateOffsetB m241 : 32|1@1+ (1,0) [0|1] "" Vector__XXX
 SG_ APS_sw241_phy1Ch1ReadGateOffsetB m241 : 33|1@1+ (1,0) [0|1] "" Vector__XXX
 SG_ APS_sw241_phy1RdlvlReinitTrainin m241 : 34|1@1+ (1,0) [0|1] "" Vector__XXX
 SG_ APS_sw241_phy1RdlvlReinitFailed m241 : 35|1@1+ (1,0) [0|1] "" Vector__XXX
 SG_ APS_sw241_phy1WdqlvlReinitTraini m241 : 36|1@1+ (1,0) [0|1] "" Vector__XXX
 SG_ APS_sw241_phy1WdqlvlPhaseMarginO m241 : 37|1@1+ (1,0) [0|1] "" Vector__XXX
 SG_ APS_sw241_phy1WdqlvlReinitFailed m241 : 38|1@1+ (1,0) [0|1] "" Vector__XXX
 SG_ APS_sw241_phy2TimeoutWaitingForI m241 : 39|1@1+ (1,0) [0|1] "" Vector__XXX
 SG_ APS_sw241_phy2Ch0ReadGateOffsetB m241 : 40|1@1+ (1,0) [0|1] "" Vector__XXX
 SG_ APS_sw241_phy2Ch1ReadGateOffsetB m241 : 41|1@1+ (1,0) [0|1] "" Vector__XXX
 SG_ APS_sw241_phy2RdlvlReinitTrainin m241 : 42|1@1+ (1,0) [0|1] "" Vector__XXX
 SG_ APS_sw241_phy2RdlvlReinitFailed m241 : 43|1@1+ (1,0) [0|1] "" Vector__XXX
 SG_ APS_sw241_phy2WdqlvlReinitTraini m241 : 44|1@1+ (1,0) [0|1] "" Vector__XXX
 SG_ APS_sw241_phy2WdqlvlPhaseMarginO m241 : 45|1@1+ (1,0) [0|1] "" Vector__XXX
 SG_ APS_sw241_phy2WdqlvlReinitFailed m241 : 46|1@1+ (1,0) [0|1] "" Vector__XXX
 SG_ APS_sw241_phy3TimeoutWaitingForI m241 : 47|1@1+ (1,0) [0|1] "" Vector__XXX
 SG_ APS_sw241_phy3Ch0ReadGateOffsetB m241 : 48|1@1+ (1,0) [0|1] "" Vector__XXX
 SG_ APS_sw241_phy3Ch1ReadGateOffsetB m241 : 49|1@1+ (1,0) [0|1] "" Vector__XXX
 SG_ APS_sw241_phy3RdlvlReinitTrainin m241 : 50|1@1+ (1,0) [0|1] "" Vector__XXX
 SG_ APS_sw241_phy3RdlvlReinitFailed m241 : 51|1@1+ (1,0) [0|1] "" Vector__XXX
 SG_ APS_sw241_phy3WdqlvlReinitTraini m241 : 52|1@1+ (1,0) [0|1] "" Vector__XXX
 SG_ APS_sw241_phy3WdqlvlPhaseMarginO m241 : 53|1@1+ (1,0) [0|1] "" Vector__XXX
 SG_ APS_sw241_phy3WdqlvlReinitFailed m241 : 54|1@1+ (1,0) [0|1] "" Vector__XXX
 SG_ APS_sw242_instance m242 : 16|3@1+ (1,0) [0|7] "" Vector__XXX
 SG_ APS_sw242_clusterSRAMMBISTFailed m242 : 19|1@1+ (1,0) [0|1] "" Vector__XXX
 SG_ APS_sw242_SRAMBankMBISTFailed m242 : 20|1@1+ (1,0) [0|1] "" Vector__XXX
 SG_ APS_sw243_instance m243 : 16|3@1+ (1,0) [0|7] "" Vector__XXX
 SG_ APS_sw243_errorStatus m243 : 24|8@1+ (1,0) [0|255] "" Vector__XXX
 SG_ APS_sw243_extendedErrorStatus m243 : 32|24@1+ (1,0) [0|16777215] "" Vector__XXX
 SG_ APS_sw244_instance m244 : 16|3@1+ (1,0) [0|7] "" Vector__XXX
 SG_ APS_sw244_exceptionCode m244 : 24|8@1+ (1,0) [0|255] "" Vector__XXX
 SG_ APS_sw245_unknownMACAddrByte0 m245 : 16|8@1+ (1,0) [0|255] "" Vector__XXX
 SG_ APS_sw245_unknownMACAddrByte1 m245 : 24|8@1+ (1,0) [0|255] "" Vector__XXX
 SG_ APS_sw245_unknownMACAddrByte2 m245 : 32|8@1+ (1,0) [0|255] "" Vector__XXX
 SG_ APS_sw245_unknownMACAddrByte3 m245 : 40|8@1+ (1,0) [0|255] "" Vector__XXX
 SG_ APS_sw245_unknownMACAddrByte4 m245 : 48|8@1+ (1,0) [0|255] "" Vector__XXX
 SG_ APS_sw245_unknownMACAddrByte5 m245 : 56|8@1+ (1,0) [0|255] "" Vector__XXX
 SG_ APS_sw246_ethloopSwitchPort0 m246 : 16|1@1+ (1,0) [0|1] "" Vector__XXX
 SG_ APS_sw246_ethloopSwitchPort1 m246 : 17|1@1+ (1,0) [0|1] "" Vector__XXX
 SG_ APS_sw246_ethloopSwitchPort2 m246 : 18|1@1+ (1,0) [0|1] "" Vector__XXX
 SG_ APS_sw246_ethloopSwitchPort3 m246 : 19|1@1+ (1,0) [0|1] "" Vector__XXX
 SG_ APS_sw246_ethloopSwitchPort4 m246 : 20|1@1+ (1,0) [0|1] "" Vector__XXX
 SG_ APS_sw246_ethloopSwitchPort5 m246 : 21|1@1+ (1,0) [0|1] "" Vector__XXX
 SG_ APS_sw246_ethloopSwitchPort6 m246 : 22|1@1+ (1,0) [0|1] "" Vector__XXX
 SG_ APS_sw246_ethloopSwitchPort7 m246 : 23|1@1+ (1,0) [0|1] "" Vector__XXX
 SG_ APS_sw247_crcError m247 : 16|1@1+ (1,0) [0|1] "" Vector__XXX
 SG_ APS_sw247_dribbleError m247 : 17|1@1+ (1,0) [0|1] "" Vector__XXX
 SG_ APS_sw247_receiveError m247 : 18|1@1+ (1,0) [0|1] "" Vector__XXX
 SG_ APS_sw247_wdogTimeout m247 : 19|1@1+ (1,0) [0|1] "" Vector__XXX
 SG_ APS_sw247_overflowError m247 : 20|1@1+ (1,0) [0|1] "" Vector__XXX
 SG_ APS_sw247_giantPacket m247 : 21|1@1+ (1,0) [0|1] "" Vector__XXX
 SG_ APS_sw247_destAddrFilterFail m247 : 22|1@1+ (1,0) [0|1] "" Vector__XXX
 SG_ APS_sw247_saAddressFilterFail m247 : 23|1@1+ (1,0) [0|1] "" Vector__XXX
 SG_ APS_sw248_ethloopSwitchPort2Sqi m248 : 16|3@1+ (1,0) [0|7] "" Vector__XXX
 SG_ APS_sw248_ethloopSwitchPort3Sqi m248 : 19|3@1+ (1,0) [0|7] "" Vector__XXX
 SG_ APS_sw249_ufsInitFailureReason m249 : 16|3@1+ (1,0) [0|7] "" Vector__XXX
 SG_ APS_sw252_ethSwitchPort2 m252 : 16|1@1+ (1,0) [0|1] "" Vector__XXX
 SG_ APS_sw253_apWaitForShutdownTimeo m253 : 16|1@1+ (1,0) [0|1] "" Vector__XXX
 SG_ APS_sw253_apOffPrepareTimeout m253 : 17|1@1+ (1,0) [0|1] "" Vector__XXX
 SG_ APS_sw253_apSuspendedTimeout m253 : 18|1@1+ (1,0) [0|1] "" Vector__XXX
 SG_ APS_sw253_socOffReadyTimeout m253 : 19|1@1+ (1,0) [0|1] "" Vector__XXX
 SG_ APS_sw253_apInLinuxTimeout m253 : 20|1@1+ (1,0) [0|1] "" Vector__XXX
 SG_ APS_sw253_apInCorebootTimeout m253 : 21|1@1+ (1,0) [0|1] "" Vector__XXX
 SG_ APS_sw253_apBootingTimeout m253 : 22|1@1+ (1,0) [0|1] "" Vector__XXX
 SG_ APS_sw253_apOnTimeout m253 : 23|1@1+ (1,0) [0|1] "" Vector__XXX
 SG_ APS_sw254_waitForBusSilenceTimeo m254 : 16|1@1+ (1,0) [0|1] "" Vector__XXX
 SG_ APS_sw254_sleepReadyTimeout m254 : 17|1@1+ (1,0) [0|1] "" Vector__XXX
 SG_ APS_sw254_sleepingTimeout m254 : 18|1@1+ (1,0) [0|1] "" Vector__XXX
 SG_ APS_sw255_unknownBootError m255 : 16|1@1+ (1,0) [0|1] "" Vector__XXX
 SG_ APS_sw255_adcWrapperInitBootErro m255 : 17|1@1+ (1,0) [0|1] "" Vector__XXX
 SG_ APS_sw255_boardRevisionInitBootE m255 : 18|1@1+ (1,0) [0|1] "" Vector__XXX
 SG_ APS_sw255_i2cInitBootError m255 : 19|1@1+ (1,0) [0|1] "" Vector__XXX
 SG_ APS_sw255_provisionInitBootError m255 : 20|1@1+ (1,0) [0|1] "" Vector__XXX
 SG_ APS_sw255_rtcInitBootError m255 : 21|1@1+ (1,0) [0|1] "" Vector__XXX
 SG_ APS_sw255_vrmInitConfigBootError m255 : 22|1@1+ (1,0) [0|1] "" Vector__XXX
 SG_ APS_sw255_powerAonIoBootError m255 : 23|1@1+ (1,0) [0|1] "" Vector__XXX
 SG_ APS_sw255_bl1TocInitBootError m255 : 24|1@1+ (1,0) [0|1] "" Vector__XXX
 SG_ APS_sw255_tmuInitBootError m255 : 25|1@1+ (1,0) [0|1] "" Vector__XXX
 SG_ APS_sw255_udpInitBootError m255 : 26|1@1+ (1,0) [0|1] "" Vector__XXX
 SG_ APS_sw255_gpsInitBootError m255 : 27|1@1+ (1,0) [0|1] "" Vector__XXX
 SG_ APS_sw255_canInitBootError m255 : 28|1@1+ (1,0) [0|1] "" Vector__XXX
 SG_ APS_sw255_dfuCheckinSubsystemBoo m255 : 29|1@1+ (1,0) [0|1] "" Vector__XXX
 SG_ APS_sw255_sectorProtectionBootEr m255 : 30|1@1+ (1,0) [0|1] "" Vector__XXX
 SG_ APS_sw255_flashOpBootError m255 : 31|1@1+ (1,0) [0|1] "" Vector__XXX
 SG_ APS_sw255_socIdInitBootError m255 : 32|1@1+ (1,0) [0|1] "" Vector__XXX
 SG_ APS_sw260_pgoodTripSramStatus m260 : 16|8@1+ (1,0) [0|255] "" Vector__XXX
 SG_ APS_sw260_pgoodPmicFaultSd0 m260 : 24|1@1+ (1,0) [0|1] "" Vector__XXX
 SG_ APS_sw260_pgoodPmicFaultSd1 m260 : 25|1@1+ (1,0) [0|1] "" Vector__XXX
 SG_ APS_sw260_pgoodPmicFaultSd2 m260 : 26|1@1+ (1,0) [0|1] "" Vector__XXX
 SG_ APS_sw260_pgoodPmicFaultSd3 m260 : 27|1@1+ (1,0) [0|1] "" Vector__XXX
 SG_ APS_sw260_pgoodPmicFaultSd4 m260 : 28|1@1+ (1,0) [0|1] "" Vector__XXX
 SG_ APS_sw260_pgoodPmicFaultLdo0 m260 : 29|1@1+ (1,0) [0|1] "" Vector__XXX
 SG_ APS_sw260_pgoodPmicFaultLdo1 m260 : 30|1@1+ (1,0) [0|1] "" Vector__XXX
 SG_ APS_sw260_pgoodPmicFaultLdo2 m260 : 31|1@1+ (1,0) [0|1] "" Vector__XXX
 SG_ APS_sw260_pgoodPmicFaultLdo3 m260 : 32|1@1+ (1,0) [0|1] "" Vector__XXX
 SG_ APS_sw260_pgoodPmicFaultLdo4 m260 : 33|1@1+ (1,0) [0|1] "" Vector__XXX
 SG_ APS_sw260_pgoodPmicFaultLdo5 m260 : 34|1@1+ (1,0) [0|1] "" Vector__XXX
 SG_ APS_sw260_pgoodPmicFaultLdo6 m260 : 35|1@1+ (1,0) [0|1] "" Vector__XXX
 SG_ APS_sw260_pgoodPmicFaultLdo7 m260 : 36|1@1+ (1,0) [0|1] "" Vector__XXX
 SG_ APS_sw260_pgoodPmicFaultLdo8 m260 : 37|1@1+ (1,0) [0|1] "" Vector__XXX
 SG_ APS_sw260_pgoodUfs3V3Fail m260 : 38|1@1+ (1,0) [0|1] "" Vector__XXX
 SG_ APS_sw260_pgoodTripVrmRailFail m260 : 39|1@1+ (1,0) [0|1] "" Vector__XXX
 SG_ APS_sw260_pgoodIntVrmRailFail m260 : 40|1@1+ (1,0) [0|1] "" Vector__XXX
 SG_ APS_sw260_pgoodCpuVrmRailFail m260 : 41|1@1+ (1,0) [0|1] "" Vector__XXX
 SG_ APS_sw260_pgoodGpuVrmRailFail m260 : 42|1@1+ (1,0) [0|1] "" Vector__XXX
 SG_ APS_sw260_pgoodDdr0V75VrmRailFai m260 : 43|1@1+ (1,0) [0|1] "" Vector__XXX
 SG_ APS_sw260_pgoodDdr1V25VrmRailFai m260 : 44|1@1+ (1,0) [0|1] "" Vector__XXX
 SG_ APS_sw260_unknownSource m260 : 45|1@1+ (1,0) [0|1] "" Vector__XXX
 SG_ APS_sw261_vrmPublicFaultValues m261 : 16|16@1+ (1,0) [0|65535] "" Vector__XXX
 SG_ APS_sw261_vrmRail1FaultValues m261 : 32|8@1+ (1,0) [0|255] "" Vector__XXX
 SG_ APS_sw261_vrmRail2FaultValues m261 : 40|8@1+ (1,0) [0|255] "" Vector__XXX
 SG_ APS_sw261_vrmRail3FaultValues m261 : 48|8@1+ (1,0) [0|255] "" Vector__XXX
 SG_ APS_sw261_vrmType m261 : 56|3@1+ (1,0) [0|7] "" Vector__XXX
 SG_ APS_sw262_vrmPublicFaultValues m262 : 16|16@1+ (1,0) [0|65535] "" Vector__XXX
 SG_ APS_sw262_vrmRail1FaultValues m262 : 32|8@1+ (1,0) [0|255] "" Vector__XXX
 SG_ APS_sw262_vrmRail2FaultValues m262 : 40|8@1+ (1,0) [0|255] "" Vector__XXX
 SG_ APS_sw262_vrmRail3FaultValues m262 : 48|8@1+ (1,0) [0|255] "" Vector__XXX
 SG_ APS_sw262_vrmType m262 : 56|3@1+ (1,0) [0|7] "" Vector__XXX
 SG_ APS_sw263_vrmPublicFaultValues m263 : 16|16@1+ (1,0) [0|65535] "" Vector__XXX
 SG_ APS_sw263_vrmRail1FaultValues m263 : 32|8@1+ (1,0) [0|255] "" Vector__XXX
 SG_ APS_sw263_vrmRail2FaultValues m263 : 40|8@1+ (1,0) [0|255] "" Vector__XXX
 SG_ APS_sw263_vrmType m263 : 48|3@1+ (1,0) [0|7] "" Vector__XXX
 SG_ APS_sw279_corruptDirectorySource m279 : 16|3@1+ (1,0) [0|7] "" Vector__XXX
 SG_ APS_sw279_errorCode m279 : 24|8@1+ (1,0) [0|255] "" Vector__XXX
 SG_ APS_sw280_pepsStatus m280 : 16|1@1+ (1,0) [0|1] "" Vector__XXX
 SG_ APS_sw281_rearSteerStatus m281 : 16|1@1+ (1,0) [0|1] "" Vector__XXX
 SG_ APS_sw283_psfaStatus m283 : 16|1@1+ (1,0) [0|1] "" Vector__XXX
 SG_ APS_sw288_status m288 : 16|1@1+ (1,0) [0|1] "" Vector__XXX
 SG_ APS_sw289_turboTemperature m289 : 16|8@1- (1,0) [-128|127] "" Vector__XXX
 SG_ APS_sw289_turboProbe m289 : 24|6@1+ (1,0) [0|63] "" Vector__XXX
 SG_ APS_sw289_peer_turboTemperature m289 : 32|8@1- (1,0) [-128|127] "" Vector__XXX
 SG_ APS_sw289_peer_turboProbe m289 : 40|6@1+ (1,0) [0|63] "" Vector__XXX
 SG_ APS_sw315_sysStatus m315 : 16|1@1+ (1,0) [0|1] "" Vector__XXX
 SG_ APS_sw315_status m315 : 17|1@1+ (1,0) [0|1] "" Vector__XXX
 SG_ APS_sw317_motionControlCommand m317 : 16|1@1+ (1,0) [0|1] "" Vector__XXX
 SG_ APS_sw317_vehicleControl2 m317 : 17|1@1+ (1,0) [0|1] "" Vector__XXX

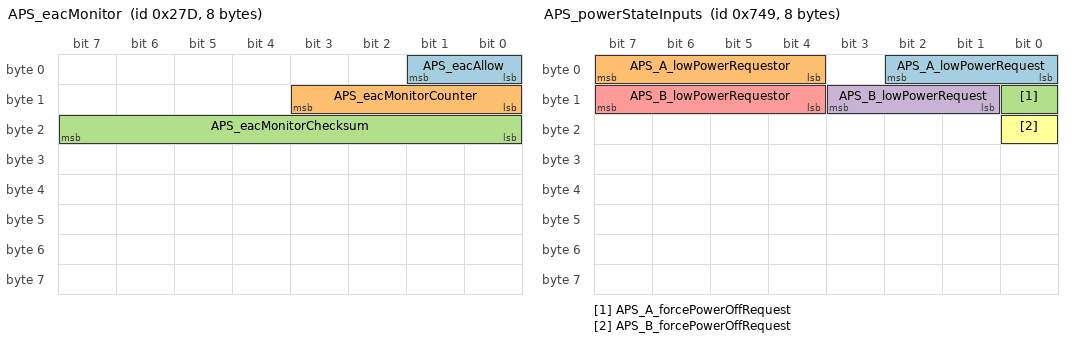
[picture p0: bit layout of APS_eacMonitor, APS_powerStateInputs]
BO_ 637 APS_eacMonitor: 8 APS
 SG_ APS_eacAllow : 0|2@1+ (1,0) [0|3] "" Vector__XXX
 SG_ APS_eacMonitorCounter : 8|4@1+ (1,0) [0|15] "" Vector__XXX
 SG_ APS_eacMonitorChecksum : 16|8@1+ (1,0) [0|255] "" Vector__XXX

BO_ 1865 APS_powerStateInputs: 8 APS
 SG_ APS_A_lowPowerRequest : 0|3@1+ (1,0) [0|7] "" Vector__XXX
 SG_ APS_A_lowPowerRequestor : 4|4@1+ (1,0) [0|15] "" Vector__XXX
 SG_ APS_A_forcePowerOffRequest : 8|1@1+ (1,0) [0|1] "" Vector__XXX
 SG_ APS_B_lowPowerRequest : 9|3@1+ (1,0) [0|7] "" Vector__XXX
 SG_ APS_B_lowPowerRequestor : 12|4@1+ (1,0) [0|15] "" Vector__XXX
 SG_ APS_B_forcePowerOffRequest : 16|1@1+ (1,0) [0|1] "" Vector__XXX

BO_ 2044 APS_state: 8 APS
 SG_ APS_primaryTurbo : 0|2@1+ (1,0) [0|3] "" Vector__XXX
 SG_ APS_A_arbState : 2|3@1+ (1,0) [0|7] "" Vector__XXX
 SG_ APS_A_powerState : 5|5@1+ (1,0) [0|31] "" Vector__XXX
 SG_ APS_A_sleepState : 10|4@1+ (1,0) [0|15] "" Vector__XXX
 SG_ APS_A_resetState : 14|3@1+ (1,0) [0|7] "" Vector__XXX
 SG_ APS_A_faultState : 17|5@1+ (1,0) [0|31] "" Vector__XXX
 SG_ APS_secondaryTurbo : 22|2@1+ (1,0) [0|3] "" Vector__XXX
 SG_ APS_B_arbState : 24|3@1+ (1,0) [0|7] "" Vector__XXX
 SG_ APS_B_powerState : 27|5@1+ (1,0) [0|31] "" Vector__XXX
 SG_ APS_B_sleepState : 32|4@1+ (1,0) [0|15] "" Vector__XXX
 SG_ APS_B_resetState : 36|3@1+ (1,0) [0|7] "" Vector__XXX
 SG_ APS_B_faultState : 39|5@1+ (1,0) [0|31] "" Vector__XXX
 SG_ APS_A_autosteerMonitorState : 44|3@1+ (1,0) [0|7] "" Vector__XXX
 SG_ APS_B_autosteerMonitorState : 47|3@1+ (1,0) [0|7] "" Vector__XXX
 SG_ APS_eplannerState : 50|3@1+ (1,0) [0|7] "" Vector__XXX
 SG_ APS_A_faultInduced : 53|1@1+ (1,0) [0|1] "" Vector__XXX
 SG_ APS_B_faultInduced : 54|1@1+ (1,0) [0|1] "" Vector__XXX
 SG_ APS_stateCounter : 55|4@1+ (1,0) [0|15] "" Vector__XXX

BO_ 970 APS_status: 8 APS
 SG_ APS_appStatusMonitorState : 0|3@1+ (1,0) [0|7] "" Vector__XXX
 SG_ APS_vehBehaviorState : 4|4@1+ (1,0) [0|15] "" Vector__XXX
 SG_ APS_canMaster : 8|2@1+ (1,0) [0|3] "" Vector__XXX
 SG_ APS_appGpioState : 10|2@1+ (1,0) [0|3] "" Vector__XXX
 SG_ APS_eacInternalState : 12|3@1+ (1,0) [0|7] "" Vector__XXX
 SG_ APS_switchState : 15|1@1+ (1,0) [0|1] "" Vector__XXX
 SG_ APS_apbStatusMonitorState : 16|3@1+ (1,0) [0|7] "" Vector__XXX
 SG_ APS_apbGpioState : 20|2@1+ (1,0) [0|3] "" Vector__XXX
 SG_ APS_statusCounter : 22|4@1+ (1,0) [0|15] "" Vector__XXX
 SG_ APS_locLimitReason : 26|3@1+ (1,0) [0|7] "" Vector__XXX
 SG_ APS_appPowerStateRequest : 29|2@1+ (1,0) [0|3] "" Vector__XXX
 SG_ APS_appPowerStateReason : 31|4@1+ (1,0) [0|15] "" Vector__XXX
 SG_ APS_apbPowerStateRequest : 35|2@1+ (1,0) [0|3] "" Vector__XXX
 SG_ APS_apbPowerStateReason : 37|4@1+ (1,0) [0|15] "" Vector__XXX
 SG_ APS_heaterStateDebug : 41|3@1+ (1,0) [0|7] "" Vector__XXX
 SG_ APS_autosummonCounter : 44|3@1+ (1,0) [0|7] "" Vector__XXX
 SG_ APS_autosummonAlert : 47|1@1+ (1,0) [0|1] "" Vector__XXX
 SG_ APS_gpsAntennaState : 48|2@1+ (1,0) [0|3] "" Vector__XXX
 SG_ APS_arbState : 50|3@1+ (1,0) [0|7] "" Vector__XXX
 SG_ APS_socPowerOperatingMode : 53|2@1+ (1,0) [0|3] "" Vector__XXX
 SG_ APS_otherArbState : 55|3@1+ (1,0) [0|7] "" Vector__XXX
 SG_ APS_appActivePlannerType : 58|3@1+ (1,0) [0|7] "" Vector__XXX
 SG_ APS_apbActivePlannerType : 61|3@1+ (1,0) [0|7] "" Vector__XXX

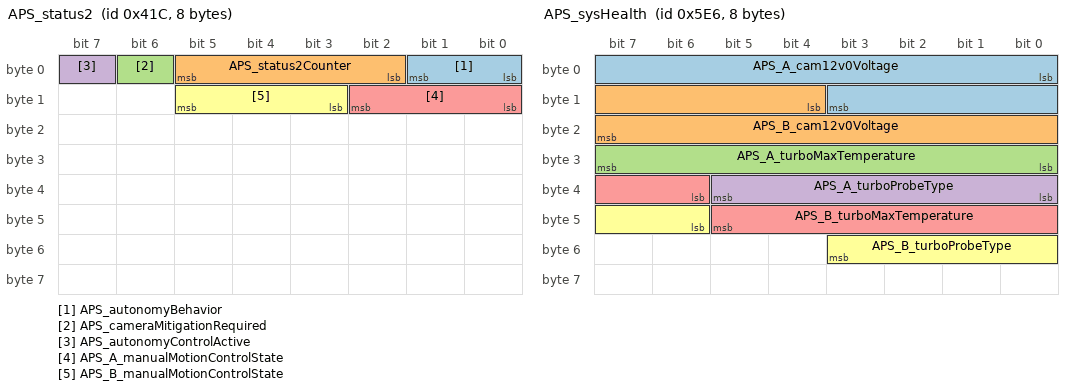
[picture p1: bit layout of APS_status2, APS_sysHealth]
BO_ 1052 APS_status2: 8 APS
 SG_ APS_autonomyBehavior : 0|2@1+ (1,0) [0|3] "" Vector__XXX
 SG_ APS_status2Counter : 2|4@1+ (1,0) [0|15] "" Vector__XXX
 SG_ APS_cameraMitigationRequired : 6|1@1+ (1,0) [0|1] "" Vector__XXX
 SG_ APS_autonomyControlActive : 7|1@1+ (1,0) [0|1] "" Vector__XXX
 SG_ APS_A_manualMotionControlState : 8|3@1+ (1,0) [0|7] "" Vector__XXX
 SG_ APS_B_manualMotionControlState : 11|3@1+ (1,0) [0|7] "" Vector__XXX

BO_ 1510 APS_sysHealth: 8 APS
 SG_ APS_A_cam12v0Voltage : 0|12@1+ (0.0048,0) [0|19.44] "V" Vector__XXX
 SG_ APS_B_cam12v0Voltage : 12|12@1+ (0.0048,0) [0|19.44] "V" Vector__XXX
 SG_ APS_A_turboMaxTemperature : 24|8@1- (1,0) [-128|127] "degC" Vector__XXX
 SG_ APS_A_turboProbeType : 32|6@1+ (1,0) [0|63] "" Vector__XXX
 SG_ APS_B_turboMaxTemperature : 38|8@1- (1,0) [-128|127] "degC" Vector__XXX
 SG_ APS_B_turboProbeType : 46|6@1+ (1,0) [0|63] "" Vector__XXX

CM_ BO_ 845 "APSB ECU message: warning matrix0";
CM_ SG_ 845 APSB_w001_DEPRECATED "APSB ECU: w001 DEPRECATED";
CM_ SG_ 845 APSB_w002_ldwDisabled "APSB ECU: w002 ldw disabled";
CM_ SG_ 845 APSB_w003_isaDisabled "APSB ECU: w003 isa disabled";
CM_ SG_ 845 APSB_w004_accDisabled "APSB ECU: w004 acc disabled";
CM_ SG_ 845 APSB_w005_fcwCancelled "APSB ECU: w005 fcw cancelled";
CM_ SG_ 845 APSB_w006_aebCancelled "APSB ECU: w006 aeb cancelled";
CM_ SG_ 845 APSB_w007_ahlbDisabled "APSB ECU: w007 ahlb disabled";
CM_ SG_ 845 APSB_w008_parkDisabled "APSB ECU: w008 park disabled";
CM_ SG_ 845 APSB_w009_aebFault "APSB ECU: w009 aeb fault";
CM_ SG_ 845 APSB_w010_radcCalibIssue "APSB ECU: w010 radc calib issue";
CM_ SG_ 845 APSB_w011_scaEvent "APSB ECU: w011 sca event";
CM_ SG_ 845 APSB_w012_Cam_BootFailure "APSB ECU: w012 cam boot failure";
CM_ SG_ 845 APSB_w013_Cam_Watchdog "APSB ECU: w013 cam watchdog";
CM_ SG_ 845 APSB_w014_swAssert "APSB ECU: w014 sw assert";
CM_ SG_ 845 APSB_w015_Camera_Failsafes "APSB ECU: w015 camera failsafes";
CM_ SG_ 845 APSB_w016_aeb_e_event "APSB ECU: w016 aeb e event";
CM_ SG_ 845 APSB_w017_Cam_Msg_MIA "APSB ECU: w017 cam msg MIA";
CM_ SG_ 845 APSB_w018_ECU_Power_Issue "APSB ECU: w018 ECU power issue";
CM_ SG_ 845 APSB_w019_ECU_Stack_Overflow "APSB ECU: w019 ECU stack overflow";
CM_ SG_ 845 APSB_w020_ECU_checkstopError "APSB ECU: w020 ECU checkstop error";
CM_ SG_ 845 APSB_w021_ECU_Temperature_Issue "APSB ECU: w021 ECU temperature issue";
CM_ SG_ 845 APSB_w022_ECU_EEPROM_Failure "APSB ECU: w022 ECU EEPROM failure";
CM_ SG_ 845 APSB_w023_ECU_Cam_Statemismatc "APSB ECU: w023 ECU cam statemismatc";
CM_ SG_ 845 APSB_w024_ECU_Watchdog_Reset "APSB ECU: w024 ECU watchdog reset";
CM_ SG_ 845 APSB_w025_LC_Steering_Override "APSB ECU: w025 LC steering override";
CM_ SG_ 845 APSB_w026_ECU_timingIssue "APSB ECU: w026 ECU timing issue";
CM_ SG_ 845 APSB_w027_ECU_Reset_Fault "APSB ECU: w027 ECU reset fault";
CM_ SG_ 845 APSB_w028_spi_rx_error "APSB ECU: w028 spi rx error";
CM_ SG_ 845 APSB_w029_spi_tx_error "APSB ECU: w029 spi tx error";
CM_ SG_ 845 APSB_w030_Heater_Issue "APSB ECU: w030 heater issue";
CM_ SG_ 845 APSB_w031_canRxError "APSB ECU: w031 can rx error";
CM_ SG_ 845 APSB_w032_canTxError "APSB ECU: w032 can tx error";
CM_ SG_ 845 APSB_w033_gtwMia "APSB ECU: w033 gtw mia";
CM_ SG_ 845 APSB_w034_sccmMia "APSB ECU: w034 sccm mia";
CM_ SG_ 845 APSB_w035_espMia "APSB ECU: w035 esp mia";
CM_ SG_ 845 APSB_w036_bdyMia "APSB ECU: w036 bdy mia";
CM_ SG_ 845 APSB_w037_camTacIssue "APSB ECU: w037 cam tac issue";
CM_ SG_ 845 APSB_w038_camFailure "APSB ECU: w038 cam failure";
CM_ SG_ 845 APSB_w039_sdm_rcm_Mia "APSB ECU: w039 sdm rcm mia";
CM_ SG_ 845 APSB_w040_autopilotAngleSaturate "APSB ECU: w040 autopilot angle saturated";
CM_ SG_ 845 APSB_w041_autopilotRateSaturated "APSB ECU: w041 autopilot rate saturated";
CM_ SG_ 845 APSB_w042_autopilotAborting "APSB ECU: w042 autopilot aborting";
CM_ SG_ 845 APSB_w043_camLongRunTime "APSB ECU: w043 cam long run time";
CM_ SG_ 845 APSB_w044_appMobileyeFailure "APSB ECU: w044 app mobileye failure";
CM_ SG_ 845 APSB_w045_radMia "APSB ECU: w045 rad mia";
CM_ SG_ 845 APSB_w046_eepromRecordAbsent "APSB ECU: w046 eeprom record absent";
CM_ SG_ 845 APSB_w047_edrEvent "APSB ECU: w047 edr event";
CM_ SG_ 845 APSB_w048_DAS_Features_Disabled "APSB ECU: w048 DAS features disabled";
CM_ SG_ 845 APSB_w049_eyeqVersionMismatch "APSB ECU: w049 eyeq version mismatch";
CM_ SG_ 845 APSB_w050_aeb_event "APSB ECU: w050 aeb event";
CM_ SG_ 845 APSB_w051_radcEcuIssue "APSB ECU: w051 radc ecu issue";
CM_ SG_ 845 APSB_w052_radcSensorIssue "APSB ECU: w052 radc sensor issue";
CM_ SG_ 845 APSB_w053_radcCommIssue "APSB ECU: w053 radc comm issue";
CM_ SG_ 845 APSB_w054_camAutofix "APSB ECU: w054 cam autofix";
CM_ SG_ 845 APSB_w055_radcVersionMismatch "APSB ECU: w055 radc version mismatch";
CM_ SG_ 845 APSB_w056_diMia "APSB ECU: w056 di mia";
CM_ SG_ 845 APSB_w057_mcuMia "APSB ECU: w057 mcu mia";
CM_ SG_ 845 APSB_w058_epbMia "APSB ECU: w058 epb mia";
CM_ SG_ 845 APSB_w059_parkMia "APSB ECU: w059 park mia";
CM_ SG_ 845 APSB_w060_fcw_event "APSB ECU: w060 fcw event";
CM_ SG_ 845 APSB_w061_tasMia "APSB ECU: w061 tas mia";
CM_ SG_ 845 APSB_w062_radcAlignment "APSB ECU: w062 radc alignment";
CM_ SG_ 845 APSB_w063_parkVersionMismatch "APSB ECU: w063 park version mismatch";
CM_ SG_ 845 APSB_w064_epasMia "APSB ECU: w064 epas mia";
CM_ BO_ 1143 "APSB ECU message: warning matrix1";
CM_ SG_ 1143 APSB_w065_deserializerOvercurren "APSB ECU: w065 deserializer overcurrent";
CM_ SG_ 1143 APSB_w066_deserializerLockLost "APSB ECU: w066 deserializer lock lost";
CM_ SG_ 1143 APSB_w067_steeringAlignment "APSB ECU: w067 steering alignment";
CM_ SG_ 1143 APSB_w068_vlInconsistency "APSB ECU: w068 vl inconsistency";
CM_ SG_ 1143 APSB_w069_apcSpaceMasked "APSB ECU: w069 apc space masked";
CM_ SG_ 1143 APSB_w070_apcIncompleteCal "APSB ECU: w070 apc incomplete cal";
CM_ SG_ 1143 APSB_w071_selfparkStarted "APSB ECU: w071 selfpark started";
CM_ SG_ 1143 APSB_w072_selfparkComplete "APSB ECU: w072 selfpark complete";
CM_ SG_ 1143 APSB_w073_issueEscalatedLDW "APSB ECU: w073 issue escalated LDW";
CM_ SG_ 1143 APSB_w074_inPathStationaryObst "APSB ECU: w074 in path stationary obst";
CM_ SG_ 1143 APSB_w075_scMia "APSB ECU: w075 sc mia";
CM_ SG_ 1143 APSB_w076_mobilEyeSetC "APSB ECU: w076 mobil eye set c";
CM_ SG_ 1143 APSB_w077_pmmActive "APSB ECU: w077 pmm active";
CM_ SG_ 1143 APSB_w078_pmmActive2 "APSB ECU: w078 pmm active2";
CM_ SG_ 1143 APSB_w079_edrAvailable "APSB ECU: w079 edr available";
CM_ SG_ 1143 APSB_w080_accFailedActivation "APSB ECU: w080 acc failed activation";
CM_ SG_ 1143 APSB_w081_pmmActiveBraking "APSB ECU: w081 pmm active braking";
CM_ SG_ 1143 APSB_w082_inPathFSviolation "APSB ECU: w082 in path f sviolation";
CM_ SG_ 1143 APSB_w083_inPathRADObject "APSB ECU: w083 in path RAD object";
CM_ SG_ 1143 APSB_w084_pmmIPSO "APSB ECU: w084 pmm IPSO";
CM_ SG_ 1143 APSB_w085_pmmSteering "APSB ECU: w085 pmm steering";
CM_ SG_ 1143 APSB_w086_robCollision "APSB ECU: w086 rob collision";
CM_ SG_ 1143 APSB_w087_DEPRECATED "APSB ECU: w087 DEPRECATED";
CM_ SG_ 1143 APSB_w088_DEPRECATED "APSB ECU: w088 DEPRECATED";
CM_ SG_ 1143 APSB_w089_DEPRECATED "APSB ECU: w089 DEPRECATED";
CM_ SG_ 1143 APSB_w090_DEPRECATED "APSB ECU: w090 DEPRECATED";
CM_ SG_ 1143 APSB_w091_DEPRECATED "APSB ECU: w091 DEPRECATED";
CM_ SG_ 1143 APSB_w092_DEPRECATED "APSB ECU: w092 DEPRECATED";
CM_ SG_ 1143 APSB_w093_DEPRECATED "APSB ECU: w093 DEPRECATED";
CM_ SG_ 1143 APSB_w094_DEPRECATED "APSB ECU: w094 DEPRECATED";
CM_ SG_ 1143 APSB_w095_DEPRECATED "APSB ECU: w095 DEPRECATED";
CM_ SG_ 1143 APSB_w096_DEPRECATED "APSB ECU: w096 DEPRECATED";
CM_ SG_ 1143 APSB_w097_DEPRECATED "APSB ECU: w097 DEPRECATED";
CM_ SG_ 1143 APSB_w098_DEPRECATED "APSB ECU: w098 DEPRECATED";
CM_ SG_ 1143 APSB_w099_DEPRECATED "APSB ECU: w099 DEPRECATED";
CM_ SG_ 1143 APSB_w100_DEPRECATED "APSB ECU: w100 DEPRECATED";
CM_ SG_ 1143 APSB_w101_DEPRECATED "APSB ECU: w101 DEPRECATED";
CM_ SG_ 1143 APSB_w102_DEPRECATED "APSB ECU: w102 DEPRECATED";
CM_ SG_ 1143 APSB_w103_robExperimentalAEB "APSB ECU: w103 rob experimental AEB";
CM_ SG_ 1143 APSB_w104_DEPRECATED "APSB ECU: w104 DEPRECATED";
CM_ SG_ 1143 APSB_w105_DEPRECATED "APSB ECU: w105 DEPRECATED";
CM_ SG_ 1143 APSB_w106_torsionBarOffset "APSB ECU: w106 torsion bar offset";
CM_ BO_ 942 "APSB ECU message: warning matrix2";
CM_ SG_ 942 APSB_w129_ECU_Power_Issue "APSB ECU: w129 ECU power issue";
CM_ SG_ 942 APSB_w130_ECU_Thermal_Issue "APSB ECU: w130 ECU thermal issue";
CM_ SG_ 942 APSB_w131_trap_exception "APSB ECU: w131 trap exception";
CM_ SG_ 942 APSB_w132_appVersionMismatch "APSB ECU: w132 app version mismatch";
CM_ SG_ 942 APSB_w133_ETHSwitchError "APSB ECU: w133 ETH switch error";
CM_ SG_ 942 APSB_w134_appMia "APSB ECU: w134 app mia";
CM_ SG_ 942 APSB_w135_appCritical "APSB ECU: w135 app critical";
CM_ SG_ 942 APSB_w136_gpsDisabled "APSB ECU: w136 gps disabled";
CM_ SG_ 942 APSB_w137_gpsFaultReset "APSB ECU: w137 gps fault reset";
CM_ SG_ 942 APSB_w138_gpsComIssue "APSB ECU: w138 gps com issue";
CM_ SG_ 942 APSB_w139_udpBufferOverflow "APSB ECU: w139 udp buffer overflow";
CM_ SG_ 942 APSB_w140_vcfrontMiaVehicleBus "APSB ECU: w140 vcfront mia vehicle bus";
CM_ SG_ 942 APSB_w141_rcmMiaPartyBus "APSB ECU: w141 rcm mia party bus";
CM_ SG_ 942 APSB_w142_diMiaPartyBus "APSB ECU: w142 di mia party bus";
CM_ SG_ 942 APSB_w143_espMiaPartyBus "APSB ECU: w143 esp mia party bus";
CM_ SG_ 942 APSB_w144_vcleftMiaPartyBus "APSB ECU: w144 vcleft mia party bus";
CM_ SG_ 942 APSB_w145_vcrightMiaPartyBus "APSB ECU: w145 vcright mia party bus";
CM_ SG_ 942 APSB_w146_epas3pMiaPartyBus "APSB ECU: w146 epas3p mia party bus";
CM_ SG_ 942 APSB_w147_vcleftMiaVehBus "APSB ECU: w147 vcleft mia veh bus";
CM_ SG_ 942 APSB_w148_vcrightMiaVehBus "APSB ECU: w148 vcright mia veh bus";
CM_ SG_ 942 APSB_w149_epblMiaVehBus "APSB ECU: w149 epbl mia veh bus";
CM_ SG_ 942 APSB_w150_sccmMiaVehBus "APSB ECU: w150 sccm mia veh bus";
CM_ SG_ 942 APSB_w151_apRecovered "APSB ECU: w151 ap recovered";
CM_ SG_ 942 APSB_w152_gpsFusionStatus "APSB ECU: w152 gps fusion status";
CM_ SG_ 942 APSB_w153_eacInhibit "APSB ECU: w153 eac inhibit";
CM_ SG_ 942 APSB_w155_ethLwipError "APSB ECU: w155 eth lwip error";
CM_ SG_ 942 APSB_w156_lwipAssert "APSB ECU: w156 lwip assert";
CM_ SG_ 942 APSB_w157_autopilotReboot "APSB ECU: w157 autopilot reboot";
CM_ SG_ 942 APSB_w158_apbMia "APSB ECU: w158 apb mia";
CM_ SG_ 942 APSB_w159_apbCritical "APSB ECU: w159 apb critical";
CM_ SG_ 942 APSB_w160_apbVersionMismatch "APSB ECU: w160 apb version mismatch";
CM_ SG_ 942 APSB_w161_gpsAntennaDisconnected "APSB ECU: w161 gps antenna disconnected";
CM_ SG_ 942 APSB_w162_TurboA_DisRegPgoodErr "APSB ECU: w162 turbo a dis reg pgood err";
CM_ SG_ 942 APSB_w163_TurboA_DisRegNFault "APSB ECU: w163 turbo a dis reg n fault";
CM_ SG_ 942 APSB_w164_TurboA_12VFuseFault "APSB ECU: w164 turbo a 12 v fuse fault";
CM_ SG_ 942 APSB_w165_TurboA_Temp_NOS "APSB ECU: w165 turbo a temp NOS";
CM_ SG_ 942 APSB_w166_TurboA_SMSLockStepErr "APSB ECU: w166 turbo a SMS lock step err";
CM_ SG_ 942 APSB_w167_TurboA_TMU_Throttle "APSB ECU: w167 turbo a TMU throttle";
CM_ SG_ 942 APSB_w168_TurboA_SMS_WDOG "APSB ECU: w168 turbo a SMS WDOG";
CM_ SG_ 942 APSB_w169_TurboA_SCS_LKUP "APSB ECU: w169 turbo a SCS LKUP";
CM_ SG_ 942 APSB_w170_TurboA_A72_watchdog "APSB ECU: w170 turbo a A72 watchdog";
CM_ SG_ 942 APSB_w171_TurboA_SMS_taskUtilErr "APSB ECU: w171 turbo a SMS task util err";
CM_ SG_ 942 APSB_w172_apFeaturesUnavailable "APSB ECU: w172 ap features unavailable";
CM_ SG_ 942 APSB_w178_TurboB_DisRegPgoodErr "APSB ECU: w178 turbo b dis reg pgood err";
CM_ SG_ 942 APSB_w179_TurboB_DisRegNFault "APSB ECU: w179 turbo b dis reg n fault";
CM_ SG_ 942 APSB_w180_TurboB_12VFuseFault "APSB ECU: w180 turbo b 12 v fuse fault";
CM_ SG_ 942 APSB_w181_TurboB_Temp_NOS "APSB ECU: w181 turbo b temp NOS";
CM_ SG_ 942 APSB_w182_TurboB_SMSLockStepErr "APSB ECU: w182 turbo b SMS lock step err";
CM_ SG_ 942 APSB_w183_TurboB_TMU_Throttle "APSB ECU: w183 turbo b TMU throttle";
CM_ SG_ 942 APSB_w184_TurboB_SMS_WDOG "APSB ECU: w184 turbo b SMS WDOG";
CM_ SG_ 942 APSB_w185_TurboB_SCS_LKUP "APSB ECU: w185 turbo b SCS LKUP";
CM_ SG_ 942 APSB_w186_TurboB_A72_watchdog "APSB ECU: w186 turbo b A72 watchdog";
CM_ SG_ 942 APSB_w187_TurboB_SMS_taskUtilErr "APSB ECU: w187 turbo b SMS task util err";
CM_ SG_ 942 APSB_w188_otherTurboUartMIA "APSB ECU: w188 other turbo uart MIA";
CM_ SG_ 942 APSB_w189_vcfrontMiaPartyBus "APSB ECU: w189 vcfront mia party bus";
CM_ SG_ 942 APSB_w190_iboosterMia "APSB ECU: w190 ibooster mia";
CM_ SG_ 942 APSB_w191_timesyncError "APSB ECU: w191 timesync error";
CM_ SG_ 942 APSB_w192_CANFault "APSB ECU: w192 CAN fault";
CM_ BO_ 976 "APSB ECU message: warning matrix3";
CM_ SG_ 976 APSB_w193_camWindshieldUnclean "APSB ECU: w193 cam windshield unclean";
CM_ SG_ 976 APSB_w194_accDriverResumeRqrd "APSB ECU: w194 acc driver resume rqrd";
CM_ SG_ 976 APSB_w195_scwUnavailable "APSB ECU: w195 scw unavailable";
CM_ SG_ 976 APSB_w196_stopSignWarning "APSB ECU: w196 stop sign warning";
CM_ SG_ 976 APSB_w197_redLightWarning "APSB ECU: w197 red light warning";
CM_ SG_ 976 APSB_w198_tsrUnavailable "APSB ECU: w198 tsr unavailable";
CM_ SG_ 976 APSB_w199_apcAbort "APSB ECU: w199 apc abort";
CM_ SG_ 976 APSB_w200_lcSlowdown "APSB ECU: w200 lc slowdown";
CM_ SG_ 976 APSB_w201_lcAborting "APSB ECU: w201 lc aborting";
CM_ SG_ 976 APSB_w202_scwNoisyEnvironment "APSB ECU: w202 scw noisy environment";
CM_ SG_ 976 APSB_w203_apcActivation "APSB ECU: w203 apc activation";
CM_ SG_ 976 APSB_w204_apcFinalFront "APSB ECU: w204 apc final front";
CM_ SG_ 976 APSB_w205_apcFinalRear "APSB ECU: w205 apc final rear";
CM_ SG_ 976 APSB_w206_autosteerNotEnabled "APSB ECU: w206 autosteer not enabled";
CM_ SG_ 976 APSB_w207_autosteerUnavailable "APSB ECU: w207 autosteer unavailable";
CM_ SG_ 976 APSB_w208_rackDetected "APSB ECU: w208 rack detected";
CM_ SG_ 976 APSB_w209_autoSummonRequest "APSB ECU: w209 auto summon request";
CM_ SG_ 976 APSB_w210_camObstrcted "APSB ECU: w210 cam obstrcted";
CM_ SG_ 976 APSB_w211_accNoSeatBelt "APSB ECU: w211 acc no seat belt";
CM_ SG_ 976 APSB_w212_lcUnavailableStrikeOut "APSB ECU: w212 lc unavailable strike out";
CM_ SG_ 976 APSB_w213_autosteerStruckOut "APSB ECU: w213 autosteer struck out";
CM_ SG_ 976 APSB_w214_driverNotIntracting "APSB ECU: w214 driver not intracting";
CM_ SG_ 976 APSB_w215_contDriverNotIntractin "APSB ECU: w215 cont driver not intracting";
CM_ SG_ 976 APSB_w216_driverOverriding "APSB ECU: w216 driver overriding";
CM_ SG_ 976 APSB_w217_lcUnavailableSpeeding "APSB ECU: w217 lc unavailable speeding";
CM_ SG_ 976 APSB_w218_lcSpeedExceededLimit "APSB ECU: w218 lc speed exceeded limit";
CM_ SG_ 976 APSB_w219_lcTempUnavailableSpeed "APSB ECU: w219 lc temp unavailable speed";
CM_ SG_ 976 APSB_w220_lcTempUnavailableRoad "APSB ECU: w220 lc temp unavailable road";
CM_ SG_ 976 APSB_w221_accRadarBlind "APSB ECU: w221 acc radar blind";
CM_ SG_ 976 APSB_w222_accCameraBlind "APSB ECU: w222 acc camera blind";
CM_ SG_ 976 APSB_w223_accObjectInPath "APSB ECU: w223 acc object in path";
CM_ SG_ 976 APSB_w224_accCameraCalibration "APSB ECU: w224 acc camera calibration";
CM_ SG_ 976 APSB_w225_lcDegradedVisSpeedLmt "APSB ECU: w225 lc degraded vis speed lmt";
CM_ SG_ 976 APSB_w226_lcCamCalNeededSpeedLmt "APSB ECU: w226 lc cam cal needed speed lmt";
CM_ SG_ 976 APSB_w227_virtualWallBlocked "APSB ECU: w227 virtual wall blocked";
CM_ SG_ 976 APSB_w228_DEPRECATED "APSB ECU: w228 DEPRECATED";
CM_ SG_ 976 APSB_w229_alcUltrasoundDamaged "APSB ECU: w229 alc ultrasound damaged";
CM_ SG_ 976 APSB_w230_alcUltrasoundBlocked "APSB ECU: w230 alc ultrasound blocked";
CM_ SG_ 976 APSB_w231_idfEvent "APSB ECU: w231 idf event";
CM_ SG_ 976 APSB_w232_laneChangeRequested "APSB ECU: w232 lane change requested";
CM_ SG_ 976 APSB_w235_a72LoopDetected "APSB ECU: w235 a72 loop detected";
CM_ SG_ 976 APSB_w236_canSharedMemError "APSB ECU: w236 can shared mem error";
CM_ SG_ 976 APSB_w237_faultMgrEventDetected "APSB ECU: w237 fault mgr event detected";
CM_ SG_ 976 APSB_w238_resetReason "APSB ECU: w238 reset reason";
CM_ SG_ 976 APSB_w241_ddrInitFailures "APSB ECU: w241 ddr init failures";
CM_ SG_ 976 APSB_w242_tripMBISTFailure "APSB ECU: w242 trip MBIST failure";
CM_ SG_ 976 APSB_w243_tripHWErrorStatus "APSB ECU: w243 trip HW error status";
CM_ SG_ 976 APSB_w244_gpuHWFaultStatus "APSB ECU: w244 gpu HW fault status";
CM_ SG_ 976 APSB_w245_eloopRxFromUnexpectedS "APSB ECU: w245 eloop rx from unexpected source MAC";
CM_ SG_ 976 APSB_w246_ethloopSwitchPortLinkD "APSB ECU: w246 ethloop switch port link down";
CM_ SG_ 976 APSB_w247_ethernetFrameError "APSB ECU: w247 ethernet frame error";
CM_ SG_ 976 APSB_w248_ethloopSwitchPoorSqi "APSB ECU: w248 ethloop switch poor sqi";
CM_ SG_ 976 APSB_w249_ufsFailures "APSB ECU: w249 ufs failures";
CM_ SG_ 976 APSB_w250_ethloopSwitchMemUsageT "APSB ECU: w250 ethloop switch mem usage too high port2";
CM_ SG_ 976 APSB_w251_ethloopSwitchMemUsageT "APSB ECU: w251 ethloop switch mem usage too high port3";
CM_ SG_ 976 APSB_w252_ethSwitchPortLinkDown "APSB ECU: w252 eth switch port link down";
CM_ SG_ 976 APSB_w253_powerStateTimeout "APSB ECU: w253 power state timeout";
CM_ SG_ 976 APSB_w254_sleepStateTimeout "APSB ECU: w254 sleep state timeout";
CM_ SG_ 976 APSB_w255_bootHealth "APSB ECU: w255 boot health";
CM_ BO_ 1003 "APSB ECU message: warning matrix4";
CM_ SG_ 1003 APSB_w257_assertFailure "APSB ECU: w257 assert failure";
CM_ SG_ 1003 APSB_w258_qspiFlashSectorChecksu "APSB ECU: w258 qspi flash sector checksum mismatch";
CM_ SG_ 1003 APSB_w259_qspiFailure "APSB ECU: w259 qspi failure";
CM_ SG_ 1003 APSB_w260_pgoodFailure "APSB ECU: w260 pgood failure";
CM_ SG_ 1003 APSB_w261_vrmFaultGrpA "APSB ECU: w261 vrm fault grp a";
CM_ SG_ 1003 APSB_w262_vrmFaultGrpB "APSB ECU: w262 vrm fault grp b";
CM_ SG_ 1003 APSB_w263_vrmFaultGrpC "APSB ECU: w263 vrm fault grp c";
CM_ SG_ 1003 APSB_w264_ddrPhy0Failures "APSB ECU: w264 ddr phy0 failures";
CM_ SG_ 1003 APSB_w265_ddrPhy1Failures "APSB ECU: w265 ddr phy1 failures";
CM_ SG_ 1003 APSB_w266_ddrPhy2Failures "APSB ECU: w266 ddr phy2 failures";
CM_ SG_ 1003 APSB_w267_ddrPhy3Failures "APSB ECU: w267 ddr phy3 failures";
CM_ SG_ 1003 APSB_w268_ddrControllerFailures "APSB ECU: w268 ddr controller failures";
CM_ SG_ 1003 APSB_w269_ethSwitchRxPageCountTo "APSB ECU: w269 eth switch rx page count too high port0 3";
CM_ SG_ 1003 APSB_w270_ethSwitchRxPageCountTo "APSB ECU: w270 eth switch rx page count too high port4 7";
CM_ SG_ 1003 APSB_w271_ddrScheduler0EccErrors "APSB ECU: w271 ddr scheduler0 ecc errors";
CM_ SG_ 1003 APSB_w272_ddrScheduler1EccErrors "APSB ECU: w272 ddr scheduler1 ecc errors";
CM_ SG_ 1003 APSB_w273_ddrScheduler2EccErrors "APSB ECU: w273 ddr scheduler2 ecc errors";
CM_ SG_ 1003 APSB_w274_ddrScheduler3EccErrors "APSB ECU: w274 ddr scheduler3 ecc errors";
CM_ SG_ 1003 APSB_w275_ddrScheduler4EccErrors "APSB ECU: w275 ddr scheduler4 ecc errors";
CM_ SG_ 1003 APSB_w276_ddrScheduler5EccErrors "APSB ECU: w276 ddr scheduler5 ecc errors";
CM_ SG_ 1003 APSB_w277_ddrScheduler6EccErrors "APSB ECU: w277 ddr scheduler6 ecc errors";
CM_ SG_ 1003 APSB_w278_ddrScheduler7EccErrors "APSB ECU: w278 ddr scheduler7 ecc errors";
CM_ SG_ 1003 APSB_w279_ufsPartitionError "APSB ECU: w279 ufs partition error";
CM_ SG_ 1003 APSB_w280_pepsMia "APSB ECU: w280 peps mia";
CM_ SG_ 1003 APSB_w281_rsaMia "APSB ECU: w281 rsa mia";
CM_ SG_ 1003 APSB_w282_smmuError "APSB ECU: w282 smmu error";
CM_ SG_ 1003 APSB_w283_psfaMia "APSB ECU: w283 psfa mia";
CM_ SG_ 1003 APSB_w284_cam12VBuckBoostAPwrIss "APSB ECU: w284 cam12 v buck boost a pwr issue";
CM_ SG_ 1003 APSB_w285_cam12VBuckBoostBPwrIss "APSB ECU: w285 cam12 v buck boost b pwr issue";
CM_ SG_ 1003 APSB_w286_cam12VEFuseAPrimaryIss "APSB ECU: w286 cam12 VE fuse a primary issue";
CM_ SG_ 1003 APSB_w287_cam12VEFuseASecondaryI "APSB ECU: w287 cam12 VE fuse a secondary issue";
CM_ SG_ 1003 APSB_w288_brakeboosterMia "APSB ECU: w288 brakebooster mia";
CM_ SG_ 1003 APSB_w289_turboTemperatureWarnin "APSB ECU: w289 turbo temperature warning";
CM_ SG_ 1003 APSB_w290_cam12VBuckBoostBPwrRin "APSB ECU: w290 cam12 v buck boost b pwr ringing";
CM_ SG_ 1003 APSB_w291_eplannerError "APSB ECU: w291 eplanner error";
CM_ SG_ 1003 APSB_w292_CH_busOff "APSB ECU: w292 CH bus off";
CM_ SG_ 1003 APSB_w293_PARTY_busOff "APSB ECU: w293 PARTY bus off";
CM_ SG_ 1003 APSB_w294_VEH_busOff "APSB ECU: w294 VEH bus off";
CM_ SG_ 1003 APSB_w295_PT_busOff "APSB ECU: w295 PT bus off";
CM_ SG_ 1003 APSB_w296_wdogMonTaskDeadlineMis "APSB ECU: w296 wdog mon task deadline miss";
CM_ SG_ 1003 APSB_w297_earlyWDogAlert "APSB ECU: w297 early w dog alert";
CM_ SG_ 1003 APSB_w298_cpuToApCanSharedMemErr "APSB ECU: w298 cpu to ap can shared mem error";
CM_ SG_ 1003 APSB_w299_apToCpuCanSharedMemErr "APSB ECU: w299 ap to cpu can shared mem error";
CM_ SG_ 1003 APSB_w300_sharedMemoryAccessErro "APSB ECU: w300 shared memory access error";
CM_ SG_ 1003 APSB_w301_nocTimeoutDetected "APSB ECU: w301 noc timeout detected";
CM_ SG_ 1003 APSB_w302_canAPShmFifoFull "APSB ECU: w302 can AP shm fifo full";
CM_ SG_ 1003 APSB_w303_canAPShmFifoEmpty "APSB ECU: w303 can AP shm fifo empty";
CM_ SG_ 1003 APSB_w304_dataAbort "APSB ECU: w304 data abort";
CM_ SG_ 1003 APSB_w305_gpsPgoodFailure "APSB ECU: w305 gps pgood failure";
CM_ SG_ 1003 APSB_w306_ethPgoodFailure "APSB ECU: w306 eth pgood failure";
CM_ SG_ 1003 APSB_w307_eccEventDetected "APSB ECU: w307 ecc event detected";
CM_ SG_ 1003 APSB_w308_pmicErrorDetected "APSB ECU: w308 pmic error detected";
CM_ SG_ 1003 APSB_w309_ethBridgeDown "APSB ECU: w309 eth bridge down";
CM_ SG_ 1003 APSB_w310_wakeBootMetrics "APSB ECU: w310 wake boot metrics";
CM_ SG_ 1003 APSB_w311_apbdgDasMia "APSB ECU: w311 apbdg das mia";
CM_ SG_ 1003 APSB_w312_apbdgApMia "APSB ECU: w312 apbdg ap mia";
CM_ SG_ 1003 APSB_w313_BDY_busOff "APSB ECU: w313 BDY bus off";
CM_ SG_ 1003 APSB_w315_epas3pMiaBdyBus "APSB ECU: w315 epas3p mia bdy bus";
CM_ SG_ 1003 APSB_w316_apBootHealth "APSB ECU: w316 ap boot health";
CM_ SG_ 1003 APSB_w317_uiMia "APSB ECU: w317 ui mia";
CM_ SG_ 1003 APSB_w318_ethernetNetworkBufferH "APSB ECU: w318 ethernet network buffer high watermark";
CM_ SG_ 1003 APSB_w319_vehDasImposterDetected "APSB ECU: w319 veh das imposter detected";
CM_ SG_ 1003 APSB_w320_eplannerPreconditionsM "APSB ECU: w320 eplanner preconditions met";
CM_ BO_ 1481 "Driver assistance computer (secondary) message: alert log";
CM_ SG_ 1481 APS_alertID "Driver assistance computer (secondary): alert ID";
CM_ SG_ 1481 APS_alertSource "Driver assistance computer (secondary): alert source";
CM_ SG_ 1481 APS_alertState "Driver assistance computer (secondary): alert state";
CM_ SG_ 1481 APS_sw010_a04calibNotDone "Driver assistance computer (secondary): sw010 a04calib not done";
CM_ SG_ 1481 APS_sw010_a05calibReqd "Driver assistance computer (secondary): sw010 a05calib reqd";
CM_ SG_ 1481 APS_sw010_a06calibNotOK "Driver assistance computer (secondary): sw010 a06calib not OK";
CM_ SG_ 1481 APS_sw010_a08PlantMode "Driver assistance computer (secondary): sw010 a08 plant mode";
CM_ SG_ 1481 APS_sw010_HorizontalMisalignment "Driver assistance computer (secondary): sw010 horizontal misalignment";
CM_ SG_ 1481 APS_sw010_VerticalMisalignment "Driver assistance computer (secondary): sw010 vertical misalignment";
CM_ SG_ 1481 APS_sw010_unusedBits "Driver assistance computer (secondary): sw010 unused bits";
CM_ SG_ 1481 APS_sw010_VmaPlausibility "Driver assistance computer (secondary): sw010 vma plausibility";
CM_ SG_ 1481 APS_sw019_taskId "Driver assistance computer (secondary): sw019 task id";
CM_ SG_ 1481 APS_sw019_numFreeBytes "Driver assistance computer (secondary): sw019 num free bytes";
CM_ SG_ 1481 APS_sw019_timeStamp "Driver assistance computer (secondary): sw019 time stamp";
CM_ SG_ 1481 APS_sw020_unusedW0 "Driver assistance computer (secondary): sw020 unused W0";
CM_ SG_ 1481 APS_sw020_unusedW1 "Driver assistance computer (secondary): sw020 unused W1";
CM_ SG_ 1481 APS_sw020_unusedW2 "Driver assistance computer (secondary): sw020 unused W2";
CM_ SG_ 1481 APS_sw021_tempSensorId "Driver assistance computer (secondary): sw021 temp sensor id";
CM_ SG_ 1481 APS_sw021_minThreshold "Driver assistance computer (secondary): sw021 min threshold";
CM_ SG_ 1481 APS_sw021_maxThreshold "Driver assistance computer (secondary): sw021 max threshold";
CM_ SG_ 1481 APS_sw021_currentTemperature "Driver assistance computer (secondary): sw021 current temperature";
CM_ SG_ 1481 APS_sw021_unusedWord "Driver assistance computer (secondary): sw021 unused word";
CM_ SG_ 1481 APS_sw024_Task_ID "Driver assistance computer (secondary): sw024 task ID";
CM_ SG_ 1481 APS_sw024_numVirtualLaneVeh "Driver assistance computer (secondary): sw024 num virtual lane veh";
CM_ SG_ 1481 APS_sw024_currentVehicleApp "Driver assistance computer (secondary): sw024 current vehicle app";
CM_ SG_ 1481 APS_sw024_taskProgramCounter "Driver assistance computer (secondary): sw024 task program counter";
CM_ SG_ 1481 APS_sw027_JTAG_Reset "Driver assistance computer (secondary): sw027 JTAG reset";
CM_ SG_ 1481 APS_sw027_Core_Reset "Driver assistance computer (secondary): sw027 core reset";
CM_ SG_ 1481 APS_sw027_Unused_Bit_0 "Driver assistance computer (secondary): sw027 unused bit 0";
CM_ SG_ 1481 APS_sw027_CPU_Checkstop_Error "Driver assistance computer (secondary): sw027 CPU checkstop error";
CM_ SG_ 1481 APS_sw027_PLL_0_Failure "Driver assistance computer (secondary): sw027 PLL 0 failure";
CM_ SG_ 1481 APS_sw027_Clock_Monitor_0_Low "Driver assistance computer (secondary): sw027 clock monitor 0 low";
CM_ SG_ 1481 APS_sw027_Clock_Monitor_0_Off "Driver assistance computer (secondary): sw027 clock monitor 0 off";
CM_ SG_ 1481 APS_sw027_LVD_4v5 "Driver assistance computer (secondary): sw027 LVD 4v5";
CM_ SG_ 1481 APS_sw027_Flash_Fatal_Error "Driver assistance computer (secondary): sw027 flash fatal error";
CM_ SG_ 1481 APS_sw027_PLL_1_Failure "Driver assistance computer (secondary): sw027 PLL 1 failure";
CM_ SG_ 1481 APS_sw027_Unused_Bit_1 "Driver assistance computer (secondary): sw027 unused bit 1";
CM_ SG_ 1481 APS_sw027_f_PLL_1_Off "Driver assistance computer (secondary): sw027 f PLL 1 off";
CM_ SG_ 1481 APS_sw027_Unused_Nibble "Driver assistance computer (secondary): sw027 unused nibble";
CM_ SG_ 1481 APS_sw027_LVD_1v2 "Driver assistance computer (secondary): sw027 LVD 1v2";
CM_ SG_ 1481 APS_sw027_Unused_Bit_2 "Driver assistance computer (secondary): sw027 unused bit 2";
CM_ SG_ 1481 APS_sw027_Watchdog "Driver assistance computer (secondary): sw027 watchdog";
CM_ SG_ 1481 APS_sw027_Unused_Bit_3 "Driver assistance computer (secondary): sw027 unused bit 3";
CM_ SG_ 1481 APS_sw027_LVD_2v7_VREG "Driver assistance computer (secondary): sw027 LVD 2v7 VREG";
CM_ SG_ 1481 APS_sw027_LVD_2v7_Flash "Driver assistance computer (secondary): sw027 LVD 2v7 flash";
CM_ SG_ 1481 APS_sw027_LVD_2v7_IO "Driver assistance computer (secondary): sw027 LVD 2v7 IO";
CM_ SG_ 1481 APS_sw027_Unused_Bit_4 "Driver assistance computer (secondary): sw027 unused bit 4";
CM_ SG_ 1481 APS_sw027_Unused_Byte "Driver assistance computer (secondary): sw027 unused byte";
CM_ SG_ 1481 APS_sw027_ESR0 "Driver assistance computer (secondary): sw027 ESR0";
CM_ SG_ 1481 APS_sw027_ESR1 "Driver assistance computer (secondary): sw027 ESR1";
CM_ SG_ 1481 APS_sw027_SW "Driver assistance computer (secondary): sw027 SW";
CM_ SG_ 1481 APS_sw027_STM0 "Driver assistance computer (secondary): sw027 STM0";
CM_ SG_ 1481 APS_sw027_STM1 "Driver assistance computer (secondary): sw027 STM1";
CM_ SG_ 1481 APS_sw027_STM2 "Driver assistance computer (secondary): sw027 STM2";
CM_ SG_ 1481 APS_sw027_CBS_SYSTEM "Driver assistance computer (secondary): sw027 CBS SYSTEM";
CM_ SG_ 1481 APS_sw027_CBS_DEBUG "Driver assistance computer (secondary): sw027 CBS DEBUG";
CM_ SG_ 1481 APS_sw027_CBS_APP "Driver assistance computer (secondary): sw027 CBS APP";
CM_ SG_ 1481 APS_sw027_EVR13 "Driver assistance computer (secondary): sw027 EVR13";
CM_ SG_ 1481 APS_sw027_EVR33 "Driver assistance computer (secondary): sw027 EVR33";
CM_ SG_ 1481 APS_sw027_SWD "Driver assistance computer (secondary): sw027 SWD";
CM_ SG_ 1481 APS_sw027_STDBY_WDG "Driver assistance computer (secondary): sw027 STDBY WDG";
CM_ SG_ 1481 APS_sw027_PORST "Driver assistance computer (secondary): sw027 PORST";
CM_ SG_ 1481 APS_sw027_Unused_word "Driver assistance computer (secondary): sw027 unused word";
CM_ SG_ 1481 APS_sw030_heaterState "Driver assistance computer (secondary): sw030 heater state";
CM_ SG_ 1481 APS_sw030_unusedByte "Driver assistance computer (secondary): sw030 unused byte";
CM_ SG_ 1481 APS_sw030_unusedW0 "Driver assistance computer (secondary): sw030 unused W0";
CM_ SG_ 1481 APS_sw030_unusedW1 "Driver assistance computer (secondary): sw030 unused W1";
CM_ SG_ 1481 APS_sw033_carConfig "Driver assistance computer (secondary): sw033 car config";
CM_ SG_ 1481 APS_sw033_chNm "Driver assistance computer (secondary): sw033 ch nm";
CM_ SG_ 1481 APS_sw033_vin "Driver assistance computer (secondary): sw033 vin";
CM_ SG_ 1481 APS_sw033_carState "Driver assistance computer (secondary): sw033 car state";
CM_ SG_ 1481 APS_sw034_sccmMia "Driver assistance computer (secondary): sw034 sccm mia";
CM_ SG_ 1481 APS_sw034_unusedByte "Driver assistance computer (secondary): sw034 unused byte";
CM_ SG_ 1481 APS_sw034_unusedW0 "Driver assistance computer (secondary): sw034 unused W0";
CM_ SG_ 1481 APS_sw034_unusedW1 "Driver assistance computer (secondary): sw034 unused W1";
CM_ SG_ 1481 APS_sw035_wheelSpeeds "Driver assistance computer (secondary): sw035 wheel speeds";
CM_ SG_ 1481 APS_sw035_status "Driver assistance computer (secondary): sw035 status";
CM_ SG_ 1481 APS_sw035_wheelRotation "Driver assistance computer (secondary): sw035 wheel rotation";
CM_ SG_ 1481 APS_sw035_redundantBrakingStatus "Driver assistance computer (secondary): sw035 redundant braking status";
CM_ SG_ 1481 APS_sw036_bdyMia "Driver assistance computer (secondary): sw036 bdy mia";
CM_ SG_ 1481 APS_sw036_unusedByte "Driver assistance computer (secondary): sw036 unused byte";
CM_ SG_ 1481 APS_sw036_unusedW0 "Driver assistance computer (secondary): sw036 unused W0";
CM_ SG_ 1481 APS_sw036_unusedW1 "Driver assistance computer (secondary): sw036 unused W1";
CM_ SG_ 1481 APS_sw039_sdm_rcm_Mia "Driver assistance computer (secondary): sw039 sdm rcm mia";
CM_ SG_ 1481 APS_sw039_unusedByte "Driver assistance computer (secondary): sw039 unused byte";
CM_ SG_ 1481 APS_sw039_unusedW0 "Driver assistance computer (secondary): sw039 unused W0";
CM_ SG_ 1481 APS_sw039_unusedW1 "Driver assistance computer (secondary): sw039 unused W1";
CM_ SG_ 1481 APS_sw045_radMia "Driver assistance computer (secondary): sw045 rad mia";
CM_ SG_ 1481 APS_sw045_unusedByte "Driver assistance computer (secondary): sw045 unused byte";
CM_ SG_ 1481 APS_sw045_unusedW0 "Driver assistance computer (secondary): sw045 unused W0";
CM_ SG_ 1481 APS_sw045_unusedW1 "Driver assistance computer (secondary): sw045 unused W1";
CM_ SG_ 1481 APS_sw048_swAssert "Driver assistance computer (secondary): sw048 sw assert";
CM_ SG_ 1481 APS_sw048_thermalIssue "Driver assistance computer (secondary): sw048 thermal issue";
CM_ SG_ 1481 APS_sw048_powerIssue "Driver assistance computer (secondary): sw048 power issue";
CM_ SG_ 1481 APS_sw048_stackOverflow "Driver assistance computer (secondary): sw048 stack overflow";
CM_ SG_ 1481 APS_sw048_checkStop "Driver assistance computer (secondary): sw048 check stop";
CM_ SG_ 1481 APS_sw048_ecuWatchdog "Driver assistance computer (secondary): sw048 ecu watchdog";
CM_ SG_ 1481 APS_sw048_ecuReset "Driver assistance computer (secondary): sw048 ecu reset";
CM_ SG_ 1481 APS_sw048_radcVersionMismatch "Driver assistance computer (secondary): sw048 radc version mismatch";
CM_ SG_ 1481 APS_sw048_radcCalibration "Driver assistance computer (secondary): sw048 radc calibration";
CM_ SG_ 1481 APS_sw048_radcMia "Driver assistance computer (secondary): sw048 radc mia";
CM_ SG_ 1481 APS_sw048_eyeQVersionMismatch "Driver assistance computer (secondary): sw048 eye q version mismatch";
CM_ SG_ 1481 APS_sw048_camIssue "Driver assistance computer (secondary): sw048 cam issue";
CM_ SG_ 1481 APS_sw048_parkerIssue "Driver assistance computer (secondary): sw048 parker issue";
CM_ SG_ 1481 APS_sw048_prolongedUiMia "Driver assistance computer (secondary): sw048 prolonged ui mia";
CM_ SG_ 1481 APS_sw048_uiMiaAtBootup "Driver assistance computer (secondary): sw048 ui mia at bootup";
CM_ SG_ 1481 APS_sw051_a01ecuInternalPerf "Driver assistance computer (secondary): sw051 a01ecu internal perf";
CM_ SG_ 1481 APS_sw051_a02flashPerformance "Driver assistance computer (secondary): sw051 a02flash performance";
CM_ SG_ 1481 APS_sw051_a03vBatHigh "Driver assistance computer (secondary): sw051 a03v bat high";
CM_ SG_ 1481 APS_sw051_a09configMismatch "Driver assistance computer (secondary): sw051 a09config mismatch";
CM_ SG_ 1481 APS_sw051_a52radomeHtrInop "Driver assistance computer (secondary): sw051 a52radome htr inop";
CM_ SG_ 1481 APS_sw051_unused "Driver assistance computer (secondary): sw051 unused";
CM_ SG_ 1481 APS_sw051_SCUTemperature "Driver assistance computer (secondary): sw051 SCU temperature";
CM_ SG_ 1481 APS_sw051_HWFail "Driver assistance computer (secondary): sw051 HW fail";
CM_ SG_ 1481 APS_sw051_SGUFail "Driver assistance computer (secondary): sw051 SGU fail";
CM_ SG_ 1481 APS_sw051_unusedBits "Driver assistance computer (secondary): sw051 unused bits";
CM_ SG_ 1481 APS_sw051_unusedB0 "Driver assistance computer (secondary): sw051 unused B0";
CM_ SG_ 1481 APS_sw051_unusedW1 "Driver assistance computer (secondary): sw051 unused W1";
CM_ SG_ 1481 APS_sw052_a07sensorBlinded "Driver assistance computer (secondary): sw052 a07sensor blinded";
CM_ SG_ 1481 APS_sw052_sensorDirty "Driver assistance computer (secondary): sw052 sensor dirty";
CM_ SG_ 1481 APS_sw052_HWFail "Driver assistance computer (secondary): sw052 HW fail";
CM_ SG_ 1481 APS_sw052_overTemperature "Driver assistance computer (secondary): sw052 over temperature";
CM_ SG_ 1481 APS_sw052_underTemperature "Driver assistance computer (secondary): sw052 under temperature";
CM_ SG_ 1481 APS_sw052_chirpError "Driver assistance computer (secondary): sw052 chirp error";
CM_ SG_ 1481 APS_sw052_rspError "Driver assistance computer (secondary): sw052 rsp error";
CM_ SG_ 1481 APS_sw052_sensorBlocked "Driver assistance computer (secondary): sw052 sensor blocked";
CM_ SG_ 1481 APS_sw053_a10canBusOff "Driver assistance computer (secondary): sw053 a10can bus off";
CM_ SG_ 1481 APS_sw053_a11bdyMIA "Driver assistance computer (secondary): sw053 a11bdy MIA";
CM_ SG_ 1481 APS_sw053_a12espMIA "Driver assistance computer (secondary): sw053 a12esp MIA";
CM_ SG_ 1481 APS_sw053_a13gtwMIA "Driver assistance computer (secondary): sw053 a13gtw MIA";
CM_ SG_ 1481 APS_sw053_a14sccmMIA "Driver assistance computer (secondary): sw053 a14sccm MIA";
CM_ SG_ 1481 APS_sw053_a15adasMIA "Driver assistance computer (secondary): sw053 a15adas MIA";
CM_ SG_ 1481 APS_sw053_a16bdyInvalidCount "Driver assistance computer (secondary): sw053 a16bdy invalid count";
CM_ SG_ 1481 APS_sw053_a17adasInvalidCount "Driver assistance computer (secondary): sw053 a17adas invalid count";
CM_ SG_ 1481 APS_sw053_a18espInvalidCount "Driver assistance computer (secondary): sw053 a18esp invalid count";
CM_ SG_ 1481 APS_sw053_a19sccmInvalidCount "Driver assistance computer (secondary): sw053 a19sccm invalid count";
CM_ SG_ 1481 APS_sw053_a20bdyInvalidChkSm "Driver assistance computer (secondary): sw053 a20bdy invalid chk sm";
CM_ SG_ 1481 APS_sw053_a21espInvalidChkSm "Driver assistance computer (secondary): sw053 a21esp invalid chk sm";
CM_ SG_ 1481 APS_sw053_a22sccmInvalidChkSm "Driver assistance computer (secondary): sw053 a22sccm invalid chk sm";
CM_ SG_ 1481 APS_sw053_a23sccmInvalidChkSm "Driver assistance computer (secondary): sw053 a23sccm invalid chk sm";
CM_ SG_ 1481 APS_sw053_a24absValidity "Driver assistance computer (secondary): sw053 a24abs validity";
CM_ SG_ 1481 APS_sw053_a25ambTValidity "Driver assistance computer (secondary): sw053 a25amb t validity";
CM_ SG_ 1481 APS_sw053_a26brakeValidity "Driver assistance computer (secondary): sw053 a26brake validity";
CM_ SG_ 1481 APS_sw053_a27CntryCdValidity "Driver assistance computer (secondary): sw053 a27 cntry cd validity";
CM_ SG_ 1481 APS_sw053_a28espValidity "Driver assistance computer (secondary): sw053 a28esp validity";
CM_ SG_ 1481 APS_sw053_a29longAccOffValidity "Driver assistance computer (secondary): sw053 a29long acc off validity";
CM_ SG_ 1481 APS_sw053_a30longAccValidity "Driver assistance computer (secondary): sw053 a30long acc validity";
CM_ SG_ 1481 APS_sw053_a31odoValidity "Driver assistance computer (secondary): sw053 a31odo validity";
CM_ SG_ 1481 APS_sw053_a32gearValidity "Driver assistance computer (secondary): sw053 a32gear validity";
CM_ SG_ 1481 APS_sw053_a33steerAngValidity "Driver assistance computer (secondary): sw053 a33steer ang validity";
CM_ SG_ 1481 APS_sw053_a34steerAngSpdValidity "Driver assistance computer (secondary): sw053 a34steer ang spd validity";
CM_ SG_ 1481 APS_sw053_a35indctrValidity "Driver assistance computer (secondary): sw053 a35indctr validity";
CM_ SG_ 1481 APS_sw053_a36vehStndStllValidty "Driver assistance computer (secondary): sw053 a36veh stnd stll validty";
CM_ SG_ 1481 APS_sw053_a37vinValidity "Driver assistance computer (secondary): sw053 a37vin validity";
CM_ SG_ 1481 APS_sw053_a38whlRotValidity "Driver assistance computer (secondary): sw053 a38whl rot validity";
CM_ SG_ 1481 APS_sw053_a39whlSpdValidity "Driver assistance computer (secondary): sw053 a39whl spd validity";
CM_ SG_ 1481 APS_sw053_a40whlStndStllValidty "Driver assistance computer (secondary): sw053 a40whl stnd stll validty";
CM_ SG_ 1481 APS_sw053_a41wiperValidity "Driver assistance computer (secondary): sw053 a41wiper validity";
CM_ SG_ 1481 APS_sw053_a42xwdValidity "Driver assistance computer (secondary): sw053 a42xwd validity";
CM_ SG_ 1481 APS_sw053_a43yawOffValidity "Driver assistance computer (secondary): sw053 a43yaw off validity";
CM_ SG_ 1481 APS_sw053_a44yawValidity "Driver assistance computer (secondary): sw053 a44yaw validity";
CM_ SG_ 1481 APS_sw053_a48steerAngOffSanity "Driver assistance computer (secondary): sw053 a48steer ang off sanity";
CM_ SG_ 1481 APS_sw053_a49tireSizeSanity "Driver assistance computer (secondary): sw053 a49tire size sanity";
CM_ SG_ 1481 APS_sw053_a50velocitySanity "Driver assistance computer (secondary): sw053 a50velocity sanity";
CM_ SG_ 1481 APS_sw053_a51yawSanity "Driver assistance computer (secondary): sw053 a51yaw sanity";
CM_ SG_ 1481 APS_sw053_a53espmodValidity "Driver assistance computer (secondary): sw053 a53espmod validity";
CM_ SG_ 1481 APS_sw053_a54gtwmodValidity "Driver assistance computer (secondary): sw053 a54gtwmod validity";
CM_ SG_ 1481 APS_sw053_a55stwmodValidity "Driver assistance computer (secondary): sw053 a55stwmod validity";
CM_ SG_ 1481 APS_sw053_a56bcmodValidity "Driver assistance computer (secondary): sw053 a56bcmod validity";
CM_ SG_ 1481 APS_sw053_a57dimodValidity "Driver assistance computer (secondary): sw053 a57dimod validity";
CM_ SG_ 1481 APS_sw053_a59drmiInvalidChkSm "Driver assistance computer (secondary): sw053 a59drmi invalid chk sm";
CM_ SG_ 1481 APS_sw053_a60drmiInvalidCount "Driver assistance computer (secondary): sw053 a60drmi invalid count";
CM_ SG_ 1481 APS_sw053_a61radPositionMismatch "Driver assistance computer (secondary): sw053 a61rad position mismatch";
CM_ SG_ 1481 APS_sw053_a62strRackMismatch "Driver assistance computer (secondary): sw053 a62str rack mismatch";
CM_ SG_ 1481 APS_sw055_detectedRadcVersion "Driver assistance computer (secondary): sw055 detected radc version";
CM_ SG_ 1481 APS_sw055_expectedCrcLsw "Driver assistance computer (secondary): sw055 expected crc lsw";
CM_ SG_ 1481 APS_sw056_diMia "Driver assistance computer (secondary): sw056 di mia";
CM_ SG_ 1481 APS_sw056_unusedByte "Driver assistance computer (secondary): sw056 unused byte";
CM_ SG_ 1481 APS_sw056_unusedW0 "Driver assistance computer (secondary): sw056 unused W0";
CM_ SG_ 1481 APS_sw056_unusedW1 "Driver assistance computer (secondary): sw056 unused W1";
CM_ SG_ 1481 APS_sw058_epbMia "Driver assistance computer (secondary): sw058 epb mia";
CM_ SG_ 1481 APS_sw058_unusedByte "Driver assistance computer (secondary): sw058 unused byte";
CM_ SG_ 1481 APS_sw058_unusedW0 "Driver assistance computer (secondary): sw058 unused W0";
CM_ SG_ 1481 APS_sw058_unusedW1 "Driver assistance computer (secondary): sw058 unused W1";
CM_ SG_ 1481 APS_sw059_sdiFront "Driver assistance computer (secondary): sw059 sdi front";
CM_ SG_ 1481 APS_sw059_sdiRear "Driver assistance computer (secondary): sw059 sdi rear";
CM_ SG_ 1481 APS_sw059_status "Driver assistance computer (secondary): sw059 status";
CM_ SG_ 1481 APS_sw059_sensorStatusFront "Driver assistance computer (secondary): sw059 sensor status front";
CM_ SG_ 1481 APS_sw059_pasFrontMiddle "Driver assistance computer (secondary): sw059 pas front middle";
CM_ SG_ 1481 APS_sw059_sensorStatusRear "Driver assistance computer (secondary): sw059 sensor status rear";
CM_ SG_ 1481 APS_sw059_pasRearMiddle "Driver assistance computer (secondary): sw059 pas rear middle";
CM_ SG_ 1481 APS_sw059_pscStatus "Driver assistance computer (secondary): sw059 psc status";
CM_ SG_ 1481 APS_sw059_pscVehSlot "Driver assistance computer (secondary): sw059 psc veh slot";
CM_ SG_ 1481 APS_sw059_status2 "Driver assistance computer (secondary): sw059 status2";
CM_ SG_ 1481 APS_sw059_oloDict "Driver assistance computer (secondary): sw059 olo dict";
CM_ SG_ 1481 APS_sw059_oocStatus "Driver assistance computer (secondary): sw059 ooc status";
CM_ SG_ 1481 APS_sw061_states "Driver assistance computer (secondary): sw061 states";
CM_ SG_ 1481 APS_sw063_expectedMajorVer "Driver assistance computer (secondary): sw063 expected major ver";
CM_ SG_ 1481 APS_sw063_detectedMajorVer "Driver assistance computer (secondary): sw063 detected major ver";
CM_ SG_ 1481 APS_sw063_expectedMinorVer "Driver assistance computer (secondary): sw063 expected minor ver";
CM_ SG_ 1481 APS_sw063_detectedMinorVer "Driver assistance computer (secondary): sw063 detected minor ver";
CM_ SG_ 1481 APS_sw063_expectedSubMinorVer "Driver assistance computer (secondary): sw063 expected sub minor ver";
CM_ SG_ 1481 APS_sw063_detectedSubMinorVer "Driver assistance computer (secondary): sw063 detected sub minor ver";
CM_ SG_ 1481 APS_sw064_sysStatus "Driver assistance computer (secondary): sw064 sys status";
CM_ SG_ 1481 APS_sw064_status "Driver assistance computer (secondary): sw064 status";
CM_ SG_ 1481 APS_sw070_currTireFitment "Driver assistance computer (secondary): sw070 curr tire fitment";
CM_ SG_ 1481 APS_sw070_lastTireFitment "Driver assistance computer (secondary): sw070 last tire fitment";
CM_ SG_ 1481 APS_sw070_diGear "Driver assistance computer (secondary): sw070 di gear";
CM_ SG_ 1481 APS_sw070_driveRail "Driver assistance computer (secondary): sw070 drive rail";
CM_ SG_ 1481 APS_sw070_accRail "Driver assistance computer (secondary): sw070 acc rail";
CM_ SG_ 1481 APS_sw070_temperature "Driver assistance computer (secondary): sw070 temperature";
CM_ SG_ 1481 APS_sw070_currentSpeed "Driver assistance computer (secondary): sw070 current speed";
CM_ SG_ 1481 APS_sw071_selfParkType "Driver assistance computer (secondary): sw071 self park type";
CM_ SG_ 1481 APS_sw071_endPosX "Driver assistance computer (secondary): sw071 end pos x";
CM_ SG_ 1481 APS_sw071_endPosY "Driver assistance computer (secondary): sw071 end pos y";
CM_ SG_ 1481 APS_sw071_roadClass "Driver assistance computer (secondary): sw071 road class";
CM_ SG_ 1481 APS_sw071_driverPresent "Driver assistance computer (secondary): sw071 driver present";
CM_ SG_ 1481 APS_sw071_airSuspension "Driver assistance computer (secondary): sw071 air suspension";
CM_ SG_ 1481 APS_sw071_temperature "Driver assistance computer (secondary): sw071 temperature";
CM_ SG_ 1481 APS_sw071_activationType "Driver assistance computer (secondary): sw071 activation type";
CM_ SG_ 1481 APS_sw072_vehicleX "Driver assistance computer (secondary): sw072 vehicle x";
CM_ SG_ 1481 APS_sw072_vehicleY "Driver assistance computer (secondary): sw072 vehicle y";
CM_ SG_ 1481 APS_sw072_vehicleHeading "Driver assistance computer (secondary): sw072 vehicle heading";
CM_ SG_ 1481 APS_sw072_endDistance "Driver assistance computer (secondary): sw072 end distance";
CM_ SG_ 1481 APS_sw072_guidanceComplete "Driver assistance computer (secondary): sw072 guidance complete";
CM_ SG_ 1481 APS_sw072_guidanceRunaway "Driver assistance computer (secondary): sw072 guidance runaway";
CM_ SG_ 1481 APS_sw072_guidanceTimer "Driver assistance computer (secondary): sw072 guidance timer";
CM_ SG_ 1481 APS_sw072_handlePress "Driver assistance computer (secondary): sw072 handle press";
CM_ SG_ 1481 APS_sw072_keyfobPress "Driver assistance computer (secondary): sw072 keyfob press";
CM_ SG_ 1481 APS_sw072_garageOpened "Driver assistance computer (secondary): sw072 garage opened";
CM_ SG_ 1481 APS_sw072_userTimeout "Driver assistance computer (secondary): sw072 user timeout";
CM_ SG_ 1481 APS_sw075_scMia "Driver assistance computer (secondary): sw075 sc mia";
CM_ SG_ 1481 APS_sw075_unusedByte "Driver assistance computer (secondary): sw075 unused byte";
CM_ SG_ 1481 APS_sw075_unusedW0 "Driver assistance computer (secondary): sw075 unused W0";
CM_ SG_ 1481 APS_sw075_unusedW1 "Driver assistance computer (secondary): sw075 unused W1";
CM_ SG_ 1481 APS_sw077_oocDistance "Driver assistance computer (secondary): sw077 ooc distance";
CM_ SG_ 1481 APS_sw077_oocConfidence "Driver assistance computer (secondary): sw077 ooc confidence";
CM_ SG_ 1481 APS_sw077_oocCollisionSide "Driver assistance computer (secondary): sw077 ooc collision side";
CM_ SG_ 1481 APS_sw077_oocHeight "Driver assistance computer (secondary): sw077 ooc height";
CM_ SG_ 1481 APS_sw077_vehicleSpeed "Driver assistance computer (secondary): sw077 vehicle speed";
CM_ SG_ 1481 APS_sw077_oocUntrackedTime "Driver assistance computer (secondary): sw077 ooc untracked time";
CM_ SG_ 1481 APS_sw077_oocOffCourseDist_cm "Driver assistance computer (secondary): sw077 ooc off course dist cm";
CM_ SG_ 1481 APS_sw081_radarDistance "Driver assistance computer (secondary): sw081 radar distance";
CM_ SG_ 1481 APS_sw081_radarTTC "Driver assistance computer (secondary): sw081 radar TTC";
CM_ SG_ 1481 APS_sw081_cameraDistance "Driver assistance computer (secondary): sw081 camera distance";
CM_ SG_ 1481 APS_sw081_cameraTTC "Driver assistance computer (secondary): sw081 camera TTC";
CM_ SG_ 1481 APS_sw081_pedalPosition "Driver assistance computer (secondary): sw081 pedal position";
CM_ SG_ 1481 APS_sw129_currentVoltage "Driver assistance computer (secondary): sw129 current voltage";
CM_ SG_ 1481 APS_sw129_maxThreshold "Driver assistance computer (secondary): sw129 max threshold";
CM_ SG_ 1481 APS_sw129_minThreshold "Driver assistance computer (secondary): sw129 min threshold";
CM_ SG_ 1481 APS_sw129_powerSequnceError "Driver assistance computer (secondary): sw129 power sequnce error";
CM_ SG_ 1481 APS_sw129_railControl "Driver assistance computer (secondary): sw129 rail control";
CM_ SG_ 1481 APS_sw129_railID "Driver assistance computer (secondary): sw129 rail ID";
CM_ SG_ 1481 APS_sw130_currentTemperature "Driver assistance computer (secondary): sw130 current temperature";
CM_ SG_ 1481 APS_sw130_maxThreshold "Driver assistance computer (secondary): sw130 max threshold";
CM_ SG_ 1481 APS_sw130_minThreshold "Driver assistance computer (secondary): sw130 min threshold";
CM_ SG_ 1481 APS_sw130_tempSensorId "Driver assistance computer (secondary): sw130 temp sensor id";
CM_ SG_ 1481 APS_sw130_shouldForceApPowerOn "Driver assistance computer (secondary): sw130 should force ap power on";
CM_ SG_ 1481 APS_sw130_shouldBlockOkToPowerAp "Driver assistance computer (secondary): sw130 should block ok to power ap";
CM_ SG_ 1481 APS_sw132_mismatchType "Driver assistance computer (secondary): sw132 mismatch type";
CM_ SG_ 1481 APS_sw132_actualHash "Driver assistance computer (secondary): sw132 actual hash";
CM_ SG_ 1481 APS_sw132_expectedHash "Driver assistance computer (secondary): sw132 expected hash";
CM_ SG_ 1481 APS_sw133_failedInitStep "Driver assistance computer (secondary): sw133 failed init step";
CM_ SG_ 1481 APS_sw133_switchInReset "Driver assistance computer (secondary): sw133 switch in reset";
CM_ SG_ 1481 APS_sw133_phyIsNotRMIIMode "Driver assistance computer (secondary): sw133 phy is not RMII mode";
CM_ SG_ 1481 APS_sw133_phyInterruptStorm "Driver assistance computer (secondary): sw133 phy interrupt storm";
CM_ SG_ 1481 APS_sw133_switchEthernetInterLin "Driver assistance computer (secondary): sw133 switch ethernet inter link down";
CM_ SG_ 1481 APS_sw133_ethSwitchReadFwVerFail "Driver assistance computer (secondary): sw133 eth switch read fw ver failed";
CM_ SG_ 1481 APS_sw133_ethSwitchFailedToBoot "Driver assistance computer (secondary): sw133 eth switch failed to boot";
CM_ SG_ 1481 APS_sw133_ethSwitchTimedoutUpdat "Driver assistance computer (secondary): sw133 eth switch timedout update";
CM_ SG_ 1481 APS_sw133_ethSwitchMcuLinkFailov "Driver assistance computer (secondary): sw133 eth switch mcu link failover";
CM_ SG_ 1481 APS_sw133_ethSwitchMcuLinkDuplic "Driver assistance computer (secondary): sw133 eth switch mcu link duplicated";
CM_ SG_ 1481 APS_sw133_ethSwitchMcuLinkDiscon "Driver assistance computer (secondary): sw133 eth switch mcu link disconnected";
CM_ SG_ 1481 APS_sw133_unused "Driver assistance computer (secondary): sw133 unused";
CM_ SG_ 1481 APS_sw134_appCamCalibStatus "Driver assistance computer (secondary): sw134 app cam calib status";
CM_ SG_ 1481 APS_sw134_appCameraLux "Driver assistance computer (secondary): sw134 app camera lux";
CM_ SG_ 1481 APS_sw134_appInfo "Driver assistance computer (secondary): sw134 app info";
CM_ SG_ 1481 APS_sw134_appStatus "Driver assistance computer (secondary): sw134 app status";
CM_ SG_ 1481 APS_sw134_dasAutonomyControlPart "Driver assistance computer (secondary): sw134 das autonomy control party";
CM_ SG_ 1481 APS_sw134_dasAutonomyControlVeh "Driver assistance computer (secondary): sw134 das autonomy control veh";
CM_ SG_ 1481 APS_sw134_dasBodyControlsVEH "Driver assistance computer (secondary): sw134 das body controls VEH";
CM_ SG_ 1481 APS_sw134_dasControl "Driver assistance computer (secondary): sw134 das control";
CM_ SG_ 1481 APS_sw134_dasControlPty "Driver assistance computer (secondary): sw134 das control pty";
CM_ SG_ 1481 APS_sw134_dasIntSafetyFrontPty "Driver assistance computer (secondary): sw134 das int safety front pty";
CM_ SG_ 1481 APS_sw134_dasLanes "Driver assistance computer (secondary): sw134 das lanes";
CM_ SG_ 1481 APS_sw134_dasObject "Driver assistance computer (secondary): sw134 das object";
CM_ SG_ 1481 APS_sw134_dasPscControl "Driver assistance computer (secondary): sw134 das psc control";
CM_ SG_ 1481 APS_sw134_dasStatus "Driver assistance computer (secondary): sw134 das status";
CM_ SG_ 1481 APS_sw134_dasStatus2 "Driver assistance computer (secondary): sw134 das status2";
CM_ SG_ 1481 APS_sw134_dasSteeringControl "Driver assistance computer (secondary): sw134 das steering control";
CM_ SG_ 1481 APS_sw134_dasVisualDebug "Driver assistance computer (secondary): sw134 das visual debug";
CM_ SG_ 1481 APS_sw134_dasSteeringControlPty "Driver assistance computer (secondary): sw134 das steering control pty";
CM_ SG_ 1481 APS_sw134_dasChNm "Driver assistance computer (secondary): sw134 das ch nm";
CM_ SG_ 1481 APS_sw134_appSummon "Driver assistance computer (secondary): sw134 app summon";
CM_ SG_ 1481 APS_sw134_appEnvironment "Driver assistance computer (secondary): sw134 app environment";
CM_ SG_ 1481 APS_sw134_dasStatusPty "Driver assistance computer (secondary): sw134 das status pty";
CM_ SG_ 1481 APS_sw134_dasStatus2Pty "Driver assistance computer (secondary): sw134 das status2 pty";
CM_ SG_ 1481 APS_sw134_dasMatrixHighBeamRqVEH "Driver assistance computer (secondary): sw134 das matrix high beam rq VEH";
CM_ SG_ 1481 APS_sw134_dasMatrixBendAngleRqPt "Driver assistance computer (secondary): sw134 das matrix bend angle rq pty";
CM_ SG_ 1481 APS_sw134_dasBodyControls2VEH "Driver assistance computer (secondary): sw134 das body controls2 VEH";
CM_ SG_ 1481 APS_sw134_dasRedundantBrakingCon "Driver assistance computer (secondary): sw134 das redundant braking control";
CM_ SG_ 1481 APS_sw134_dasRedundantBraki_0001 "Driver assistance computer (secondary): sw134 das redundant braking control pty";
CM_ SG_ 1481 APS_sw134_timeSinceLastMsg "Driver assistance computer (secondary): sw134 time since last msg";
CM_ SG_ 1481 APS_sw135_appCriticalReason "Driver assistance computer (secondary): sw135 app critical reason";
CM_ SG_ 1481 APS_sw135_appTimesyncStatus "Driver assistance computer (secondary): sw135 app timesync status";
CM_ SG_ 1481 APS_sw136_gpsCommIrrecoverable "Driver assistance computer (secondary): sw136 gps comm irrecoverable";
CM_ SG_ 1481 APS_sw136_fusionIrrecoverable "Driver assistance computer (secondary): sw136 fusion irrecoverable";
CM_ SG_ 1481 APS_sw136_antennaUnplugged "Driver assistance computer (secondary): sw136 antenna unplugged";
CM_ SG_ 1481 APS_sw136_badgpsfix "Driver assistance computer (secondary): sw136 badgpsfix";
CM_ SG_ 1481 APS_sw137_gpsCommMissing "Driver assistance computer (secondary): sw137 gps comm missing";
CM_ SG_ 1481 APS_sw137_gpsJunkData "Driver assistance computer (secondary): sw137 gps junk data";
CM_ SG_ 1481 APS_sw137_gpsNMEAmissing "Driver assistance computer (secondary): sw137 gps NME amissing";
CM_ SG_ 1481 APS_sw137_gpsUBXmissing "Driver assistance computer (secondary): sw137 gps UB xmissing";
CM_ SG_ 1481 APS_sw137_fusionModeDisabled "Driver assistance computer (secondary): sw137 fusion mode disabled";
CM_ SG_ 1481 APS_sw137_gpsCfgFail "Driver assistance computer (secondary): sw137 gps cfg fail";
CM_ SG_ 1481 APS_sw137_esfStatusMsgMIA "Driver assistance computer (secondary): sw137 esf status msg MIA";
CM_ SG_ 1481 APS_sw137_wheelTickCfgMissmatch "Driver assistance computer (secondary): sw137 wheel tick cfg missmatch";
CM_ SG_ 1481 APS_sw137_exitTransportMode "Driver assistance computer (secondary): sw137 exit transport mode";
CM_ SG_ 1481 APS_sw137_satRejectionTimeout "Driver assistance computer (secondary): sw137 sat rejection timeout";
CM_ SG_ 1481 APS_sw137_gpsPPSMissing "Driver assistance computer (secondary): sw137 gps PPS missing";
CM_ SG_ 1481 APS_sw138_cfgBufNull "Driver assistance computer (secondary): sw138 cfg buf null";
CM_ SG_ 1481 APS_sw138_invalidID "Driver assistance computer (secondary): sw138 invalid ID";
CM_ SG_ 1481 APS_sw138_gpsBufferOverflow "Driver assistance computer (secondary): sw138 gps buffer overflow";
CM_ SG_ 1481 APS_sw138_navx5CfgFailed "Driver assistance computer (secondary): sw138 navx5 cfg failed";
CM_ SG_ 1481 APS_sw138_mcuNMEAmsgUDPinvalid "Driver assistance computer (secondary): sw138 mcu NME amsg UD pinvalid";
CM_ SG_ 1481 APS_sw138_mcuDbgMsgInvalid "Driver assistance computer (secondary): sw138 mcu dbg msg invalid";
CM_ SG_ 1481 APS_sw138_mcuDbgMsgTooBig "Driver assistance computer (secondary): sw138 mcu dbg msg too big";
CM_ SG_ 1481 APS_sw138_mcuFwdNMEAfail "Driver assistance computer (secondary): sw138 mcu fwd NME afail";
CM_ SG_ 1481 APS_sw138_NMEAinvalidChecksum "Driver assistance computer (secondary): sw138 NME ainvalid checksum";
CM_ SG_ 1481 APS_sw138_unexpectedNMEAmsg "Driver assistance computer (secondary): sw138 unexpected NME amsg";
CM_ SG_ 1481 APS_sw138_UARTbusFull "Driver assistance computer (secondary): sw138 UAR tbus full";
CM_ SG_ 1481 APS_sw138_UARTframeError "Driver assistance computer (secondary): sw138 UAR tframe error";
CM_ SG_ 1481 APS_sw138_UBXrxFrameTooBig "Driver assistance computer (secondary): sw138 UB xrx frame too big";
CM_ SG_ 1481 APS_sw138_emptyValidNMEA "Driver assistance computer (secondary): sw138 empty valid NMEA";
CM_ SG_ 1481 APS_sw138_invalidAsciiNMEA "Driver assistance computer (secondary): sw138 invalid ascii NMEA";
CM_ SG_ 1481 APS_sw138_wheeltickUARTfault "Driver assistance computer (secondary): sw138 wheeltick UAR tfault";
CM_ SG_ 1481 APS_sw138_baudrateMismatch "Driver assistance computer (secondary): sw138 baudrate mismatch";
CM_ SG_ 1481 APS_sw138_wheelTickInvalidSrc "Driver assistance computer (secondary): sw138 wheel tick invalid src";
CM_ SG_ 1481 APS_sw138_UARTparityError "Driver assistance computer (secondary): sw138 UAR tparity error";
CM_ SG_ 1481 APS_sw138_UARTrxFifoOverflow "Driver assistance computer (secondary): sw138 UAR trx fifo overflow";
CM_ SG_ 1481 APS_sw138_UARTrxFifoUnderflow "Driver assistance computer (secondary): sw138 UAR trx fifo underflow";
CM_ SG_ 1481 APS_sw138_UARTtxFifoOverflow "Driver assistance computer (secondary): sw138 UAR ttx fifo overflow";
CM_ SG_ 1481 APS_sw138_esfWtMsgTimeout "Driver assistance computer (secondary): sw138 esf wt msg timeout";
CM_ SG_ 1481 APS_sw138_PFLASHReadError "Driver assistance computer (secondary): sw138 PFLASH read error";
CM_ SG_ 1481 APS_sw138_PFLASHWriteError "Driver assistance computer (secondary): sw138 PFLASH write error";
CM_ SG_ 1481 APS_sw138_gpsCfgNack "Driver assistance computer (secondary): sw138 gps cfg nack";
CM_ SG_ 1481 APS_sw138_gpsCfgIdFail "Driver assistance computer (secondary): sw138 gps cfg id fail";
CM_ SG_ 1481 APS_sw138_gpsSetCfgNoAck "Driver assistance computer (secondary): sw138 gps set cfg no ack";
CM_ SG_ 1481 APS_sw138_gpsReadCfgNoResponse "Driver assistance computer (secondary): sw138 gps read cfg no response";
CM_ SG_ 1481 APS_sw138_ubxErrorReported "Driver assistance computer (secondary): sw138 ubx error reported";
CM_ SG_ 1481 APS_sw140_lvPowerState "Driver assistance computer (secondary): sw140 lv power state";
CM_ SG_ 1481 APS_sw140_vehicleStatus "Driver assistance computer (secondary): sw140 vehicle status";
CM_ SG_ 1481 APS_sw140_status "Driver assistance computer (secondary): sw140 status";
CM_ SG_ 1481 APS_sw140_lighting "Driver assistance computer (secondary): sw140 lighting";
CM_ SG_ 1481 APS_sw140_sensors "Driver assistance computer (secondary): sw140 sensors";
CM_ SG_ 1481 APS_sw140_coolant "Driver assistance computer (secondary): sw140 coolant";
CM_ SG_ 1481 APS_sw140_okToUseHighPower "Driver assistance computer (secondary): sw140 ok to use high power";
CM_ SG_ 1481 APS_sw141_inertial1 "Driver assistance computer (secondary): sw141 inertial1";
CM_ SG_ 1481 APS_sw141_inertial2 "Driver assistance computer (secondary): sw141 inertial2";
CM_ SG_ 1481 APS_sw142_speed "Driver assistance computer (secondary): sw142 speed";
CM_ SG_ 1481 APS_sw142_locStatus "Driver assistance computer (secondary): sw142 loc status";
CM_ SG_ 1481 APS_sw142_locStatus2 "Driver assistance computer (secondary): sw142 loc status2";
CM_ SG_ 1481 APS_sw142_systemStatus "Driver assistance computer (secondary): sw142 system status";
CM_ SG_ 1481 APS_sw142_chassisControl "Driver assistance computer (secondary): sw142 chassis control";
CM_ SG_ 1481 APS_sw142_epbStatus "Driver assistance computer (secondary): sw142 epb status";
CM_ SG_ 1481 APS_sw142_brakeSystem "Driver assistance computer (secondary): sw142 brake system";
CM_ SG_ 1481 APS_sw143_status "Driver assistance computer (secondary): sw143 status";
CM_ SG_ 1481 APS_sw143_wheelRotation "Driver assistance computer (secondary): sw143 wheel rotation";
CM_ SG_ 1481 APS_sw143_wheelSpeeds "Driver assistance computer (secondary): sw143 wheel speeds";
CM_ SG_ 1481 APS_sw143_redundantBrakingStatus "Driver assistance computer (secondary): sw143 redundant braking status";
CM_ SG_ 1481 APS_sw144_restraintStatus "Driver assistance computer (secondary): sw144 restraint status";
CM_ SG_ 1481 APS_sw145_restraintStatus "Driver assistance computer (secondary): sw145 restraint status";
CM_ SG_ 1481 APS_sw146_sysStatus "Driver assistance computer (secondary): sw146 sys status";
CM_ SG_ 1481 APS_sw146_status "Driver assistance computer (secondary): sw146 status";
CM_ SG_ 1481 APS_sw147_doorStatus "Driver assistance computer (secondary): sw147 door status";
CM_ SG_ 1481 APS_sw147_switchStatus "Driver assistance computer (secondary): sw147 switch status";
CM_ SG_ 1481 APS_sw148_doorStatus "Driver assistance computer (secondary): sw148 door status";
CM_ SG_ 1481 APS_sw148_hvacStatus "Driver assistance computer (secondary): sw148 hvac status";
CM_ SG_ 1481 APS_sw149_status "Driver assistance computer (secondary): sw149 status";
CM_ SG_ 1481 APS_sw150_steeringAngleSensor "Driver assistance computer (secondary): sw150 steering angle sensor";
CM_ SG_ 1481 APS_sw150_rightStalk "Driver assistance computer (secondary): sw150 right stalk";
CM_ SG_ 1481 APS_sw150_leftStalk "Driver assistance computer (secondary): sw150 left stalk";
CM_ SG_ 1481 APS_sw153_eacInhibitReason "Driver assistance computer (secondary): sw153 eac inhibit reason";
CM_ SG_ 1481 APS_sw153_eacInternalState "Driver assistance computer (secondary): sw153 eac internal state";
CM_ SG_ 1481 APS_sw155_InUnicastError "Driver assistance computer (secondary): sw155 in unicast error";
CM_ SG_ 1481 APS_sw155_UDPRecvError "Driver assistance computer (secondary): sw155 UDP recv error";
CM_ SG_ 1481 APS_sw155_UDPMiscError "Driver assistance computer (secondary): sw155 UDP misc error";
CM_ SG_ 1481 APS_sw155_UDPRTEError "Driver assistance computer (secondary): sw155 UDPRTE error";
CM_ SG_ 1481 APS_sw155_UDPCheckError "Driver assistance computer (secondary): sw155 UDP check error";
CM_ SG_ 1481 APS_sw155_UDPDropError "Driver assistance computer (secondary): sw155 UDP drop error";
CM_ SG_ 1481 APS_sw155_UDPMemError "Driver assistance computer (secondary): sw155 UDP mem error";
CM_ SG_ 1481 APS_sw155_UDPProtoError "Driver assistance computer (secondary): sw155 UDP proto error";
CM_ SG_ 1481 APS_sw155_IPRecvError "Driver assistance computer (secondary): sw155 IP recv error";
CM_ SG_ 1481 APS_sw155_IPMiscError "Driver assistance computer (secondary): sw155 IP misc error";
CM_ SG_ 1481 APS_sw155_IPRTEError "Driver assistance computer (secondary): sw155 IPRTE error";
CM_ SG_ 1481 APS_sw155_IPCheckError "Driver assistance computer (secondary): sw155 IP check error";
CM_ SG_ 1481 APS_sw155_IPMemError "Driver assistance computer (secondary): sw155 IP mem error";
CM_ SG_ 1481 APS_sw155_IPDropError "Driver assistance computer (secondary): sw155 IP drop error";
CM_ SG_ 1481 APS_sw155_IPProtoError "Driver assistance computer (secondary): sw155 IP proto error";
CM_ SG_ 1481 APS_sw158_apbInfo "Driver assistance computer (secondary): sw158 apb info";
CM_ SG_ 1481 APS_sw158_apbStatus "Driver assistance computer (secondary): sw158 apb status";
CM_ SG_ 1481 APS_sw158_dasAutonomyControlPart "Driver assistance computer (secondary): sw158 das autonomy control party";
CM_ SG_ 1481 APS_sw158_dasAutonomyControlVeh "Driver assistance computer (secondary): sw158 das autonomy control veh";
CM_ SG_ 1481 APS_sw158_dasBodyControlsVEH "Driver assistance computer (secondary): sw158 das body controls VEH";
CM_ SG_ 1481 APS_sw158_dasControl "Driver assistance computer (secondary): sw158 das control";
CM_ SG_ 1481 APS_sw158_dasControlPty "Driver assistance computer (secondary): sw158 das control pty";
CM_ SG_ 1481 APS_sw158_dasIntSafetyFrontPty "Driver assistance computer (secondary): sw158 das int safety front pty";
CM_ SG_ 1481 APS_sw158_dasLanes "Driver assistance computer (secondary): sw158 das lanes";
CM_ SG_ 1481 APS_sw158_dasObject "Driver assistance computer (secondary): sw158 das object";
CM_ SG_ 1481 APS_sw158_dasPscControl "Driver assistance computer (secondary): sw158 das psc control";
CM_ SG_ 1481 APS_sw158_dasStatus "Driver assistance computer (secondary): sw158 das status";
CM_ SG_ 1481 APS_sw158_dasStatus2 "Driver assistance computer (secondary): sw158 das status2";
CM_ SG_ 1481 APS_sw158_dasSteeringControl "Driver assistance computer (secondary): sw158 das steering control";
CM_ SG_ 1481 APS_sw158_dasVisualDebug "Driver assistance computer (secondary): sw158 das visual debug";
CM_ SG_ 1481 APS_sw158_dasSteeringControlPty "Driver assistance computer (secondary): sw158 das steering control pty";
CM_ SG_ 1481 APS_sw158_dasChNm "Driver assistance computer (secondary): sw158 das ch nm";
CM_ SG_ 1481 APS_sw158_dasStatusPty "Driver assistance computer (secondary): sw158 das status pty";
CM_ SG_ 1481 APS_sw158_dasStatus2Pty "Driver assistance computer (secondary): sw158 das status2 pty";
CM_ SG_ 1481 APS_sw158_dasMatrixHighBeamRqVEH "Driver assistance computer (secondary): sw158 das matrix high beam rq VEH";
CM_ SG_ 1481 APS_sw158_dasMatrixBendAngleRqPt "Driver assistance computer (secondary): sw158 das matrix bend angle rq pty";
CM_ SG_ 1481 APS_sw158_dasBodyControls2VEH "Driver assistance computer (secondary): sw158 das body controls2 VEH";
CM_ SG_ 1481 APS_sw158_dasRedundantBrakingCon "Driver assistance computer (secondary): sw158 das redundant braking control";
CM_ SG_ 1481 APS_sw158_dasRedundantBraki_0001 "Driver assistance computer (secondary): sw158 das redundant braking control pty";
CM_ SG_ 1481 APS_sw158_timeSinceLastMsg "Driver assistance computer (secondary): sw158 time since last msg";
CM_ SG_ 1481 APS_sw159_apbCriticalReason "Driver assistance computer (secondary): sw159 apb critical reason";
CM_ SG_ 1481 APS_sw159_apbTimesyncStatus "Driver assistance computer (secondary): sw159 apb timesync status";
CM_ SG_ 1481 APS_sw160_mismatchType "Driver assistance computer (secondary): sw160 mismatch type";
CM_ SG_ 1481 APS_sw160_actualHash "Driver assistance computer (secondary): sw160 actual hash";
CM_ SG_ 1481 APS_sw160_expectedHash "Driver assistance computer (secondary): sw160 expected hash";
CM_ SG_ 1481 APS_sw161_antennaDisconnected "Driver assistance computer (secondary): sw161 antenna disconnected";
CM_ SG_ 1481 APS_sw172_prolongedUiMia "Driver assistance computer (secondary): sw172 prolonged ui mia";
CM_ SG_ 1481 APS_sw172_uiMiaAtBootup "Driver assistance computer (secondary): sw172 ui mia at bootup";
CM_ SG_ 1481 APS_sw188_otherTurbo "Driver assistance computer (secondary): sw188 other turbo";
CM_ SG_ 1481 APS_sw188_arbUartMiaState "Driver assistance computer (secondary): sw188 arb uart mia state";
CM_ SG_ 1481 APS_sw188_powerUartMiaState "Driver assistance computer (secondary): sw188 power uart mia state";
CM_ SG_ 1481 APS_sw188_faultsUartMiaState "Driver assistance computer (secondary): sw188 faults uart mia state";
CM_ SG_ 1481 APS_sw188_sleepUartMiaState "Driver assistance computer (secondary): sw188 sleep uart mia state";
CM_ SG_ 1481 APS_sw188_resetUartMiaState "Driver assistance computer (secondary): sw188 reset uart mia state";
CM_ SG_ 1481 APS_sw188_statMonUartMiaState "Driver assistance computer (secondary): sw188 stat mon uart mia state";
CM_ SG_ 1481 APS_sw188_wdogStateUartMiaState "Driver assistance computer (secondary): sw188 wdog state uart mia state";
CM_ SG_ 1481 APS_sw188_critReasUartMiaState "Driver assistance computer (secondary): sw188 crit reas uart mia state";
CM_ SG_ 1481 APS_sw189_AP_vehicleState10Hz "Driver assistance computer (secondary): sw189 AP vehicle state10 hz";
CM_ SG_ 1481 APS_sw189_AP_vehicleState1Hz "Driver assistance computer (secondary): sw189 AP vehicle state1 hz";
CM_ SG_ 1481 APS_sw190_IBST_status "Driver assistance computer (secondary): sw190 IBST status";
CM_ SG_ 1481 APS_sw192_CANbus "Driver assistance computer (secondary): sw192 CA nbus";
CM_ SG_ 1481 APS_sw192_SWTxQueueFull "Driver assistance computer (secondary): sw192 SW tx queue full";
CM_ SG_ 1481 APS_sw192_Busoff "Driver assistance computer (secondary): sw192 busoff";
CM_ SG_ 1481 APS_sw192_UncorrectedBitError "Driver assistance computer (secondary): sw192 uncorrected bit error";
CM_ SG_ 1481 APS_sw192_CorrectedBitError "Driver assistance computer (secondary): sw192 corrected bit error";
CM_ SG_ 1481 APS_sw192_ErrorPassive "Driver assistance computer (secondary): sw192 error passive";
CM_ SG_ 1481 APS_sw192_RamAccessFailed "Driver assistance computer (secondary): sw192 ram access failed";
CM_ SG_ 1481 APS_sw192_RxMsgLost "Driver assistance computer (secondary): sw192 rx msg lost";
CM_ SG_ 1481 APS_sw192_msgIo "Driver assistance computer (secondary): sw192 msg io";
CM_ SG_ 1481 APS_sw192_queueFailure "Driver assistance computer (secondary): sw192 queue failure";
CM_ SG_ 1481 APS_sw192_msgId "Driver assistance computer (secondary): sw192 msg id";
CM_ SG_ 1481 APS_sw199_abortCodeDas "Driver assistance computer (secondary): sw199 abort code das";
CM_ SG_ 1481 APS_sw199_abortCodePARK "Driver assistance computer (secondary): sw199 abort code PARK";
CM_ SG_ 1481 APS_sw199_currentSTW "Driver assistance computer (secondary): sw199 current STW";
CM_ SG_ 1481 APS_sw199_currentSpeed "Driver assistance computer (secondary): sw199 current speed";
CM_ SG_ 1481 APS_sw199_internalState "Driver assistance computer (secondary): sw199 internal state";
CM_ SG_ 1481 APS_sw199_maxSpeed "Driver assistance computer (secondary): sw199 max speed";
CM_ SG_ 1481 APS_sw199_numShifts "Driver assistance computer (secondary): sw199 num shifts";
CM_ SG_ 1481 APS_sw203_controlType "Driver assistance computer (secondary): sw203 control type";
CM_ SG_ 1481 APS_sw203_curbType "Driver assistance computer (secondary): sw203 curb type";
CM_ SG_ 1481 APS_sw203_roadClass "Driver assistance computer (secondary): sw203 road class";
CM_ SG_ 1481 APS_sw203_slotSizeX "Driver assistance computer (secondary): sw203 slot size x";
CM_ SG_ 1481 APS_sw203_slotSizeY "Driver assistance computer (secondary): sw203 slot size y";
CM_ SG_ 1481 APS_sw203_startDistance "Driver assistance computer (secondary): sw203 start distance";
CM_ SG_ 1481 APS_sw203_vehicleSkew "Driver assistance computer (secondary): sw203 vehicle skew";
CM_ SG_ 1481 APS_sw204_frLeft "Driver assistance computer (secondary): sw204 fr left";
CM_ SG_ 1481 APS_sw204_frLeftMiddle "Driver assistance computer (secondary): sw204 fr left middle";
CM_ SG_ 1481 APS_sw204_frMiddle "Driver assistance computer (secondary): sw204 fr middle";
CM_ SG_ 1481 APS_sw204_frRight "Driver assistance computer (secondary): sw204 fr right";
CM_ SG_ 1481 APS_sw204_frRightMiddle "Driver assistance computer (secondary): sw204 fr right middle";
CM_ SG_ 1481 APS_sw204_maxSpeed "Driver assistance computer (secondary): sw204 max speed";
CM_ SG_ 1481 APS_sw205_oocDistance "Driver assistance computer (secondary): sw205 ooc distance";
CM_ SG_ 1481 APS_sw205_rrLeft "Driver assistance computer (secondary): sw205 rr left";
CM_ SG_ 1481 APS_sw205_rrLeftMiddle "Driver assistance computer (secondary): sw205 rr left middle";
CM_ SG_ 1481 APS_sw205_rrMiddle "Driver assistance computer (secondary): sw205 rr middle";
CM_ SG_ 1481 APS_sw205_rrRight "Driver assistance computer (secondary): sw205 rr right";
CM_ SG_ 1481 APS_sw205_rrRightMiddle "Driver assistance computer (secondary): sw205 rr right middle";
CM_ SG_ 1481 APS_sw235_resetOrigin "Driver assistance computer (secondary): sw235 reset origin";
CM_ SG_ 1481 APS_sw235_generalUnrecoverable "Driver assistance computer (secondary): sw235 general unrecoverable";
CM_ SG_ 1481 APS_sw235_pgoodUnrecoverable "Driver assistance computer (secondary): sw235 pgood unrecoverable";
CM_ SG_ 1481 APS_sw235_faultUnrecoverable "Driver assistance computer (secondary): sw235 fault unrecoverable";
CM_ SG_ 1481 APS_sw235_12VFuseUnrecoverable "Driver assistance computer (secondary): sw235 12 v fuse unrecoverable";
CM_ SG_ 1481 APS_sw235_pgoodLevelUnrcvrble "Driver assistance computer (secondary): sw235 pgood level unrcvrble";
CM_ SG_ 1481 APS_sw235_faultLevelUnrcvrble "Driver assistance computer (secondary): sw235 fault level unrcvrble";
CM_ SG_ 1481 APS_sw235_12VFuseLvlUnrcvrble "Driver assistance computer (secondary): sw235 12 v fuse lvl unrcvrble";
CM_ SG_ 1481 APS_sw235_localSoftwareFault "Driver assistance computer (secondary): sw235 local software fault";
CM_ SG_ 1481 APS_sw235_unrecoverableFailReset "Driver assistance computer (secondary): sw235 unrecoverable fail reset";
CM_ SG_ 1481 APS_sw235_generalGic "Driver assistance computer (secondary): sw235 general gic";
CM_ SG_ 1481 APS_sw235_a72WdtTimeout "Driver assistance computer (secondary): sw235 a72 wdt timeout";
CM_ SG_ 1481 APS_sw235_generalScs "Driver assistance computer (secondary): sw235 general scs";
CM_ SG_ 1481 APS_sw235_generalUnexpected "Driver assistance computer (secondary): sw235 general unexpected";
CM_ SG_ 1481 APS_sw235_canUncorrectedBitError "Driver assistance computer (secondary): sw235 can uncorrected bit error";
CM_ SG_ 1481 APS_sw235_canExitBusoffFailed "Driver assistance computer (secondary): sw235 can exit busoff failed";
CM_ SG_ 1481 APS_sw235_txEnFdbckNotExpected "Driver assistance computer (secondary): sw235 tx en fdbck not expected";
CM_ SG_ 1481 APS_sw235_nocSmsFailed "Driver assistance computer (secondary): sw235 noc sms failed";
CM_ SG_ 1481 APS_sw235_nocCamFailed "Driver assistance computer (secondary): sw235 noc cam failed";
CM_ SG_ 1481 APS_sw235_nocCoreFailed "Driver assistance computer (secondary): sw235 noc core failed";
CM_ SG_ 1481 APS_sw235_nocScsFailed "Driver assistance computer (secondary): sw235 noc scs failed";
CM_ SG_ 1481 APS_sw235_model3UiReset "Driver assistance computer (secondary): sw235 model3 ui reset";
CM_ SG_ 1481 APS_sw235_modelsUiReset "Driver assistance computer (secondary): sw235 models ui reset";
CM_ SG_ 1481 APS_sw235_pmicApOnPrpUnrcvrble "Driver assistance computer (secondary): sw235 pmic ap on prp unrcvrble";
CM_ SG_ 1481 APS_sw235_apOnReadyTimeout "Driver assistance computer (secondary): sw235 ap on ready timeout";
CM_ SG_ 1481 APS_sw235_pmicApOnWaitUnrcvrble "Driver assistance computer (secondary): sw235 pmic ap on wait unrcvrble";
CM_ SG_ 1481 APS_sw235_apBootingTimeout "Driver assistance computer (secondary): sw235 ap booting timeout";
CM_ SG_ 1481 APS_sw235_pmicApOffWaitUnrcvrble "Driver assistance computer (secondary): sw235 pmic ap off wait unrcvrble";
CM_ SG_ 1481 APS_sw235_resetBeingSent "Driver assistance computer (secondary): sw235 reset being sent";
CM_ SG_ 1481 APS_sw235_udsResetBeingSent "Driver assistance computer (secondary): sw235 uds reset being sent";
CM_ SG_ 1481 APS_sw235_smsWdtTimeout "Driver assistance computer (secondary): sw235 sms wdt timeout";
CM_ SG_ 1481 APS_sw235_smsCanApHealthTimeout "Driver assistance computer (secondary): sw235 sms can ap health timeout";
CM_ SG_ 1481 APS_sw235_smsTaskWdtTimeout "Driver assistance computer (secondary): sw235 sms task wdt timeout";
CM_ SG_ 1481 APS_sw237_faultSource "Driver assistance computer (secondary): sw237 fault source";
CM_ SG_ 1481 APS_sw237_peerSoCFaulted "Driver assistance computer (secondary): sw237 peer so c faulted";
CM_ SG_ 1481 APS_sw241_unknownVendorOnResume "Driver assistance computer (secondary): sw241 unknown vendor on resume";
CM_ SG_ 1481 APS_sw241_unknownVendorOnNonResu "Driver assistance computer (secondary): sw241 unknown vendor on non resume";
CM_ SG_ 1481 APS_sw241_phyReinitFailedOnResum "Driver assistance computer (secondary): sw241 phy reinit failed on resume";
CM_ SG_ 1481 APS_sw241_phyReinitFailedOnNonRe "Driver assistance computer (secondary): sw241 phy reinit failed on non resume";
CM_ SG_ 1481 APS_sw241_illTestFailed "Driver assistance computer (secondary): sw241 ill test failed";
CM_ SG_ 1481 APS_sw241_memTestFailed "Driver assistance computer (secondary): sw241 mem test failed";
CM_ SG_ 1481 APS_sw241_dfiInitCompleteTimeout "Driver assistance computer (secondary): sw241 dfi init complete timeout";
CM_ SG_ 1481 APS_sw241_phy0TimeoutWaitingForI "Driver assistance computer (secondary): sw241 phy0 timeout waiting for interrupts";
CM_ SG_ 1481 APS_sw241_phy0Ch0ReadGateOffsetB "Driver assistance computer (secondary): sw241 phy0 ch0 read gate offset bug";
CM_ SG_ 1481 APS_sw241_phy0Ch1ReadGateOffsetB "Driver assistance computer (secondary): sw241 phy0 ch1 read gate offset bug";
CM_ SG_ 1481 APS_sw241_phy0RdlvlReinitTrainin "Driver assistance computer (secondary): sw241 phy0 rdlvl reinit training timeout";
CM_ SG_ 1481 APS_sw241_phy0RdlvlReinitFailed "Driver assistance computer (secondary): sw241 phy0 rdlvl reinit failed";
CM_ SG_ 1481 APS_sw241_phy0WdqlvlReinitTraini "Driver assistance computer (secondary): sw241 phy0 wdqlvl reinit training timeout";
CM_ SG_ 1481 APS_sw241_phy0WdqlvlPhaseMarginO "Driver assistance computer (secondary): sw241 phy0 wdqlvl phase margin out of range";
CM_ SG_ 1481 APS_sw241_phy0WdqlvlReinitFailed "Driver assistance computer (secondary): sw241 phy0 wdqlvl reinit failed";
CM_ SG_ 1481 APS_sw241_phy1TimeoutWaitingForI "Driver assistance computer (secondary): sw241 phy1 timeout waiting for interrupts";
CM_ SG_ 1481 APS_sw241_phy1Ch0ReadGateOffsetB "Driver assistance computer (secondary): sw241 phy1 ch0 read gate offset bug";
CM_ SG_ 1481 APS_sw241_phy1Ch1ReadGateOffsetB "Driver assistance computer (secondary): sw241 phy1 ch1 read gate offset bug";
CM_ SG_ 1481 APS_sw241_phy1RdlvlReinitTrainin "Driver assistance computer (secondary): sw241 phy1 rdlvl reinit training timeout";
CM_ SG_ 1481 APS_sw241_phy1RdlvlReinitFailed "Driver assistance computer (secondary): sw241 phy1 rdlvl reinit failed";
CM_ SG_ 1481 APS_sw241_phy1WdqlvlReinitTraini "Driver assistance computer (secondary): sw241 phy1 wdqlvl reinit training timeout";
CM_ SG_ 1481 APS_sw241_phy1WdqlvlPhaseMarginO "Driver assistance computer (secondary): sw241 phy1 wdqlvl phase margin out of range";
CM_ SG_ 1481 APS_sw241_phy1WdqlvlReinitFailed "Driver assistance computer (secondary): sw241 phy1 wdqlvl reinit failed";
CM_ SG_ 1481 APS_sw241_phy2TimeoutWaitingForI "Driver assistance computer (secondary): sw241 phy2 timeout waiting for interrupts";
CM_ SG_ 1481 APS_sw241_phy2Ch0ReadGateOffsetB "Driver assistance computer (secondary): sw241 phy2 ch0 read gate offset bug";
CM_ SG_ 1481 APS_sw241_phy2Ch1ReadGateOffsetB "Driver assistance computer (secondary): sw241 phy2 ch1 read gate offset bug";
CM_ SG_ 1481 APS_sw241_phy2RdlvlReinitTrainin "Driver assistance computer (secondary): sw241 phy2 rdlvl reinit training timeout";
CM_ SG_ 1481 APS_sw241_phy2RdlvlReinitFailed "Driver assistance computer (secondary): sw241 phy2 rdlvl reinit failed";
CM_ SG_ 1481 APS_sw241_phy2WdqlvlReinitTraini "Driver assistance computer (secondary): sw241 phy2 wdqlvl reinit training timeout";
CM_ SG_ 1481 APS_sw241_phy2WdqlvlPhaseMarginO "Driver assistance computer (secondary): sw241 phy2 wdqlvl phase margin out of range";
CM_ SG_ 1481 APS_sw241_phy2WdqlvlReinitFailed "Driver assistance computer (secondary): sw241 phy2 wdqlvl reinit failed";
CM_ SG_ 1481 APS_sw241_phy3TimeoutWaitingForI "Driver assistance computer (secondary): sw241 phy3 timeout waiting for interrupts";
CM_ SG_ 1481 APS_sw241_phy3Ch0ReadGateOffsetB "Driver assistance computer (secondary): sw241 phy3 ch0 read gate offset bug";
CM_ SG_ 1481 APS_sw241_phy3Ch1ReadGateOffsetB "Driver assistance computer (secondary): sw241 phy3 ch1 read gate offset bug";
CM_ SG_ 1481 APS_sw241_phy3RdlvlReinitTrainin "Driver assistance computer (secondary): sw241 phy3 rdlvl reinit training timeout";
CM_ SG_ 1481 APS_sw241_phy3RdlvlReinitFailed "Driver assistance computer (secondary): sw241 phy3 rdlvl reinit failed";
CM_ SG_ 1481 APS_sw241_phy3WdqlvlReinitTraini "Driver assistance computer (secondary): sw241 phy3 wdqlvl reinit training timeout";
CM_ SG_ 1481 APS_sw241_phy3WdqlvlPhaseMarginO "Driver assistance computer (secondary): sw241 phy3 wdqlvl phase margin out of range";
CM_ SG_ 1481 APS_sw241_phy3WdqlvlReinitFailed "Driver assistance computer (secondary): sw241 phy3 wdqlvl reinit failed";
CM_ SG_ 1481 APS_sw242_instance "Driver assistance computer (secondary): sw242 instance";
CM_ SG_ 1481 APS_sw242_clusterSRAMMBISTFailed "Driver assistance computer (secondary): sw242 cluster SRAMMBIST failed";
CM_ SG_ 1481 APS_sw242_SRAMBankMBISTFailed "Driver assistance computer (secondary): sw242 SRAM bank MBIST failed";
CM_ SG_ 1481 APS_sw243_instance "Driver assistance computer (secondary): sw243 instance";
CM_ SG_ 1481 APS_sw243_errorStatus "Driver assistance computer (secondary): sw243 error status";
CM_ SG_ 1481 APS_sw243_extendedErrorStatus "Driver assistance computer (secondary): sw243 extended error status";
CM_ SG_ 1481 APS_sw244_instance "Driver assistance computer (secondary): sw244 instance";
CM_ SG_ 1481 APS_sw244_exceptionCode "Driver assistance computer (secondary): sw244 exception code";
CM_ SG_ 1481 APS_sw245_unknownMACAddrByte0 "Driver assistance computer (secondary): sw245 unknown MAC addr byte0";
CM_ SG_ 1481 APS_sw245_unknownMACAddrByte1 "Driver assistance computer (secondary): sw245 unknown MAC addr byte1";
CM_ SG_ 1481 APS_sw245_unknownMACAddrByte2 "Driver assistance computer (secondary): sw245 unknown MAC addr byte2";
CM_ SG_ 1481 APS_sw245_unknownMACAddrByte3 "Driver assistance computer (secondary): sw245 unknown MAC addr byte3";
CM_ SG_ 1481 APS_sw245_unknownMACAddrByte4 "Driver assistance computer (secondary): sw245 unknown MAC addr byte4";
CM_ SG_ 1481 APS_sw245_unknownMACAddrByte5 "Driver assistance computer (secondary): sw245 unknown MAC addr byte5";
CM_ SG_ 1481 APS_sw246_ethloopSwitchPort0 "Driver assistance computer (secondary): sw246 ethloop switch port0";
CM_ SG_ 1481 APS_sw246_ethloopSwitchPort1 "Driver assistance computer (secondary): sw246 ethloop switch port1";
CM_ SG_ 1481 APS_sw246_ethloopSwitchPort2 "Driver assistance computer (secondary): sw246 ethloop switch port2";
CM_ SG_ 1481 APS_sw246_ethloopSwitchPort3 "Driver assistance computer (secondary): sw246 ethloop switch port3";
CM_ SG_ 1481 APS_sw246_ethloopSwitchPort4 "Driver assistance computer (secondary): sw246 ethloop switch port4";
CM_ SG_ 1481 APS_sw246_ethloopSwitchPort5 "Driver assistance computer (secondary): sw246 ethloop switch port5";
CM_ SG_ 1481 APS_sw246_ethloopSwitchPort6 "Driver assistance computer (secondary): sw246 ethloop switch port6";
CM_ SG_ 1481 APS_sw246_ethloopSwitchPort7 "Driver assistance computer (secondary): sw246 ethloop switch port7";
CM_ SG_ 1481 APS_sw247_crcError "Driver assistance computer (secondary): sw247 crc error";
CM_ SG_ 1481 APS_sw247_dribbleError "Driver assistance computer (secondary): sw247 dribble error";
CM_ SG_ 1481 APS_sw247_receiveError "Driver assistance computer (secondary): sw247 receive error";
CM_ SG_ 1481 APS_sw247_wdogTimeout "Driver assistance computer (secondary): sw247 wdog timeout";
CM_ SG_ 1481 APS_sw247_overflowError "Driver assistance computer (secondary): sw247 overflow error";
CM_ SG_ 1481 APS_sw247_giantPacket "Driver assistance computer (secondary): sw247 giant packet";
CM_ SG_ 1481 APS_sw247_destAddrFilterFail "Driver assistance computer (secondary): sw247 dest addr filter fail";
CM_ SG_ 1481 APS_sw247_saAddressFilterFail "Driver assistance computer (secondary): sw247 sa address filter fail";
CM_ SG_ 1481 APS_sw248_ethloopSwitchPort2Sqi "Driver assistance computer (secondary): sw248 ethloop switch port2 sqi";
CM_ SG_ 1481 APS_sw248_ethloopSwitchPort3Sqi "Driver assistance computer (secondary): sw248 ethloop switch port3 sqi";
CM_ SG_ 1481 APS_sw249_ufsInitFailureReason "Driver assistance computer (secondary): sw249 ufs init failure reason";
CM_ SG_ 1481 APS_sw252_ethSwitchPort2 "Driver assistance computer (secondary): sw252 eth switch port2";
CM_ SG_ 1481 APS_sw253_apWaitForShutdownTimeo "Driver assistance computer (secondary): sw253 ap wait for shutdown timeout";
CM_ SG_ 1481 APS_sw253_apOffPrepareTimeout "Driver assistance computer (secondary): sw253 ap off prepare timeout";
CM_ SG_ 1481 APS_sw253_apSuspendedTimeout "Driver assistance computer (secondary): sw253 ap suspended timeout";
CM_ SG_ 1481 APS_sw253_socOffReadyTimeout "Driver assistance computer (secondary): sw253 soc off ready timeout";
CM_ SG_ 1481 APS_sw253_apInLinuxTimeout "Driver assistance computer (secondary): sw253 ap in linux timeout";
CM_ SG_ 1481 APS_sw253_apInCorebootTimeout "Driver assistance computer (secondary): sw253 ap in coreboot timeout";
CM_ SG_ 1481 APS_sw253_apBootingTimeout "Driver assistance computer (secondary): sw253 ap booting timeout";
CM_ SG_ 1481 APS_sw253_apOnTimeout "Driver assistance computer (secondary): sw253 ap on timeout";
CM_ SG_ 1481 APS_sw254_waitForBusSilenceTimeo "Driver assistance computer (secondary): sw254 wait for bus silence timeout";
CM_ SG_ 1481 APS_sw254_sleepReadyTimeout "Driver assistance computer (secondary): sw254 sleep ready timeout";
CM_ SG_ 1481 APS_sw254_sleepingTimeout "Driver assistance computer (secondary): sw254 sleeping timeout";
CM_ SG_ 1481 APS_sw255_unknownBootError "Driver assistance computer (secondary): sw255 unknown boot error";
CM_ SG_ 1481 APS_sw255_adcWrapperInitBootErro "Driver assistance computer (secondary): sw255 adc wrapper init boot error";
CM_ SG_ 1481 APS_sw255_boardRevisionInitBootE "Driver assistance computer (secondary): sw255 board revision init boot error";
CM_ SG_ 1481 APS_sw255_i2cInitBootError "Driver assistance computer (secondary): sw255 i2c init boot error";
CM_ SG_ 1481 APS_sw255_provisionInitBootError "Driver assistance computer (secondary): sw255 provision init boot error";
CM_ SG_ 1481 APS_sw255_rtcInitBootError "Driver assistance computer (secondary): sw255 rtc init boot error";
CM_ SG_ 1481 APS_sw255_vrmInitConfigBootError "Driver assistance computer (secondary): sw255 vrm init config boot error";
CM_ SG_ 1481 APS_sw255_powerAonIoBootError "Driver assistance computer (secondary): sw255 power aon io boot error";
CM_ SG_ 1481 APS_sw255_bl1TocInitBootError "Driver assistance computer (secondary): sw255 bl1 toc init boot error";
CM_ SG_ 1481 APS_sw255_tmuInitBootError "Driver assistance computer (secondary): sw255 tmu init boot error";
CM_ SG_ 1481 APS_sw255_udpInitBootError "Driver assistance computer (secondary): sw255 udp init boot error";
CM_ SG_ 1481 APS_sw255_gpsInitBootError "Driver assistance computer (secondary): sw255 gps init boot error";
CM_ SG_ 1481 APS_sw255_canInitBootError "Driver assistance computer (secondary): sw255 can init boot error";
CM_ SG_ 1481 APS_sw255_dfuCheckinSubsystemBoo "Driver assistance computer (secondary): sw255 dfu checkin subsystem boot error";
CM_ SG_ 1481 APS_sw255_sectorProtectionBootEr "Driver assistance computer (secondary): sw255 sector protection boot error";
CM_ SG_ 1481 APS_sw255_flashOpBootError "Driver assistance computer (secondary): sw255 flash op boot error";
CM_ SG_ 1481 APS_sw255_socIdInitBootError "Driver assistance computer (secondary): sw255 soc id init boot error";
CM_ SG_ 1481 APS_sw260_pgoodTripSramStatus "Driver assistance computer (secondary): sw260 pgood trip sram status";
CM_ SG_ 1481 APS_sw260_pgoodPmicFaultSd0 "Driver assistance computer (secondary): sw260 pgood pmic fault sd0";
CM_ SG_ 1481 APS_sw260_pgoodPmicFaultSd1 "Driver assistance computer (secondary): sw260 pgood pmic fault sd1";
CM_ SG_ 1481 APS_sw260_pgoodPmicFaultSd2 "Driver assistance computer (secondary): sw260 pgood pmic fault sd2";
CM_ SG_ 1481 APS_sw260_pgoodPmicFaultSd3 "Driver assistance computer (secondary): sw260 pgood pmic fault sd3";
CM_ SG_ 1481 APS_sw260_pgoodPmicFaultSd4 "Driver assistance computer (secondary): sw260 pgood pmic fault sd4";
CM_ SG_ 1481 APS_sw260_pgoodPmicFaultLdo0 "Driver assistance computer (secondary): sw260 pgood pmic fault ldo0";
CM_ SG_ 1481 APS_sw260_pgoodPmicFaultLdo1 "Driver assistance computer (secondary): sw260 pgood pmic fault ldo1";
CM_ SG_ 1481 APS_sw260_pgoodPmicFaultLdo2 "Driver assistance computer (secondary): sw260 pgood pmic fault ldo2";
CM_ SG_ 1481 APS_sw260_pgoodPmicFaultLdo3 "Driver assistance computer (secondary): sw260 pgood pmic fault ldo3";
CM_ SG_ 1481 APS_sw260_pgoodPmicFaultLdo4 "Driver assistance computer (secondary): sw260 pgood pmic fault ldo4";
CM_ SG_ 1481 APS_sw260_pgoodPmicFaultLdo5 "Driver assistance computer (secondary): sw260 pgood pmic fault ldo5";
CM_ SG_ 1481 APS_sw260_pgoodPmicFaultLdo6 "Driver assistance computer (secondary): sw260 pgood pmic fault ldo6";
CM_ SG_ 1481 APS_sw260_pgoodPmicFaultLdo7 "Driver assistance computer (secondary): sw260 pgood pmic fault ldo7";
CM_ SG_ 1481 APS_sw260_pgoodPmicFaultLdo8 "Driver assistance computer (secondary): sw260 pgood pmic fault ldo8";
CM_ SG_ 1481 APS_sw260_pgoodUfs3V3Fail "Driver assistance computer (secondary): sw260 pgood ufs3 V3 fail";
CM_ SG_ 1481 APS_sw260_pgoodTripVrmRailFail "Driver assistance computer (secondary): sw260 pgood trip vrm rail fail";
CM_ SG_ 1481 APS_sw260_pgoodIntVrmRailFail "Driver assistance computer (secondary): sw260 pgood int vrm rail fail";
CM_ SG_ 1481 APS_sw260_pgoodCpuVrmRailFail "Driver assistance computer (secondary): sw260 pgood cpu vrm rail fail";
CM_ SG_ 1481 APS_sw260_pgoodGpuVrmRailFail "Driver assistance computer (secondary): sw260 pgood gpu vrm rail fail";
CM_ SG_ 1481 APS_sw260_pgoodDdr0V75VrmRailFai "Driver assistance computer (secondary): sw260 pgood ddr0 V75 vrm rail fail";
CM_ SG_ 1481 APS_sw260_pgoodDdr1V25VrmRailFai "Driver assistance computer (secondary): sw260 pgood ddr1 V25 vrm rail fail";
CM_ SG_ 1481 APS_sw260_unknownSource "Driver assistance computer (secondary): sw260 unknown source";
CM_ SG_ 1481 APS_sw261_vrmPublicFaultValues "Driver assistance computer (secondary): sw261 vrm public fault values";
CM_ SG_ 1481 APS_sw261_vrmRail1FaultValues "Driver assistance computer (secondary): sw261 vrm rail1 fault values";
CM_ SG_ 1481 APS_sw261_vrmRail2FaultValues "Driver assistance computer (secondary): sw261 vrm rail2 fault values";
CM_ SG_ 1481 APS_sw261_vrmRail3FaultValues "Driver assistance computer (secondary): sw261 vrm rail3 fault values";
CM_ SG_ 1481 APS_sw261_vrmType "Driver assistance computer (secondary): sw261 vrm type";
CM_ SG_ 1481 APS_sw262_vrmPublicFaultValues "Driver assistance computer (secondary): sw262 vrm public fault values";
CM_ SG_ 1481 APS_sw262_vrmRail1FaultValues "Driver assistance computer (secondary): sw262 vrm rail1 fault values";
CM_ SG_ 1481 APS_sw262_vrmRail2FaultValues "Driver assistance computer (secondary): sw262 vrm rail2 fault values";
CM_ SG_ 1481 APS_sw262_vrmRail3FaultValues "Driver assistance computer (secondary): sw262 vrm rail3 fault values";
CM_ SG_ 1481 APS_sw262_vrmType "Driver assistance computer (secondary): sw262 vrm type";
CM_ SG_ 1481 APS_sw263_vrmPublicFaultValues "Driver assistance computer (secondary): sw263 vrm public fault values";
CM_ SG_ 1481 APS_sw263_vrmRail1FaultValues "Driver assistance computer (secondary): sw263 vrm rail1 fault values";
CM_ SG_ 1481 APS_sw263_vrmRail2FaultValues "Driver assistance computer (secondary): sw263 vrm rail2 fault values";
CM_ SG_ 1481 APS_sw263_vrmType "Driver assistance computer (secondary): sw263 vrm type";
CM_ SG_ 1481 APS_sw279_corruptDirectorySource "Driver assistance computer (secondary): sw279 corrupt directory source";
CM_ SG_ 1481 APS_sw279_errorCode "Driver assistance computer (secondary): sw279 error code";
CM_ SG_ 1481 APS_sw280_pepsStatus "Driver assistance computer (secondary): sw280 peps status";
CM_ SG_ 1481 APS_sw281_rearSteerStatus "Driver assistance computer (secondary): sw281 rear steer status";
CM_ SG_ 1481 APS_sw283_psfaStatus "Driver assistance computer (secondary): sw283 psfa status";
CM_ SG_ 1481 APS_sw288_status "Driver assistance computer (secondary): sw288 status";
CM_ SG_ 1481 APS_sw289_turboTemperature "Driver assistance computer (secondary): sw289 turbo temperature";
CM_ SG_ 1481 APS_sw289_turboProbe "Driver assistance computer (secondary): sw289 turbo probe";
CM_ SG_ 1481 APS_sw289_peer_turboTemperature "Driver assistance computer (secondary): sw289 peer turbo temperature";
CM_ SG_ 1481 APS_sw289_peer_turboProbe "Driver assistance computer (secondary): sw289 peer turbo probe";
CM_ SG_ 1481 APS_sw315_sysStatus "Driver assistance computer (secondary): sw315 sys status";
CM_ SG_ 1481 APS_sw315_status "Driver assistance computer (secondary): sw315 status";
CM_ SG_ 1481 APS_sw317_motionControlCommand "Driver assistance computer (secondary): sw317 motion control command";
CM_ SG_ 1481 APS_sw317_vehicleControl2 "Driver assistance computer (secondary): sw317 vehicle control2";
CM_ BO_ 637 "Driver assistance computer (secondary) message: eac monitor";
CM_ SG_ 637 APS_eacAllow "Indicates whether or not the Aurix external angle control (EAC) monitor logic currently allows angle control for Autopilot functions.";
CM_ SG_ 637 APS_eacMonitorCounter "Driver assistance computer (secondary): eac monitor counter";
CM_ SG_ 637 APS_eacMonitorChecksum "Driver assistance computer (secondary): eac monitor checksum";
CM_ BO_ 1865 "Driver assistance computer (secondary) message: power state inputs";
CM_ SG_ 1865 APS_A_lowPowerRequest "Indicates Autopilot Secondary Processor (APS) low power state request presence.";
CM_ SG_ 1865 APS_A_lowPowerRequestor "Indicates who initiated the Autopilot Secondary Processor (APS) low power request.";
CM_ SG_ 1865 APS_A_forcePowerOffRequest "Driver assistance computer (secondary): a force power off request";
CM_ SG_ 1865 APS_B_lowPowerRequest "Indicates Autopilot Secondary Processor (APS) low power state request presence.";
CM_ SG_ 1865 APS_B_lowPowerRequestor "Indicates who initiated the Autopilot Secondary Processor (APS) low power request.";
CM_ SG_ 1865 APS_B_forcePowerOffRequest "Driver assistance computer (secondary): b force power off request";
CM_ BO_ 2044 "Driver assistance computer (secondary) message: state";
CM_ SG_ 2044 APS_primaryTurbo "Which of the two Turbos currently holds the primary role.";
CM_ SG_ 2044 APS_A_arbState "The state of the arbitration state machine of Turbo A.";
CM_ SG_ 2044 APS_A_powerState "The state of the power state machine of Turbo A.";
CM_ SG_ 2044 APS_A_sleepState "The state of the sleep state machine of Turbo A.";
CM_ SG_ 2044 APS_A_resetState "The state of the reset state machine of Turbo A.";
CM_ SG_ 2044 APS_A_faultState "The state of the fault state machine of Turbo A.";
CM_ SG_ 2044 APS_secondaryTurbo "Which of the two Turbos currently holds the secondary role.";
CM_ SG_ 2044 APS_B_arbState "The state of the arbitration state machine of Turbo B.";
CM_ SG_ 2044 APS_B_powerState "The state of the power state machine of Turbo B.";
CM_ SG_ 2044 APS_B_sleepState "The state of the sleep state machine of Turbo B.";
CM_ SG_ 2044 APS_B_resetState "The state of the reset state machine of Turbo B.";
CM_ SG_ 2044 APS_B_faultState "The state of the fault state machine of Turbo B.";
CM_ SG_ 2044 APS_A_autosteerMonitorState "Driver assistance computer (secondary): a autosteer monitor state";
CM_ SG_ 2044 APS_B_autosteerMonitorState "Driver assistance computer (secondary): b autosteer monitor state";
CM_ SG_ 2044 APS_eplannerState "Driver assistance computer (secondary): eplanner state";
CM_ SG_ 2044 APS_A_faultInduced "Driver assistance computer (secondary): a fault induced";
CM_ SG_ 2044 APS_B_faultInduced "Driver assistance computer (secondary): b fault induced";
CM_ SG_ 2044 APS_stateCounter "Driver assistance computer (secondary): state counter";
CM_ BO_ 970 "Driver assistance computer (secondary) message: status";
CM_ SG_ 970 APS_appStatusMonitorState "The current status of APE, indicates the health of the stack on the APE";
CM_ SG_ 970 APS_vehBehaviorState "Driver assistance computer (secondary): veh behavior state";
CM_ SG_ 970 APS_canMaster "Indicates which of the autopilot computers is currently controlling outgoing CAN traffic.";
CM_ SG_ 970 APS_appGpioState "The GPIO state of APEA, indicates the health of the primary Parker (HW2 and HW2.5)";
CM_ SG_ 970 APS_eacInternalState "Indicates the internal state of the external angle control monitor running on Aurix.";
CM_ SG_ 970 APS_switchState "Driver assistance computer (secondary): switch state";
CM_ SG_ 970 APS_apbStatusMonitorState "The current status of APEB, indicates the health of the stack on the APEB";
CM_ SG_ 970 APS_apbGpioState "The GPIO state of APEB, indicates the health of the secondary Parker (HW2.5 only)";
CM_ SG_ 970 APS_statusCounter "Driver assistance computer (secondary): status counter";
CM_ SG_ 970 APS_locLimitReason "Indicates why longitudinal control limits are currently not relaxed";
CM_ SG_ 970 APS_appPowerStateRequest "Indicates ap primary power state request";
CM_ SG_ 970 APS_appPowerStateReason "Indicates ap primary power state reason";
CM_ SG_ 970 APS_apbPowerStateRequest "Indicates ap backup power state request";
CM_ SG_ 970 APS_apbPowerStateReason "Indicates ap backup power state reason";
CM_ SG_ 970 APS_heaterStateDebug "Driver assistance computer (secondary): heater state debug";
CM_ SG_ 970 APS_autosummonCounter "Driver assistance computer (secondary): autosummon counter";
CM_ SG_ 970 APS_autosummonAlert "Driver assistance computer (secondary): autosummon alert";
CM_ SG_ 970 APS_gpsAntennaState "Driver assistance computer (secondary): gps antenna state";
CM_ SG_ 970 APS_arbState "Reports the state of the arbitration state machine of this System on Chip (SoC).";
CM_ SG_ 970 APS_socPowerOperatingMode "Reports the total number of System on Chips (SoCs) that are powered on to provide support for active Autopilot features.";
CM_ SG_ 970 APS_otherArbState "Reports the state of the arbitration state machine of the other System on Chip (SoC). Lets the current SoC know the state of the other SoC to achieve safer operations.";
CM_ SG_ 970 APS_appActivePlannerType "Driver assistance computer (secondary): app active planner type";
CM_ SG_ 970 APS_apbActivePlannerType "Driver assistance computer (secondary): apb active planner type";
CM_ BO_ 1052 "Driver assistance computer (secondary) message: status2";
CM_ SG_ 1052 APS_autonomyBehavior "Reports the current autonomy mode indicated by Autopilot Secondary (APS).";
CM_ SG_ 1052 APS_status2Counter "Driver assistance computer (secondary): status2 counter";
CM_ SG_ 1052 APS_cameraMitigationRequired "Driver assistance computer (secondary): camera mitigation required";
CM_ SG_ 1052 APS_autonomyControlActive "Driver assistance computer (secondary): autonomy control active";
CM_ SG_ 1052 APS_A_manualMotionControlState "Driver assistance computer (secondary): a manual motion control state";
CM_ SG_ 1052 APS_B_manualMotionControlState "Driver assistance computer (secondary): b manual motion control state";
CM_ BO_ 1510 "Driver assistance computer (secondary) message: sys health";
CM_ SG_ 1510 APS_A_cam12v0Voltage "Measures the 12V camera power supply voltage for Autopilot Secondary Processor (APS) Turbo A";
CM_ SG_ 1510 APS_B_cam12v0Voltage "Measures the 12V camera power supply voltage for Autopilot Secondary Processor (APS) Turbo B";
CM_ SG_ 1510 APS_A_turboMaxTemperature "Reports the maximum temperature recorded by Autopilot Secondary Processor (APS) unit A.";
CM_ SG_ 1510 APS_A_turboProbeType "Driver assistance computer (secondary): a turbo probe type";
CM_ SG_ 1510 APS_B_turboMaxTemperature "Reports the maximum temperature recorded by Autopilot Secondary Processor (APS) unit B.";
CM_ SG_ 1510 APS_B_turboProbeType "Driver assistance computer (secondary): b turbo probe type";
BA_DEF_ BO_ "GenMsgCycleTime" INT 0 3600000;
BA_DEF_ BO_ "GenMsgSendType" ENUM "Cyclic","NotUsed","NotUsed","NotUsed","NotUsed","NotUsed","NotUsed","IfActive","NoMsgSendType","NotUsed";
BA_DEF_ BO_ "VFrameFormat" ENUM "StandardCAN","ExtendedCAN","reserved","J1939PG","reserved","reserved","reserved","reserved","reserved","reserved","reserved","reserved","reserved","reserved","StandardCAN_FD","ExtendedCAN_FD";
BA_DEF_ BO_ "CANFD_BRS" ENUM "0","1";
BA_DEF_ SG_ "SystemSignalLongSymbol" STRING;
BA_DEF_ SG_ "Confidence" ENUM "layout-only","plausible","validated";
BA_DEF_DEF_ "GenMsgCycleTime" 0;
BA_DEF_DEF_ "GenMsgSendType" "NoMsgSendType";
BA_DEF_DEF_ "VFrameFormat" "StandardCAN";
BA_DEF_DEF_ "CANFD_BRS" "1";
BA_DEF_DEF_ "SystemSignalLongSymbol" "";
BA_DEF_DEF_ "Confidence" "layout-only";
BA_ "SystemSignalLongSymbol" SG_ 845 APSB_w040_autopilotAngleSaturate "APSB_w040_autopilotAngleSaturated";
BA_ "SystemSignalLongSymbol" SG_ 1143 APSB_w065_deserializerOvercurren "APSB_w065_deserializerOvercurrent";
BA_ "SystemSignalLongSymbol" SG_ 976 APSB_w215_contDriverNotIntractin "APSB_w215_contDriverNotIntracting";
BA_ "SystemSignalLongSymbol" SG_ 976 APSB_w245_eloopRxFromUnexpectedS "APSB_w245_eloopRxFromUnexpectedSourceMAC";
BA_ "SystemSignalLongSymbol" SG_ 976 APSB_w246_ethloopSwitchPortLinkD "APSB_w246_ethloopSwitchPortLinkDown";
BA_ "SystemSignalLongSymbol" SG_ 976 APSB_w250_ethloopSwitchMemUsageT "APSB_w250_ethloopSwitchMemUsageTooHighPort2";
BA_ "SystemSignalLongSymbol" SG_ 976 APSB_w251_ethloopSwitchMemUsageT "APSB_w251_ethloopSwitchMemUsageTooHighPort3";
BA_ "SystemSignalLongSymbol" SG_ 1003 APSB_w258_qspiFlashSectorChecksu "APSB_w258_qspiFlashSectorChecksumMismatch";
BA_ "SystemSignalLongSymbol" SG_ 1003 APSB_w269_ethSwitchRxPageCountTo "APSB_w269_ethSwitchRxPageCountTooHighPort0_3";
BA_ "SystemSignalLongSymbol" SG_ 1003 APSB_w270_ethSwitchRxPageCountTo "APSB_w270_ethSwitchRxPageCountTooHighPort4_7";
BA_ "SystemSignalLongSymbol" SG_ 1003 APSB_w284_cam12VBuckBoostAPwrIss "APSB_w284_cam12VBuckBoostAPwrIssue";
BA_ "SystemSignalLongSymbol" SG_ 1003 APSB_w285_cam12VBuckBoostBPwrIss "APSB_w285_cam12VBuckBoostBPwrIssue";
BA_ "SystemSignalLongSymbol" SG_ 1003 APSB_w286_cam12VEFuseAPrimaryIss "APSB_w286_cam12VEFuseAPrimaryIssue";
BA_ "SystemSignalLongSymbol" SG_ 1003 APSB_w287_cam12VEFuseASecondaryI "APSB_w287_cam12VEFuseASecondaryIssue";
BA_ "SystemSignalLongSymbol" SG_ 1003 APSB_w289_turboTemperatureWarnin "APSB_w289_turboTemperatureWarning";
BA_ "SystemSignalLongSymbol" SG_ 1003 APSB_w290_cam12VBuckBoostBPwrRin "APSB_w290_cam12VBuckBoostBPwrRinging";
BA_ "SystemSignalLongSymbol" SG_ 1003 APSB_w296_wdogMonTaskDeadlineMis "APSB_w296_wdogMonTaskDeadlineMiss";
BA_ "SystemSignalLongSymbol" SG_ 1003 APSB_w298_cpuToApCanSharedMemErr "APSB_w298_cpuToApCanSharedMemError";
BA_ "SystemSignalLongSymbol" SG_ 1003 APSB_w299_apToCpuCanSharedMemErr "APSB_w299_apToCpuCanSharedMemError";
BA_ "SystemSignalLongSymbol" SG_ 1003 APSB_w300_sharedMemoryAccessErro "APSB_w300_sharedMemoryAccessError";
BA_ "SystemSignalLongSymbol" SG_ 1003 APSB_w318_ethernetNetworkBufferH "APSB_w318_ethernetNetworkBufferHighWatermark";
BA_ "SystemSignalLongSymbol" SG_ 1003 APSB_w320_eplannerPreconditionsM "APSB_w320_eplannerPreconditionsMet";
BA_ "SystemSignalLongSymbol" SG_ 1481 APS_sw133_switchEthernetInterLin "APS_sw133_switchEthernetInterLinkDown";
BA_ "SystemSignalLongSymbol" SG_ 1481 APS_sw133_ethSwitchReadFwVerFail "APS_sw133_ethSwitchReadFwVerFailed";
BA_ "SystemSignalLongSymbol" SG_ 1481 APS_sw133_ethSwitchTimedoutUpdat "APS_sw133_ethSwitchTimedoutUpdate";
BA_ "SystemSignalLongSymbol" SG_ 1481 APS_sw133_ethSwitchMcuLinkFailov "APS_sw133_ethSwitchMcuLinkFailover";
BA_ "SystemSignalLongSymbol" SG_ 1481 APS_sw133_ethSwitchMcuLinkDuplic "APS_sw133_ethSwitchMcuLinkDuplicated";
BA_ "SystemSignalLongSymbol" SG_ 1481 APS_sw133_ethSwitchMcuLinkDiscon "APS_sw133_ethSwitchMcuLinkDisconnected";
BA_ "SystemSignalLongSymbol" SG_ 1481 APS_sw134_dasAutonomyControlPart "APS_sw134_dasAutonomyControlParty";
BA_ "SystemSignalLongSymbol" SG_ 1481 APS_sw134_dasMatrixBendAngleRqPt "APS_sw134_dasMatrixBendAngleRqPty";
BA_ "SystemSignalLongSymbol" SG_ 1481 APS_sw134_dasRedundantBrakingCon "APS_sw134_dasRedundantBrakingControl";
BA_ "SystemSignalLongSymbol" SG_ 1481 APS_sw134_dasRedundantBraki_0001 "APS_sw134_dasRedundantBrakingControlPty";
BA_ "SystemSignalLongSymbol" SG_ 1481 APS_sw158_dasAutonomyControlPart "APS_sw158_dasAutonomyControlParty";
BA_ "SystemSignalLongSymbol" SG_ 1481 APS_sw158_dasMatrixBendAngleRqPt "APS_sw158_dasMatrixBendAngleRqPty";
BA_ "SystemSignalLongSymbol" SG_ 1481 APS_sw158_dasRedundantBrakingCon "APS_sw158_dasRedundantBrakingControl";
BA_ "SystemSignalLongSymbol" SG_ 1481 APS_sw158_dasRedundantBraki_0001 "APS_sw158_dasRedundantBrakingControlPty";
BA_ "SystemSignalLongSymbol" SG_ 1481 APS_sw241_unknownVendorOnNonResu "APS_sw241_unknownVendorOnNonResume";
BA_ "SystemSignalLongSymbol" SG_ 1481 APS_sw241_phyReinitFailedOnResum "APS_sw241_phyReinitFailedOnResume";
BA_ "SystemSignalLongSymbol" SG_ 1481 APS_sw241_phyReinitFailedOnNonRe "APS_sw241_phyReinitFailedOnNonResume";
BA_ "SystemSignalLongSymbol" SG_ 1481 APS_sw241_phy0TimeoutWaitingForI "APS_sw241_phy0TimeoutWaitingForInterrupts";
BA_ "SystemSignalLongSymbol" SG_ 1481 APS_sw241_phy0Ch0ReadGateOffsetB "APS_sw241_phy0Ch0ReadGateOffsetBug";
BA_ "SystemSignalLongSymbol" SG_ 1481 APS_sw241_phy0Ch1ReadGateOffsetB "APS_sw241_phy0Ch1ReadGateOffsetBug";
BA_ "SystemSignalLongSymbol" SG_ 1481 APS_sw241_phy0RdlvlReinitTrainin "APS_sw241_phy0RdlvlReinitTrainingTimeout";
BA_ "SystemSignalLongSymbol" SG_ 1481 APS_sw241_phy0WdqlvlReinitTraini "APS_sw241_phy0WdqlvlReinitTrainingTimeout";
BA_ "SystemSignalLongSymbol" SG_ 1481 APS_sw241_phy0WdqlvlPhaseMarginO "APS_sw241_phy0WdqlvlPhaseMarginOutOfRange";
BA_ "SystemSignalLongSymbol" SG_ 1481 APS_sw241_phy1TimeoutWaitingForI "APS_sw241_phy1TimeoutWaitingForInterrupts";
BA_ "SystemSignalLongSymbol" SG_ 1481 APS_sw241_phy1Ch0ReadGateOffsetB "APS_sw241_phy1Ch0ReadGateOffsetBug";
BA_ "SystemSignalLongSymbol" SG_ 1481 APS_sw241_phy1Ch1ReadGateOffsetB "APS_sw241_phy1Ch1ReadGateOffsetBug";
BA_ "SystemSignalLongSymbol" SG_ 1481 APS_sw241_phy1RdlvlReinitTrainin "APS_sw241_phy1RdlvlReinitTrainingTimeout";
BA_ "SystemSignalLongSymbol" SG_ 1481 APS_sw241_phy1WdqlvlReinitTraini "APS_sw241_phy1WdqlvlReinitTrainingTimeout";
BA_ "SystemSignalLongSymbol" SG_ 1481 APS_sw241_phy1WdqlvlPhaseMarginO "APS_sw241_phy1WdqlvlPhaseMarginOutOfRange";
BA_ "SystemSignalLongSymbol" SG_ 1481 APS_sw241_phy2TimeoutWaitingForI "APS_sw241_phy2TimeoutWaitingForInterrupts";
BA_ "SystemSignalLongSymbol" SG_ 1481 APS_sw241_phy2Ch0ReadGateOffsetB "APS_sw241_phy2Ch0ReadGateOffsetBug";
BA_ "SystemSignalLongSymbol" SG_ 1481 APS_sw241_phy2Ch1ReadGateOffsetB "APS_sw241_phy2Ch1ReadGateOffsetBug";
BA_ "SystemSignalLongSymbol" SG_ 1481 APS_sw241_phy2RdlvlReinitTrainin "APS_sw241_phy2RdlvlReinitTrainingTimeout";
BA_ "SystemSignalLongSymbol" SG_ 1481 APS_sw241_phy2WdqlvlReinitTraini "APS_sw241_phy2WdqlvlReinitTrainingTimeout";
BA_ "SystemSignalLongSymbol" SG_ 1481 APS_sw241_phy2WdqlvlPhaseMarginO "APS_sw241_phy2WdqlvlPhaseMarginOutOfRange";
BA_ "SystemSignalLongSymbol" SG_ 1481 APS_sw241_phy3TimeoutWaitingForI "APS_sw241_phy3TimeoutWaitingForInterrupts";
BA_ "SystemSignalLongSymbol" SG_ 1481 APS_sw241_phy3Ch0ReadGateOffsetB "APS_sw241_phy3Ch0ReadGateOffsetBug";
BA_ "SystemSignalLongSymbol" SG_ 1481 APS_sw241_phy3Ch1ReadGateOffsetB "APS_sw241_phy3Ch1ReadGateOffsetBug";
BA_ "SystemSignalLongSymbol" SG_ 1481 APS_sw241_phy3RdlvlReinitTrainin "APS_sw241_phy3RdlvlReinitTrainingTimeout";
BA_ "SystemSignalLongSymbol" SG_ 1481 APS_sw241_phy3WdqlvlReinitTraini "APS_sw241_phy3WdqlvlReinitTrainingTimeout";
BA_ "SystemSignalLongSymbol" SG_ 1481 APS_sw241_phy3WdqlvlPhaseMarginO "APS_sw241_phy3WdqlvlPhaseMarginOutOfRange";
BA_ "SystemSignalLongSymbol" SG_ 1481 APS_sw253_apWaitForShutdownTimeo "APS_sw253_apWaitForShutdownTimeout";
BA_ "SystemSignalLongSymbol" SG_ 1481 APS_sw254_waitForBusSilenceTimeo "APS_sw254_waitForBusSilenceTimeout";
BA_ "SystemSignalLongSymbol" SG_ 1481 APS_sw255_adcWrapperInitBootErro "APS_sw255_adcWrapperInitBootError";
BA_ "SystemSignalLongSymbol" SG_ 1481 APS_sw255_boardRevisionInitBootE "APS_sw255_boardRevisionInitBootError";
BA_ "SystemSignalLongSymbol" SG_ 1481 APS_sw255_dfuCheckinSubsystemBoo "APS_sw255_dfuCheckinSubsystemBootError";
BA_ "SystemSignalLongSymbol" SG_ 1481 APS_sw255_sectorProtectionBootEr "APS_sw255_sectorProtectionBootError";
BA_ "SystemSignalLongSymbol" SG_ 1481 APS_sw260_pgoodDdr0V75VrmRailFai "APS_sw260_pgoodDdr0V75VrmRailFail";
BA_ "SystemSignalLongSymbol" SG_ 1481 APS_sw260_pgoodDdr1V25VrmRailFai "APS_sw260_pgoodDdr1V25VrmRailFail";
BA_ "Confidence" SG_ 637 APS_eacAllow 1;
BA_ "Confidence" SG_ 1865 APS_A_lowPowerRequest 1;
BA_ "Confidence" SG_ 1865 APS_A_lowPowerRequestor 1;
BA_ "Confidence" SG_ 1865 APS_B_lowPowerRequest 1;
BA_ "Confidence" SG_ 1865 APS_B_lowPowerRequestor 1;
BA_ "Confidence" SG_ 2044 APS_primaryTurbo 1;
BA_ "Confidence" SG_ 2044 APS_A_arbState 1;
BA_ "Confidence" SG_ 2044 APS_A_powerState 1;
BA_ "Confidence" SG_ 2044 APS_A_sleepState 1;
BA_ "Confidence" SG_ 2044 APS_A_resetState 1;
BA_ "Confidence" SG_ 2044 APS_A_faultState 1;
BA_ "Confidence" SG_ 2044 APS_secondaryTurbo 1;
BA_ "Confidence" SG_ 2044 APS_B_arbState 1;
BA_ "Confidence" SG_ 2044 APS_B_powerState 1;
BA_ "Confidence" SG_ 2044 APS_B_sleepState 1;
BA_ "Confidence" SG_ 2044 APS_B_resetState 1;
BA_ "Confidence" SG_ 2044 APS_B_faultState 1;
BA_ "Confidence" SG_ 2044 APS_A_autosteerMonitorState 1;
BA_ "Confidence" SG_ 2044 APS_B_autosteerMonitorState 1;
BA_ "Confidence" SG_ 2044 APS_eplannerState 1;
BA_ "Confidence" SG_ 970 APS_appStatusMonitorState 1;
BA_ "Confidence" SG_ 970 APS_vehBehaviorState 1;
BA_ "Confidence" SG_ 970 APS_canMaster 1;
BA_ "Confidence" SG_ 970 APS_appGpioState 1;
BA_ "Confidence" SG_ 970 APS_eacInternalState 1;
BA_ "Confidence" SG_ 970 APS_apbStatusMonitorState 1;
BA_ "Confidence" SG_ 970 APS_apbGpioState 1;
BA_ "Confidence" SG_ 970 APS_locLimitReason 1;
BA_ "Confidence" SG_ 970 APS_appPowerStateRequest 1;
BA_ "Confidence" SG_ 970 APS_appPowerStateReason 1;
BA_ "Confidence" SG_ 970 APS_apbPowerStateRequest 1;
BA_ "Confidence" SG_ 970 APS_apbPowerStateReason 1;
BA_ "Confidence" SG_ 970 APS_heaterStateDebug 1;
BA_ "Confidence" SG_ 970 APS_gpsAntennaState 1;
BA_ "Confidence" SG_ 970 APS_arbState 1;
BA_ "Confidence" SG_ 970 APS_socPowerOperatingMode 1;
BA_ "Confidence" SG_ 970 APS_otherArbState 1;
BA_ "Confidence" SG_ 970 APS_appActivePlannerType 1;
BA_ "Confidence" SG_ 970 APS_apbActivePlannerType 1;
BA_ "Confidence" SG_ 1052 APS_autonomyBehavior 1;
BA_ "Confidence" SG_ 1052 APS_A_manualMotionControlState 1;
BA_ "Confidence" SG_ 1052 APS_B_manualMotionControlState 1;
BA_ "Confidence" SG_ 1510 APS_A_cam12v0Voltage 1;
BA_ "Confidence" SG_ 1510 APS_B_cam12v0Voltage 1;
BA_ "Confidence" SG_ 1510 APS_A_turboMaxTemperature 1;
BA_ "Confidence" SG_ 1510 APS_B_turboMaxTemperature 1;
VAL_ 637 APS_eacAllow 3 "APS_EAC_SNA" 2 "APS_EAC_RESERVED" 1 "APS_EAC_ALLOW" 0 "APS_EAC_INHIBIT" ;
VAL_ 1865 APS_A_lowPowerRequest 5 "APS_LOW_POWER_COLD_RESET" 4 "APS_LOW_POWER_SOC_WARM_RESET" 3 "APS_LOW_POWER_AP_WARM_RESET" 2 "APS_LOW_POWER_OFF" 1 "APS_LOW_POWER_SUSPEND" 0 "APS_LOW_POWER_NONE" ;
VAL_ 1865 APS_A_lowPowerRequestor 10 "APS_LOW_POWER_REQ_COUNT" 9 "APS_LOW_POWER_REQ_SGK_PGOOD_IRQ" 8 "APS_LOW_POWER_REQ_SGK_CONSOLE" 7 "APS_LOW_POWER_REQ_SGK_SLEEP" 6 "APS_LOW_POWER_REQ_SGK_UDS" 5 "APS_LOW_POWER_REQ_SGK_BRIDGE" 4 "APS_LOW_POWER_REQ_SGK_FM" 3 "APS_LOW_POWER_REQ_SGK_POWER" 2 "APS_LOW_POWER_REQ_AP_MAILBOX" 1 "APS_LOW_POWER_REQ_AP_ATF" 0 "APS_LOW_POWER_REQ_NONE" ;
VAL_ 1865 APS_B_lowPowerRequest 5 "APS_LOW_POWER_COLD_RESET" 4 "APS_LOW_POWER_SOC_WARM_RESET" 3 "APS_LOW_POWER_AP_WARM_RESET" 2 "APS_LOW_POWER_OFF" 1 "APS_LOW_POWER_SUSPEND" 0 "APS_LOW_POWER_NONE" ;
VAL_ 1865 APS_B_lowPowerRequestor 10 "APS_LOW_POWER_REQ_COUNT" 9 "APS_LOW_POWER_REQ_SGK_PGOOD_IRQ" 8 "APS_LOW_POWER_REQ_SGK_CONSOLE" 7 "APS_LOW_POWER_REQ_SGK_SLEEP" 6 "APS_LOW_POWER_REQ_SGK_UDS" 5 "APS_LOW_POWER_REQ_SGK_BRIDGE" 4 "APS_LOW_POWER_REQ_SGK_FM" 3 "APS_LOW_POWER_REQ_SGK_POWER" 2 "APS_LOW_POWER_REQ_AP_MAILBOX" 1 "APS_LOW_POWER_REQ_AP_ATF" 0 "APS_LOW_POWER_REQ_NONE" ;
VAL_ 2044 APS_primaryTurbo 2 "TURBO_UNKNOWN" 1 "TURBO_B" 0 "TURBO_A" ;
VAL_ 2044 APS_A_arbState 7 "ARB_STATE_COUNT" 6 "ARB_STATE_UNKNOWN" 5 "ARB_STATE_MIA" 4 "ARB_STATE_FAULT" 3 "ARB_STATE_SECONDARY" 2 "ARB_STATE_PRIMARY" 1 "ARB_STATE_IDLE" 0 "ARB_STATE_INIT" ;
VAL_ 2044 APS_A_powerState 28 "POWER_STATE_AP_FORCE_POWER_OFF" 27 "POWER_STATE_AP_WAIT_FOR_SHUTDOWN_ABORT" 26 "POWER_STATE_AP_IN_LINUX" 25 "POWER_STATE_AP_IDLE" 24 "POWER_STATE_VEH_BOOTING" 23 "POWER_STATE_UNKNOWN" 22 "POWER_STATE_MIA" 21 "POWER_STATE_FAULT" 20 "POWER_STATE_SOC_OFF_ABORT" 19 "POWER_STATE_SOC_OFF" 18 "POWER_STATE_SOC_OFF_READY" 17 "POWER_STATE_AP_SUSPENDED" 16 "POWER_STATE_AP_OFF_ABORT_WAIT_FOR_ACK" 15 "POWER_STATE_AP_OFF_ABORT" 14 "POWER_STATE_AP_OFF_READY_WAIT_FOR_RESPONSE" 13 "POWER_STATE_AP_OFF_READY_WAIT_FOR_ACK" 12 "POWER_STATE_AP_OFF_READY" 11 "POWER_STATE_AP_OFF_PREPARE" 10 "POWER_STATE_AP_WAIT_FOR_SHUTDOWN" 9 "POWER_STATE_AP_ON" 8 "POWER_STATE_AP_IN_COREBOOT" 7 "POWER_STATE_AP_BOOTING" 6 "POWER_STATE_AP_ON_READY_WAIT_FOR_RESPONSE" 5 "POWER_STATE_AP_ON_READY_WAIT_FOR_ACK" 4 "POWER_STATE_AP_ON_READY" 3 "POWER_STATE_AP_ON_PREPARE_WAIT_FOR_RESPONSE" 2 "POWER_STATE_AP_ON_PREPARE_WAIT_FOR_ACK" 1 "POWER_STATE_AP_ON_PREPARE" 0 "POWER_STATE_IDLE" ;
VAL_ 2044 APS_A_sleepState 9 "SLEEP_STATE_COUNT" 8 "SLEEP_STATE_UNKNOWN" 7 "SLEEP_STATE_MIA" 6 "SLEEP_STATE_FAULT" 5 "SLEEP_STATE_ABORT" 4 "SLEEP_STATE_SLEEPING" 3 "SLEEP_STATE_GOING_TO_SLEEP" 2 "SLEEP_STATE_READY" 1 "SLEEP_STATE_WAIT_FOR_BUS_SILENCE" 0 "SLEEP_STATE_IDLE" ;
VAL_ 2044 APS_A_resetState 5 "RESET_STATE_COUNT" 4 "RESET_STATE_UNKNOWN" 3 "RESET_STATE_MIA" 2 "RESET_STATE_FAULT" 1 "RESET_STATE_RESETTING" 0 "RESET_STATE_NOT_RESETTING" ;
VAL_ 2044 APS_A_faultState 27 "FAULT_STATE_COUNT" 26 "FAULT_STATE_UNKNOWN" 25 "FAULT_STATE_MIA" 24 "FAULT_STATE_UNEXPECTED" 23 "FAULT_STATE_SCS" 22 "FAULT_STATE_SOFTWARE_FAULT" 21 "FAULT_STATE_TRIP1_FAULT" 20 "FAULT_STATE_TRIP0_FAULT" 19 "FAULT_STATE_WDT" 18 "FAULT_STATE_CPU_FAULT" 17 "FAULT_STATE_DROOP_TRIP" 16 "FAULT_STATE_DROOP_GPU" 15 "FAULT_STATE_DROOP_CPUCL2" 14 "FAULT_STATE_DROOP_CPUCL1" 13 "FAULT_STATE_DROOP_CPUCL0" 12 "FAULT_STATE_MIF_ECC_AP" 11 "FAULT_STATE_MIF7_DFI_ALERT" 10 "FAULT_STATE_MIF6_DFI_ALERT" 9 "FAULT_STATE_MIF5_DFI_ALERT" 8 "FAULT_STATE_MIF4_DFI_ALERT" 7 "FAULT_STATE_MIF3_DFI_ALERT" 6 "FAULT_STATE_MIF2_DFI_ALERT" 5 "FAULT_STATE_MIF1_DFI_ALERT" 4 "FAULT_STATE_MIF0_DFI_ALERT" 3 "FAULT_STATE_MIF_ECC_UNCORRECTED" 2 "FAULT_STATE_MIF_ECC_CORRECTED" 1 "FAULT_STATE_GIC" 0 "FAULT_STATE_NONE" ;
VAL_ 2044 APS_secondaryTurbo 2 "TURBO_UNKNOWN" 1 "TURBO_B" 0 "TURBO_A" ;
VAL_ 2044 APS_B_arbState 7 "ARB_STATE_COUNT" 6 "ARB_STATE_UNKNOWN" 5 "ARB_STATE_MIA" 4 "ARB_STATE_FAULT" 3 "ARB_STATE_SECONDARY" 2 "ARB_STATE_PRIMARY" 1 "ARB_STATE_IDLE" 0 "ARB_STATE_INIT" ;
VAL_ 2044 APS_B_powerState 28 "POWER_STATE_AP_FORCE_POWER_OFF" 27 "POWER_STATE_AP_WAIT_FOR_SHUTDOWN_ABORT" 26 "POWER_STATE_AP_IN_LINUX" 25 "POWER_STATE_AP_IDLE" 24 "POWER_STATE_VEH_BOOTING" 23 "POWER_STATE_UNKNOWN" 22 "POWER_STATE_MIA" 21 "POWER_STATE_FAULT" 20 "POWER_STATE_SOC_OFF_ABORT" 19 "POWER_STATE_SOC_OFF" 18 "POWER_STATE_SOC_OFF_READY" 17 "POWER_STATE_AP_SUSPENDED" 16 "POWER_STATE_AP_OFF_ABORT_WAIT_FOR_ACK" 15 "POWER_STATE_AP_OFF_ABORT" 14 "POWER_STATE_AP_OFF_READY_WAIT_FOR_RESPONSE" 13 "POWER_STATE_AP_OFF_READY_WAIT_FOR_ACK" 12 "POWER_STATE_AP_OFF_READY" 11 "POWER_STATE_AP_OFF_PREPARE" 10 "POWER_STATE_AP_WAIT_FOR_SHUTDOWN" 9 "POWER_STATE_AP_ON" 8 "POWER_STATE_AP_IN_COREBOOT" 7 "POWER_STATE_AP_BOOTING" 6 "POWER_STATE_AP_ON_READY_WAIT_FOR_RESPONSE" 5 "POWER_STATE_AP_ON_READY_WAIT_FOR_ACK" 4 "POWER_STATE_AP_ON_READY" 3 "POWER_STATE_AP_ON_PREPARE_WAIT_FOR_RESPONSE" 2 "POWER_STATE_AP_ON_PREPARE_WAIT_FOR_ACK" 1 "POWER_STATE_AP_ON_PREPARE" 0 "POWER_STATE_IDLE" ;
VAL_ 2044 APS_B_sleepState 9 "SLEEP_STATE_COUNT" 8 "SLEEP_STATE_UNKNOWN" 7 "SLEEP_STATE_MIA" 6 "SLEEP_STATE_FAULT" 5 "SLEEP_STATE_ABORT" 4 "SLEEP_STATE_SLEEPING" 3 "SLEEP_STATE_GOING_TO_SLEEP" 2 "SLEEP_STATE_READY" 1 "SLEEP_STATE_WAIT_FOR_BUS_SILENCE" 0 "SLEEP_STATE_IDLE" ;
VAL_ 2044 APS_B_resetState 5 "RESET_STATE_COUNT" 4 "RESET_STATE_UNKNOWN" 3 "RESET_STATE_MIA" 2 "RESET_STATE_FAULT" 1 "RESET_STATE_RESETTING" 0 "RESET_STATE_NOT_RESETTING" ;
VAL_ 2044 APS_B_faultState 27 "FAULT_STATE_COUNT" 26 "FAULT_STATE_UNKNOWN" 25 "FAULT_STATE_MIA" 24 "FAULT_STATE_UNEXPECTED" 23 "FAULT_STATE_SCS" 22 "FAULT_STATE_SOFTWARE_FAULT" 21 "FAULT_STATE_TRIP1_FAULT" 20 "FAULT_STATE_TRIP0_FAULT" 19 "FAULT_STATE_WDT" 18 "FAULT_STATE_CPU_FAULT" 17 "FAULT_STATE_DROOP_TRIP" 16 "FAULT_STATE_DROOP_GPU" 15 "FAULT_STATE_DROOP_CPUCL2" 14 "FAULT_STATE_DROOP_CPUCL1" 13 "FAULT_STATE_DROOP_CPUCL0" 12 "FAULT_STATE_MIF_ECC_AP" 11 "FAULT_STATE_MIF7_DFI_ALERT" 10 "FAULT_STATE_MIF6_DFI_ALERT" 9 "FAULT_STATE_MIF5_DFI_ALERT" 8 "FAULT_STATE_MIF4_DFI_ALERT" 7 "FAULT_STATE_MIF3_DFI_ALERT" 6 "FAULT_STATE_MIF2_DFI_ALERT" 5 "FAULT_STATE_MIF1_DFI_ALERT" 4 "FAULT_STATE_MIF0_DFI_ALERT" 3 "FAULT_STATE_MIF_ECC_UNCORRECTED" 2 "FAULT_STATE_MIF_ECC_CORRECTED" 1 "FAULT_STATE_GIC" 0 "FAULT_STATE_NONE" ;
VAL_ 2044 APS_A_autosteerMonitorState 5 "AUTOSTEER_MONITOR_COUNT" 4 "AUTOSTEER_MONITOR_MIA" 3 "AUTOSTEER_MONITOR_TOI_TRIGGER" 2 "AUTOSTEER_MONITOR_WAIT_FOR_MIA" 1 "AUTOSTEER_MONITOR_ACTIVE" 0 "AUTOSTEER_MONITOR_IDLE" ;
VAL_ 2044 APS_B_autosteerMonitorState 5 "AUTOSTEER_MONITOR_COUNT" 4 "AUTOSTEER_MONITOR_MIA" 3 "AUTOSTEER_MONITOR_TOI_TRIGGER" 2 "AUTOSTEER_MONITOR_WAIT_FOR_MIA" 1 "AUTOSTEER_MONITOR_ACTIVE" 0 "AUTOSTEER_MONITOR_IDLE" ;
VAL_ 2044 APS_eplannerState 6 "APS_EPLANNER_NUM_STATES" 5 "APS_EPLANNER_STATE_EXECUTING_BOOT_FIXED_TRAJ" 4 "APS_EPLANNER_STATE_EXECUTING_FIXED_TRAJ" 3 "APS_EPLANNER_STATE_EXECUTING_PLAN_TRAJ" 2 "APS_EPLANNER_STATE_VALID_PLAN" 1 "APS_EPLANNER_STATE_READY" 0 "APS_EPLANNER_STATE_INIT" ;
VAL_ 970 APS_appStatusMonitorState 7 "STATUS_MONITOR_NUM_STATES" 6 "STATUS_MONITOR_STATE_RECOVERY" 5 "STATUS_MONITOR_STATE_SHUTTING_DOWN" 4 "STATUS_MONITOR_STATE_CRITICAL" 3 "STATUS_MONITOR_STATE_NOMINAL" 2 "STATUS_MONITOR_STATE_INIT" 1 "STATUS_MONITOR_STATE_PWR_OFF" 0 "STATUS_MONITOR_STATE_UNKNOWN" ;
VAL_ 970 APS_vehBehaviorState 8 "VEH_BEHAVIOR_NUM_STATES" 7 "VEH_BEHAVIOR_STATE_SYSTEM_FAULT" 6 "VEH_BEHAVIOR_STATE_APS_OVERRIDE" 5 "VEH_BEHAVIOR_STATE_APS_FAIL_SAFE" 4 "VEH_BEHAVIOR_STATE_APS_BRIDGE_APB" 3 "VEH_BEHAVIOR_STATE_APS_BRIDGE_APP" 2 "VEH_BEHAVIOR_STATE_APS_CONTROL" 1 "VEH_BEHAVIOR_STATE_APS_AVAILABLE" 0 "VEH_BEHAVIOR_STATE_UNKNOWN" ;
VAL_ 970 APS_canMaster 3 "CAN_MASTER_SNA" 2 "CAN_MASTER_APB" 1 "CAN_MASTER_APP" 0 "CAN_MASTER_APS" ;
VAL_ 970 APS_appGpioState 3 "AP_GPIO_STATE_HEALTHY" 2 "AP_GPIO_STATE_CRITICAL" 1 "AP_GPIO_STATE_DISABLED" 0 "AP_GPIO_STATE_PWR_DOWN_REBOOT" ;
VAL_ 970 APS_eacInternalState 7 "APS_EAC_NUM_STATES" 6 "APS_EAC_STATE_LSS" 5 "APS_EAC_STATE_OVERRIDE" 4 "APS_EAC_STATE_INHIBIT" 3 "APS_EAC_STATE_AUTOPARK" 2 "APS_EAC_STATE_CONTINUOUS" 1 "APS_EAC_STATE_MOMENTARY" 0 "APS_EAC_STATE_INIT" ;
VAL_ 970 APS_apbStatusMonitorState 7 "STATUS_MONITOR_NUM_STATES" 6 "STATUS_MONITOR_STATE_RECOVERY" 5 "STATUS_MONITOR_STATE_SHUTTING_DOWN" 4 "STATUS_MONITOR_STATE_CRITICAL" 3 "STATUS_MONITOR_STATE_NOMINAL" 2 "STATUS_MONITOR_STATE_INIT" 1 "STATUS_MONITOR_STATE_PWR_OFF" 0 "STATUS_MONITOR_STATE_UNKNOWN" ;
VAL_ 970 APS_apbGpioState 3 "AP_GPIO_STATE_HEALTHY" 2 "AP_GPIO_STATE_CRITICAL" 1 "AP_GPIO_STATE_DISABLED" 0 "AP_GPIO_STATE_PWR_DOWN_REBOOT" ;
VAL_ 970 APS_locLimitReason 7 "LOC_LIMITS_EXTENDED" 6 "LOC_MONITOR_UNAVAILABLE" 5 "NO_RADAR_TARGET" 4 "RADAR_NOT_HEALTHY" 3 "PRIMARY_AP_NOT_HEALTHY" 2 "ACC_AND_AEB_UNAVAILABLE" 1 "NOT_IN_DRIVE" 0 "NOMINAL_DEFAULT" ;
VAL_ 970 APS_appPowerStateRequest 3 "AP_POWER_STATE_SLEEP" 2 "AP_POWER_STATE_SUSPEND" 1 "AP_POWER_STATE_SENTRY" 0 "AP_POWER_STATE_NOMINAL" ;
VAL_ 970 APS_appPowerStateReason 12 "UI_SUMMON_STANDBY_MODE_ENABLED" 11 "SLEEP_REQUEST_RECVD" 10 "AP_POWER_REQUEST_OVERHEATED" 9 "LOADSHED_POWER_REQUEST_PENDING" 8 "VC_POWER_REQUEST" 7 "AP_POWER_REQUEST_OVERRIDE" 6 "AP_POWER_REQUEST_OVERHEATING" 5 "AP_POWER_REQUEST_HYSTERESIS" 4 "GTW_GOTO_FULL_POWER" 3 "AP_NOT_IN_PARK" 2 "AP_NM_REASON_SET" 1 "AP_WDOG_UNHEALTHY" 0 "UI_POWER_STATE_REQUEST" ;
VAL_ 970 APS_apbPowerStateRequest 3 "AP_POWER_STATE_SLEEP" 2 "AP_POWER_STATE_SUSPEND" 1 "AP_POWER_STATE_SENTRY" 0 "AP_POWER_STATE_NOMINAL" ;
VAL_ 970 APS_apbPowerStateReason 12 "UI_SUMMON_STANDBY_MODE_ENABLED" 11 "SLEEP_REQUEST_RECVD" 10 "AP_POWER_REQUEST_OVERHEATED" 9 "LOADSHED_POWER_REQUEST_PENDING" 8 "VC_POWER_REQUEST" 7 "AP_POWER_REQUEST_OVERRIDE" 6 "AP_POWER_REQUEST_OVERHEATING" 5 "AP_POWER_REQUEST_HYSTERESIS" 4 "GTW_GOTO_FULL_POWER" 3 "AP_NOT_IN_PARK" 2 "AP_NM_REASON_SET" 1 "AP_WDOG_UNHEALTHY" 0 "UI_POWER_STATE_REQUEST" ;
VAL_ 970 APS_heaterStateDebug 7 "APS_HEATER_SNA" 4 "APS_HEATER_FAULT_SHORT" 3 "APS_HEATER_FAULT_OPEN" 2 "APS_HEATER_ON_NOT_HEATING" 1 "APS_HEATER_ON_HEATING" 0 "APS_HEATER_OFF" ;
VAL_ 970 APS_gpsAntennaState 2 "GPS_ANTENNA_CONNECTED" 1 "GPS_ANTENNA_UNKNOWN" 0 "GPS_ANTENNA_DISCONNECTED" ;
VAL_ 970 APS_arbState 7 "ARB_STATE_N_COUNT" 6 "ARB_STATE_N_UNKNOWN" 5 "ARB_STATE_N_MIA" 4 "ARB_STATE_N_FAULT" 3 "ARB_STATE_N_SECONDARY" 2 "ARB_STATE_N_PRIMARY" 1 "ARB_STATE_N_IDLE" 0 "ARB_STATE_N_INIT" ;
VAL_ 970 APS_socPowerOperatingMode 2 "APS_DUAL_SOC" 1 "APS_SINGLE_SOC" 0 "APS_UNKNOWN" ;
VAL_ 970 APS_otherArbState 7 "ARB_STATE_N_COUNT" 6 "ARB_STATE_N_UNKNOWN" 5 "ARB_STATE_N_MIA" 4 "ARB_STATE_N_FAULT" 3 "ARB_STATE_N_SECONDARY" 2 "ARB_STATE_N_PRIMARY" 1 "ARB_STATE_N_IDLE" 0 "ARB_STATE_N_INIT" ;
VAL_ 970 APS_appActivePlannerType 4 "BOOT_FIXED_PLANNER" 3 "EMERGENCY_PLANNER" 2 "FIXED_PLANNER" 1 "AUTOSTEER_MON" 0 "NO_PLANNER" ;
VAL_ 970 APS_apbActivePlannerType 4 "BOOT_FIXED_PLANNER" 3 "EMERGENCY_PLANNER" 2 "FIXED_PLANNER" 1 "AUTOSTEER_MON" 0 "NO_PLANNER" ;
VAL_ 1052 APS_autonomyBehavior 2 "DRIVERLESS_NO_TAKEOVER" 1 "DRIVERLESS_TAKEOVER" 0 "DRIVER" ;
VAL_ 1052 APS_A_manualMotionControlState 5 "MANUAL_MOTION_CONTROL_STATE_COUNT" 4 "MANUAL_MOTION_CONTROL_STATE_MIA" 3 "MANUAL_MOTION_CONTROL_STATE_ABORTED" 2 "MANUAL_MOTION_CONTROL_STATE_ACTUATE" 1 "MANUAL_MOTION_CONTROL_STATE_FAULTED" 0 "MANUAL_MOTION_CONTROL_STATE_INIT" ;
VAL_ 1052 APS_B_manualMotionControlState 5 "MANUAL_MOTION_CONTROL_STATE_COUNT" 4 "MANUAL_MOTION_CONTROL_STATE_MIA" 3 "MANUAL_MOTION_CONTROL_STATE_ABORTED" 2 "MANUAL_MOTION_CONTROL_STATE_ACTUATE" 1 "MANUAL_MOTION_CONTROL_STATE_FAULTED" 0 "MANUAL_MOTION_CONTROL_STATE_INIT" ;
